VERSION ""

NS_ :

BS_:

BU_: HCM IPMA_ADAS PSCM ABS_ESC PCM ECM_HEV VDM CMR_DSMC SOBDMC_HPCM GWM _delete AWD_DLCM GENERIC TSTR
VAL_TABLE_ Dimming_Lvl_RqMnu 31 "NotUsed_11" 30 "NotUsed_10" 29 "NotUsed_9" 28 "NotUsed_8" 27 "NotUsed_7" 26 "NotUsed_6" 25 "NotUsed_5" 24 "NotUsed_4" 23 "NotUsed_3" 22 "NotUsed_2" 21 "NotUsed_1" 20 "Up" 19 "Down" 18 "Day_6" 17 "Day_5" 16 "Day_4" 15 "Day_3" 14 "Day_2" 13 "Day_1" 12 "Night_12" 11 "Night_11" 10 "Night_10" 9 "Night_9" 8 "Night_8" 7 "Night_7" 6 "Night_6" 5 "Night_5" 4 "Night_4" 3 "Night_3" 2 "Night_2" 1 "Night_1" 0 "NotPressed" ;
VAL_TABLE_ Null_Reset 1 "Reset" 0 "Null" ;
VAL_TABLE_ Null_Off_LowHigh 3 "High" 2 "Low" 1 "Off" 0 "Null" ;
VAL_TABLE_ Null_Off_On 3 "NotUsed" 2 "On" 1 "Off" 0 "Null" ;
VAL_TABLE_ NoData_Faulty_1FF_1FE 511 "Faulty" 510 "NoDataExists" ;
VAL_TABLE_ KeylessIdl_D_Rq 3 "Cancel" 2 "IgnitionOff" 1 "Active" 0 "Inactive" ;
VAL_TABLE_ KeyPadCodeDgt1_D_Stat 15 "NotUsed_4" 14 "NotUsed_3" 13 "NotUsed_2" 12 "NotUsed_1" 11 "Button7_8and9_0" 10 "Button0" 9 "Button9_0or9" 8 "Button8" 7 "Button7_8or7" 6 "Button6" 5 "Button5_6or5" 4 "Button4" 3 "Button3_4or3" 2 "Button2" 1 "Button1_2or1" 0 "EndofString" ;
VAL_TABLE_ Check_KeyCode 7 "Unused_2" 6 "Cancel" 5 "Set_Keycode" 4 "RKE" 3 "Null" 2 "Key" 1 "Erase_KeyCode" 0 "Check_KeyCode" ;
VAL_TABLE_ HybMdeGzg_D_Rq 7 "NotUsed_2" 6 "NotUsed_1" 5 "EV_Override_Mode" 4 "EV_Charge_Mode" 3 "EV_Later_Mode" 2 "EV_Now_Mode" 1 "EV_Auto_Mode" 0 "Null" ;
VAL_TABLE_ Null_NotAvail_Avail 3 "NotUsed" 2 "Available" 1 "NotAvailable" 0 "Null" ;

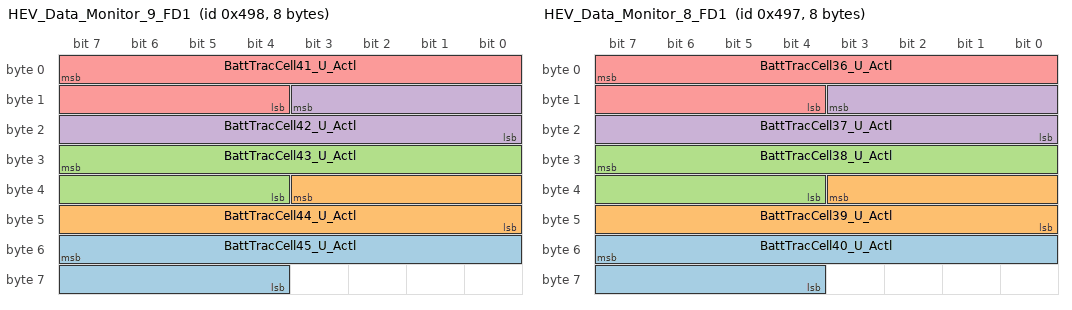
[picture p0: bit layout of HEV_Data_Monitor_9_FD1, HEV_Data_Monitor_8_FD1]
BO_ 1176 HEV_Data_Monitor_9_FD1: 8 GWM
 SG_ BattTracCell45_U_Actl : 55|12@0+ (0.001,1) [1|5.093] "volt"  SOBDMC_HPCM
 SG_ BattTracCell44_U_Actl : 35|12@0+ (0.001,1) [1|5.093] "volt"  SOBDMC_HPCM
 SG_ BattTracCell43_U_Actl : 31|12@0+ (0.001,1) [1|5.093] "volt"  SOBDMC_HPCM
 SG_ BattTracCell42_U_Actl : 11|12@0+ (0.001,1) [1|5.093] "volt"  SOBDMC_HPCM
 SG_ BattTracCell41_U_Actl : 7|12@0+ (0.001,1) [1|5.093] "volt"  SOBDMC_HPCM

BO_ 1175 HEV_Data_Monitor_8_FD1: 8 GWM
 SG_ BattTracCell40_U_Actl : 55|12@0+ (0.001,1) [1|5.093] "volt"  SOBDMC_HPCM
 SG_ BattTracCell39_U_Actl : 35|12@0+ (0.001,1) [1|5.093] "volt"  SOBDMC_HPCM
 SG_ BattTracCell38_U_Actl : 31|12@0+ (0.001,1) [1|5.093] "volt"  SOBDMC_HPCM
 SG_ BattTracCell37_U_Actl : 11|12@0+ (0.001,1) [1|5.093] "volt"  SOBDMC_HPCM
 SG_ BattTracCell36_U_Actl : 7|12@0+ (0.001,1) [1|5.093] "volt"  SOBDMC_HPCM

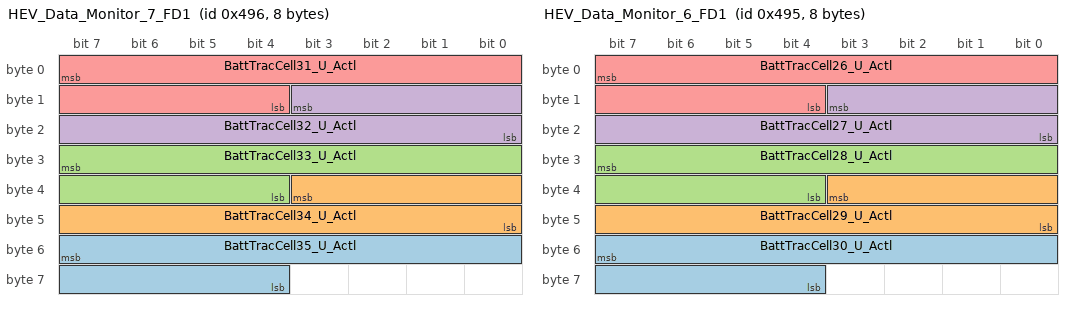
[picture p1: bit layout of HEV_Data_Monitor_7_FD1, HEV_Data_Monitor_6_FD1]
BO_ 1174 HEV_Data_Monitor_7_FD1: 8 GWM
 SG_ BattTracCell35_U_Actl : 55|12@0+ (0.001,1) [1|5.093] "volt"  SOBDMC_HPCM
 SG_ BattTracCell34_U_Actl : 35|12@0+ (0.001,1) [1|5.093] "volt"  SOBDMC_HPCM
 SG_ BattTracCell33_U_Actl : 31|12@0+ (0.001,1) [1|5.093] "volt"  SOBDMC_HPCM
 SG_ BattTracCell32_U_Actl : 11|12@0+ (0.001,1) [1|5.093] "volt"  SOBDMC_HPCM
 SG_ BattTracCell31_U_Actl : 7|12@0+ (0.001,1) [1|5.093] "volt"  SOBDMC_HPCM

BO_ 1173 HEV_Data_Monitor_6_FD1: 8 GWM
 SG_ BattTracCell30_U_Actl : 55|12@0+ (0.001,1) [1|5.093] "volt"  SOBDMC_HPCM
 SG_ BattTracCell29_U_Actl : 35|12@0+ (0.001,1) [1|5.093] "volt"  SOBDMC_HPCM
 SG_ BattTracCell28_U_Actl : 31|12@0+ (0.001,1) [1|5.093] "volt"  SOBDMC_HPCM
 SG_ BattTracCell27_U_Actl : 11|12@0+ (0.001,1) [1|5.093] "volt"  SOBDMC_HPCM
 SG_ BattTracCell26_U_Actl : 7|12@0+ (0.001,1) [1|5.093] "volt"  SOBDMC_HPCM

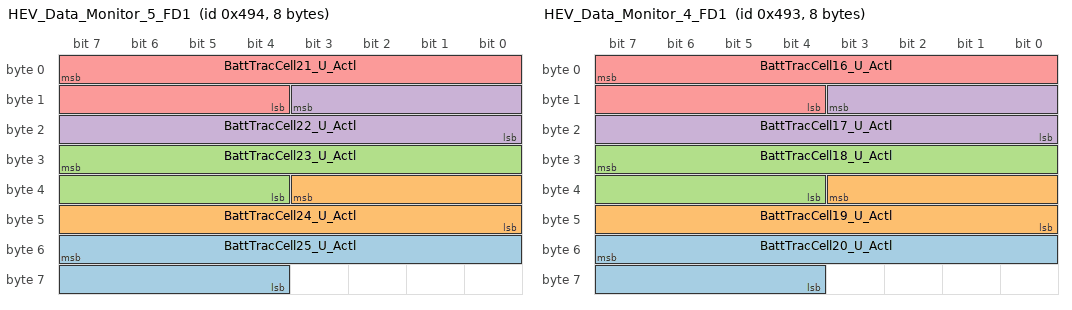
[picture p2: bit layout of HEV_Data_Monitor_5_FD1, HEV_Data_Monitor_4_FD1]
BO_ 1172 HEV_Data_Monitor_5_FD1: 8 GWM
 SG_ BattTracCell25_U_Actl : 55|12@0+ (0.001,1) [1|5.093] "volt"  SOBDMC_HPCM
 SG_ BattTracCell24_U_Actl : 35|12@0+ (0.001,1) [1|5.093] "volt"  SOBDMC_HPCM
 SG_ BattTracCell23_U_Actl : 31|12@0+ (0.001,1) [1|5.093] "volt"  SOBDMC_HPCM
 SG_ BattTracCell22_U_Actl : 11|12@0+ (0.001,1) [1|5.093] "volt"  SOBDMC_HPCM
 SG_ BattTracCell21_U_Actl : 7|12@0+ (0.001,1) [1|5.093] "volt"  SOBDMC_HPCM

BO_ 1171 HEV_Data_Monitor_4_FD1: 8 GWM
 SG_ BattTracCell20_U_Actl : 55|12@0+ (0.001,1) [1|5.093] "volt"  SOBDMC_HPCM
 SG_ BattTracCell19_U_Actl : 35|12@0+ (0.001,1) [1|5.093] "volt"  SOBDMC_HPCM
 SG_ BattTracCell18_U_Actl : 31|12@0+ (0.001,1) [1|5.093] "volt"  SOBDMC_HPCM
 SG_ BattTracCell17_U_Actl : 11|12@0+ (0.001,1) [1|5.093] "volt"  SOBDMC_HPCM
 SG_ BattTracCell16_U_Actl : 7|12@0+ (0.001,1) [1|5.093] "volt"  SOBDMC_HPCM

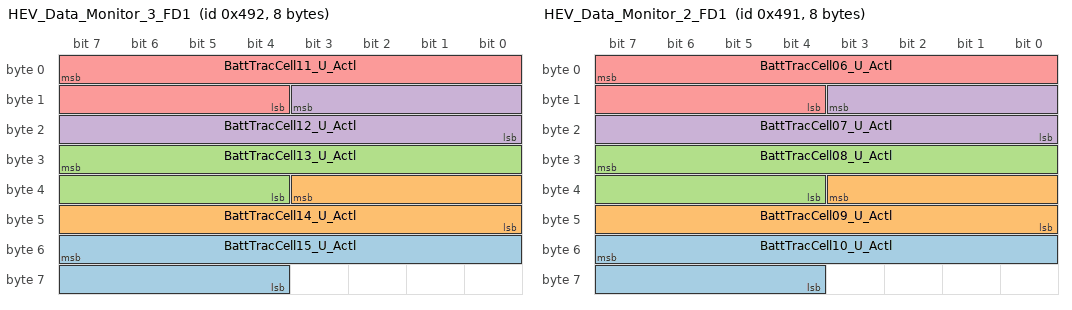
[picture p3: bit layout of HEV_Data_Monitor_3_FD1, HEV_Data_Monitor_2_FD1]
BO_ 1170 HEV_Data_Monitor_3_FD1: 8 GWM
 SG_ BattTracCell15_U_Actl : 55|12@0+ (0.001,1) [1|5.093] "volt"  SOBDMC_HPCM
 SG_ BattTracCell14_U_Actl : 35|12@0+ (0.001,1) [1|5.093] "volt"  SOBDMC_HPCM
 SG_ BattTracCell13_U_Actl : 31|12@0+ (0.001,1) [1|5.093] "volt"  SOBDMC_HPCM
 SG_ BattTracCell12_U_Actl : 11|12@0+ (0.001,1) [1|5.093] "volt"  SOBDMC_HPCM
 SG_ BattTracCell11_U_Actl : 7|12@0+ (0.001,1) [1|5.093] "volt"  SOBDMC_HPCM

BO_ 1169 HEV_Data_Monitor_2_FD1: 8 GWM
 SG_ BattTracCell10_U_Actl : 55|12@0+ (0.001,1) [1|5.093] "volt"  SOBDMC_HPCM
 SG_ BattTracCell09_U_Actl : 35|12@0+ (0.001,1) [1|5.093] "volt"  SOBDMC_HPCM
 SG_ BattTracCell08_U_Actl : 31|12@0+ (0.001,1) [1|5.093] "volt"  SOBDMC_HPCM
 SG_ BattTracCell07_U_Actl : 11|12@0+ (0.001,1) [1|5.093] "volt"  SOBDMC_HPCM
 SG_ BattTracCell06_U_Actl : 7|12@0+ (0.001,1) [1|5.093] "volt"  SOBDMC_HPCM

BO_ 1188 HEV_Data_Monitor_21_FD1: 8 GWM
 SG_ BattTracTe13_Te_Actl : 55|8@0+ (1,-50) [-50|203] "degC"  SOBDMC_HPCM
 SG_ BattTracTe12_Te_Actl : 47|8@0+ (1,-50) [-50|203] "degC"  SOBDMC_HPCM
 SG_ BattTracTe11_Te_Actl : 39|8@0+ (1,-50) [-50|203] "degC"  SOBDMC_HPCM
 SG_ BattTracTe10_Te_Actl : 31|8@0+ (1,-50) [-50|203] "degC"  SOBDMC_HPCM
 SG_ BattTracTe09_Te_Actl : 23|8@0+ (1,-50) [-50|203] "degC"  SOBDMC_HPCM
 SG_ BattTracTe08_Te_Actl : 15|8@0+ (1,-50) [-50|203] "degC"  SOBDMC_HPCM
 SG_ BattTracTe07_Te_Actl : 7|8@0+ (1,-50) [-50|203] "degC"  SOBDMC_HPCM

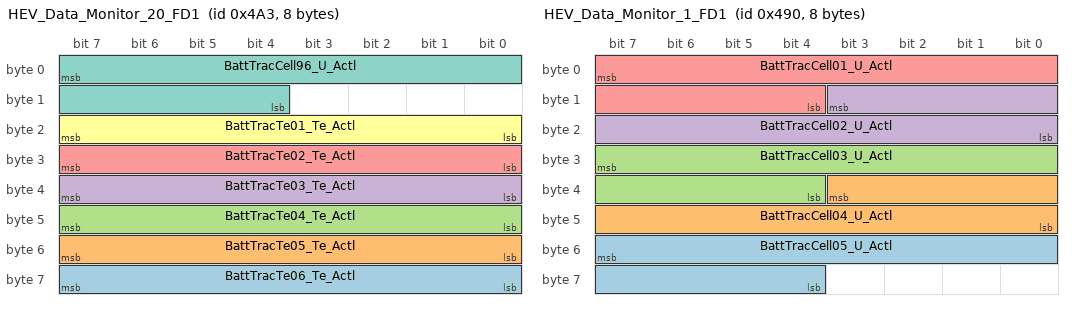
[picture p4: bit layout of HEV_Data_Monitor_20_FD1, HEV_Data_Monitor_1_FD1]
BO_ 1187 HEV_Data_Monitor_20_FD1: 8 GWM
 SG_ BattTracTe06_Te_Actl : 63|8@0+ (1,-50) [-50|203] "degC"  SOBDMC_HPCM
 SG_ BattTracTe05_Te_Actl : 55|8@0+ (1,-50) [-50|203] "degC"  SOBDMC_HPCM
 SG_ BattTracTe04_Te_Actl : 47|8@0+ (1,-50) [-50|203] "degC"  SOBDMC_HPCM
 SG_ BattTracTe03_Te_Actl : 39|8@0+ (1,-50) [-50|203] "degC"  SOBDMC_HPCM
 SG_ BattTracTe02_Te_Actl : 31|8@0+ (1,-50) [-50|203] "degC"  SOBDMC_HPCM
 SG_ BattTracTe01_Te_Actl : 23|8@0+ (1,-50) [-50|203] "degC"  SOBDMC_HPCM
 SG_ BattTracCell96_U_Actl : 7|12@0+ (0.001,1) [1|5.093] "volt"  SOBDMC_HPCM

BO_ 1168 HEV_Data_Monitor_1_FD1: 8 GWM
 SG_ BattTracCell05_U_Actl : 55|12@0+ (0.001,1) [1|5.093] "volt"  SOBDMC_HPCM
 SG_ BattTracCell04_U_Actl : 35|12@0+ (0.001,1) [1|5.093] "volt"  SOBDMC_HPCM
 SG_ BattTracCell03_U_Actl : 31|12@0+ (0.001,1) [1|5.093] "volt"  SOBDMC_HPCM
 SG_ BattTracCell02_U_Actl : 11|12@0+ (0.001,1) [1|5.093] "volt"  SOBDMC_HPCM
 SG_ BattTracCell01_U_Actl : 7|12@0+ (0.001,1) [1|5.093] "volt"  SOBDMC_HPCM

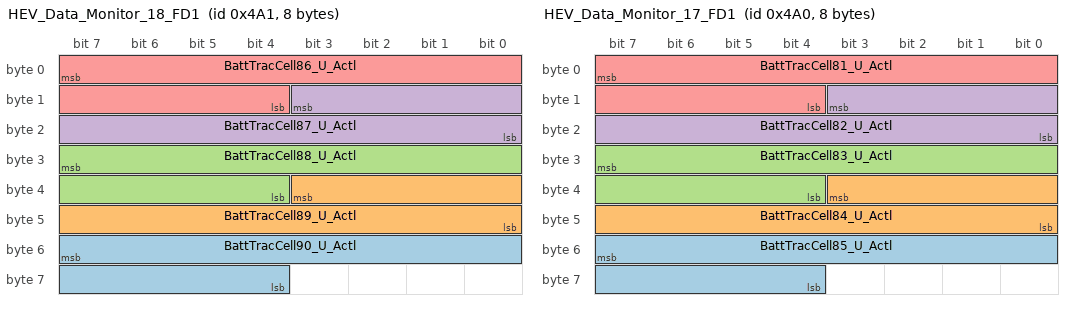
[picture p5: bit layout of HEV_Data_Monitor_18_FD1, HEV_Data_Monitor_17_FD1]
BO_ 1185 HEV_Data_Monitor_18_FD1: 8 GWM
 SG_ BattTracCell90_U_Actl : 55|12@0+ (0.001,1) [1|5.093] "volt"  SOBDMC_HPCM
 SG_ BattTracCell89_U_Actl : 35|12@0+ (0.001,1) [1|5.093] "volt"  SOBDMC_HPCM
 SG_ BattTracCell88_U_Actl : 31|12@0+ (0.001,1) [1|5.093] "volt"  SOBDMC_HPCM
 SG_ BattTracCell87_U_Actl : 11|12@0+ (0.001,1) [1|5.093] "volt"  SOBDMC_HPCM
 SG_ BattTracCell86_U_Actl : 7|12@0+ (0.001,1) [1|5.093] "volt"  SOBDMC_HPCM

BO_ 1184 HEV_Data_Monitor_17_FD1: 8 GWM
 SG_ BattTracCell85_U_Actl : 55|12@0+ (0.001,1) [1|5.093] "volt"  SOBDMC_HPCM
 SG_ BattTracCell84_U_Actl : 35|12@0+ (0.001,1) [1|5.093] "volt"  SOBDMC_HPCM
 SG_ BattTracCell83_U_Actl : 31|12@0+ (0.001,1) [1|5.093] "volt"  SOBDMC_HPCM
 SG_ BattTracCell82_U_Actl : 11|12@0+ (0.001,1) [1|5.093] "volt"  SOBDMC_HPCM
 SG_ BattTracCell81_U_Actl : 7|12@0+ (0.001,1) [1|5.093] "volt"  SOBDMC_HPCM

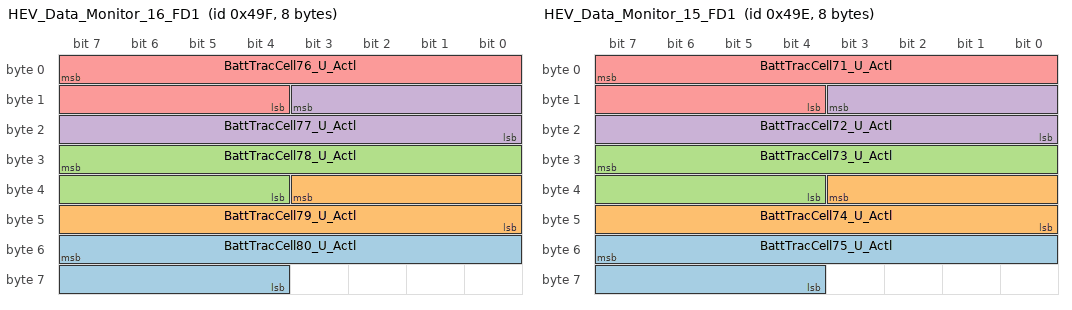
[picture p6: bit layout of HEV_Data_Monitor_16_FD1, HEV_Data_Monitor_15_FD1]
BO_ 1183 HEV_Data_Monitor_16_FD1: 8 GWM
 SG_ BattTracCell80_U_Actl : 55|12@0+ (0.001,1) [1|5.093] "volt"  SOBDMC_HPCM
 SG_ BattTracCell79_U_Actl : 35|12@0+ (0.001,1) [1|5.093] "volt"  SOBDMC_HPCM
 SG_ BattTracCell78_U_Actl : 31|12@0+ (0.001,1) [1|5.093] "volt"  SOBDMC_HPCM
 SG_ BattTracCell77_U_Actl : 11|12@0+ (0.001,1) [1|5.093] "volt"  SOBDMC_HPCM
 SG_ BattTracCell76_U_Actl : 7|12@0+ (0.001,1) [1|5.093] "volt"  SOBDMC_HPCM

BO_ 1182 HEV_Data_Monitor_15_FD1: 8 GWM
 SG_ BattTracCell75_U_Actl : 55|12@0+ (0.001,1) [1|5.093] "volt"  SOBDMC_HPCM
 SG_ BattTracCell74_U_Actl : 35|12@0+ (0.001,1) [1|5.093] "volt"  SOBDMC_HPCM
 SG_ BattTracCell73_U_Actl : 31|12@0+ (0.001,1) [1|5.093] "volt"  SOBDMC_HPCM
 SG_ BattTracCell72_U_Actl : 11|12@0+ (0.001,1) [1|5.093] "volt"  SOBDMC_HPCM
 SG_ BattTracCell71_U_Actl : 7|12@0+ (0.001,1) [1|5.093] "volt"  SOBDMC_HPCM

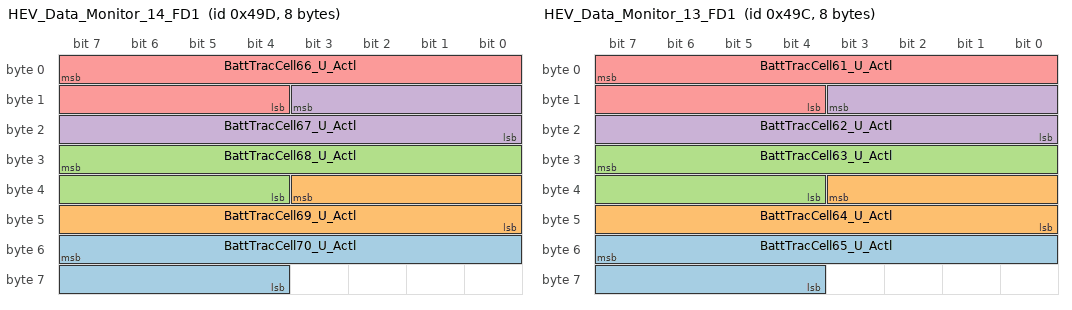
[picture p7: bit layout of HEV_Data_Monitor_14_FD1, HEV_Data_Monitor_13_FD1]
BO_ 1181 HEV_Data_Monitor_14_FD1: 8 GWM
 SG_ BattTracCell70_U_Actl : 55|12@0+ (0.001,1) [1|5.093] "volt"  SOBDMC_HPCM
 SG_ BattTracCell69_U_Actl : 35|12@0+ (0.001,1) [1|5.093] "volt"  SOBDMC_HPCM
 SG_ BattTracCell68_U_Actl : 31|12@0+ (0.001,1) [1|5.093] "volt"  SOBDMC_HPCM
 SG_ BattTracCell67_U_Actl : 11|12@0+ (0.001,1) [1|5.093] "volt"  SOBDMC_HPCM
 SG_ BattTracCell66_U_Actl : 7|12@0+ (0.001,1) [1|5.093] "volt"  SOBDMC_HPCM

BO_ 1180 HEV_Data_Monitor_13_FD1: 8 GWM
 SG_ BattTracCell65_U_Actl : 55|12@0+ (0.001,1) [1|5.093] "volt"  SOBDMC_HPCM
 SG_ BattTracCell64_U_Actl : 35|12@0+ (0.001,1) [1|5.093] "volt"  SOBDMC_HPCM
 SG_ BattTracCell63_U_Actl : 31|12@0+ (0.001,1) [1|5.093] "volt"  SOBDMC_HPCM
 SG_ BattTracCell62_U_Actl : 11|12@0+ (0.001,1) [1|5.093] "volt"  SOBDMC_HPCM
 SG_ BattTracCell61_U_Actl : 7|12@0+ (0.001,1) [1|5.093] "volt"  SOBDMC_HPCM

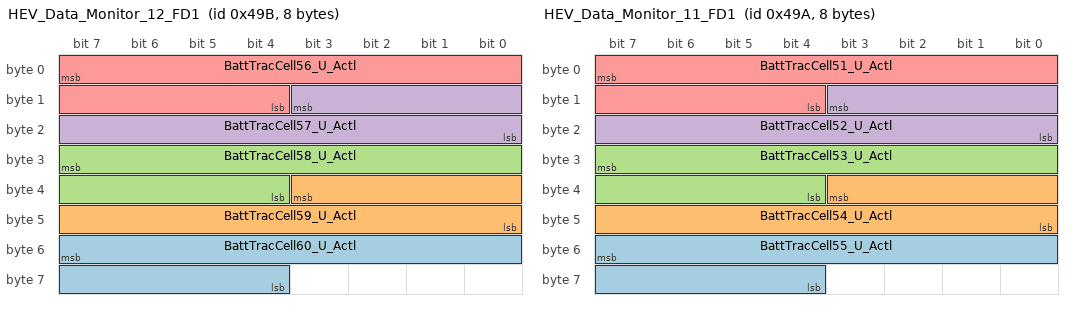
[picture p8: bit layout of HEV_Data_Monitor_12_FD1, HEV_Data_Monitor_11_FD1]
BO_ 1179 HEV_Data_Monitor_12_FD1: 8 GWM
 SG_ BattTracCell60_U_Actl : 55|12@0+ (0.001,1) [1|5.093] "volt"  SOBDMC_HPCM
 SG_ BattTracCell59_U_Actl : 35|12@0+ (0.001,1) [1|5.093] "volt"  SOBDMC_HPCM
 SG_ BattTracCell58_U_Actl : 31|12@0+ (0.001,1) [1|5.093] "volt"  SOBDMC_HPCM
 SG_ BattTracCell57_U_Actl : 11|12@0+ (0.001,1) [1|5.093] "volt"  SOBDMC_HPCM
 SG_ BattTracCell56_U_Actl : 7|12@0+ (0.001,1) [1|5.093] "volt"  SOBDMC_HPCM

BO_ 1178 HEV_Data_Monitor_11_FD1: 8 GWM
 SG_ BattTracCell55_U_Actl : 55|12@0+ (0.001,1) [1|5.093] "volt"  SOBDMC_HPCM
 SG_ BattTracCell54_U_Actl : 35|12@0+ (0.001,1) [1|5.093] "volt"  SOBDMC_HPCM
 SG_ BattTracCell53_U_Actl : 31|12@0+ (0.001,1) [1|5.093] "volt"  SOBDMC_HPCM
 SG_ BattTracCell52_U_Actl : 11|12@0+ (0.001,1) [1|5.093] "volt"  SOBDMC_HPCM
 SG_ BattTracCell51_U_Actl : 7|12@0+ (0.001,1) [1|5.093] "volt"  SOBDMC_HPCM

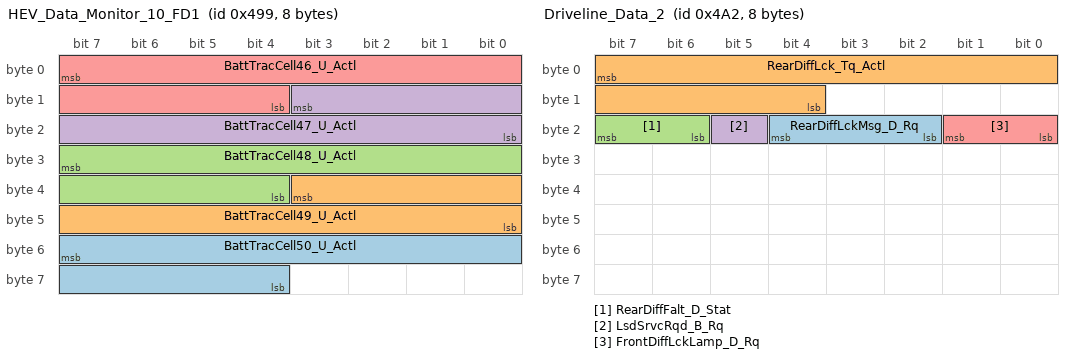
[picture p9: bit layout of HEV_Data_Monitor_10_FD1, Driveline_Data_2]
BO_ 1177 HEV_Data_Monitor_10_FD1: 8 GWM
 SG_ BattTracCell50_U_Actl : 55|12@0+ (0.001,1) [1|5.093] "volt"  SOBDMC_HPCM
 SG_ BattTracCell49_U_Actl : 35|12@0+ (0.001,1) [1|5.093] "volt"  SOBDMC_HPCM
 SG_ BattTracCell48_U_Actl : 31|12@0+ (0.001,1) [1|5.093] "volt"  SOBDMC_HPCM
 SG_ BattTracCell47_U_Actl : 11|12@0+ (0.001,1) [1|5.093] "volt"  SOBDMC_HPCM
 SG_ BattTracCell46_U_Actl : 7|12@0+ (0.001,1) [1|5.093] "volt"  SOBDMC_HPCM

BO_ 1186 Driveline_Data_2: 8 SOBDMC_HPCM
 SG_ RearDiffLckMsg_D_Rq : 20|3@0+ (1,0) [0|7] "SED"  GWM
 SG_ RearDiffLck_Tq_Actl : 7|12@0+ (1,0) [0|4093] "Nm"  GWM
 SG_ RearDiffFalt_D_Stat : 23|2@0+ (1,0) [0|3] "SED"  GWM
 SG_ LsdSrvcRqd_B_Rq : 21|1@0+ (1,0) [0|1] "SED"  GWM
 SG_ FrontDiffLckLamp_D_Rq : 17|2@0+ (1,0) [0|3] "SED"  GWM

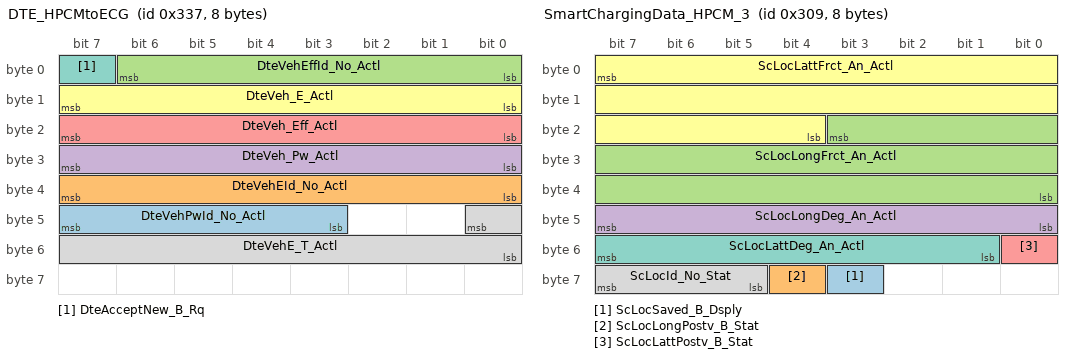
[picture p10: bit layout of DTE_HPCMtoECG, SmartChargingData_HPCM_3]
BO_ 823 DTE_HPCMtoECG: 8 SOBDMC_HPCM
 SG_ DteVehPwId_No_Actl : 47|5@0+ (1,0) [0|31] "unitless"  GWM
 SG_ DteVehEId_No_Actl : 39|8@0+ (1,0) [0|255] "unitless"  GWM
 SG_ DteVehEffId_No_Actl : 6|7@0+ (1,0) [0|127] "unitless"  GWM
 SG_ DteVeh_Pw_Actl : 31|8@0+ (50,0) [0|12750] "watts"  GWM
 SG_ DteVeh_Eff_Actl : 23|8@0+ (10,-1000) [-1000|1550] "watt*hour/km"  GWM
 SG_ DteVeh_E_Actl : 15|8@0+ (100,0) [0|25500] "watt*hour"  GWM
 SG_ DteAcceptNew_B_Rq : 7|1@0+ (1,0) [0|1] "SED"  GWM
 SG_ DteVehE_T_Actl : 40|9@0+ (10,0) [0|5110] "second"  GWM

BO_ 777 SmartChargingData_HPCM_3: 8 SOBDMC_HPCM
 SG_ ScLocSaved_B_Dsply : 59|1@0+ (1,0) [0|1] "SED"  GWM
 SG_ ScLocLongPostv_B_Stat : 60|1@0+ (1,0) [0|1] "SED"  GWM
 SG_ ScLocLongFrct_An_Actl : 19|20@0+ (1E-006,0) [0|1.048575] "degrees"  GWM
 SG_ ScLocLongDeg_An_Actl : 47|8@0+ (1,0) [0|255] "degrees"  GWM
 SG_ ScLocLattPostv_B_Stat : 48|1@0+ (1,0) [0|1] "SED"  GWM
 SG_ ScLocLattFrct_An_Actl : 7|20@0+ (1E-006,0) [0|1.048575] "degrees"  GWM
 SG_ ScLocLattDeg_An_Actl : 55|7@0+ (1,0) [0|127] "degrees"  GWM
 SG_ ScLocId_No_Stat : 63|3@0+ (1,0) [0|7] "unitless"  GWM

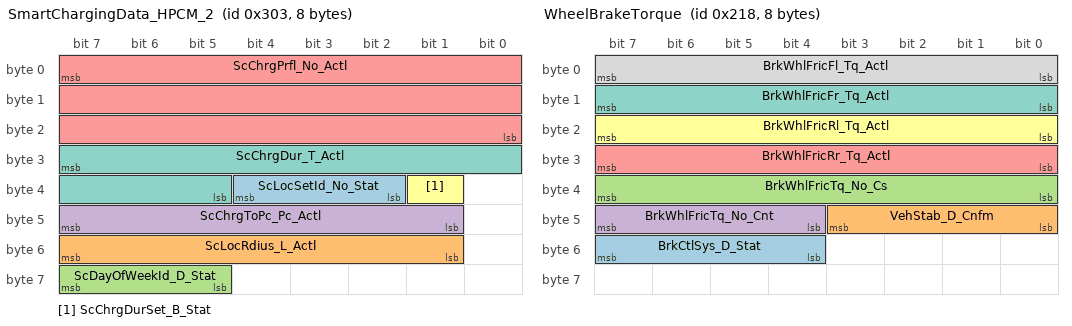
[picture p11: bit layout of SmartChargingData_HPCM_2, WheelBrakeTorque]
BO_ 771 SmartChargingData_HPCM_2: 8 SOBDMC_HPCM
 SG_ ScLocSetId_No_Stat : 36|3@0+ (1,0) [0|7] "unitless"  GWM
 SG_ ScLocRdius_L_Actl : 55|7@0+ (100,0) [0|12700] "meter"  GWM
 SG_ ScDayOfWeekId_D_Stat : 63|3@0+ (1,0) [0|7] "SED"  GWM
 SG_ ScChrgToPc_Pc_Actl : 47|7@0+ (1,0) [0|127] "percent"  GWM
 SG_ ScChrgPrfl_No_Actl : 7|24@0+ (1,0) [0|16777215] "unitless"  GWM
 SG_ ScChrgDurSet_B_Stat : 33|1@0+ (1,0) [0|1] "SED"  GWM
 SG_ ScChrgDur_T_Actl : 31|11@0+ (1,0) [0|2047] "minute"  GWM

BO_ 513 Cluster_HEV_Data11_FD1: 8 SOBDMC_HPCM
 SG_ ChrgStat_D3_Dsply : 31|5@0+ (1,0) [0|31] "SED"  GWM

BO_ 368 PowertrainData_4: 8 SOBDMC_HPCM
 SG_ PrplBrkTqCtl_No_Cs : 7|8@0+ (1,0) [0|255] "Unitless"  GWM
 SG_ PrplBrkTqCtl_No_Cnt : 15|4@0+ (1,0) [0|15] "Unitless"  GWM
 SG_ PrplWhlTot_Tq_RqFilt : 23|16@0+ (4,-131072) [-131072|131060] "Nm"  GWM

BO_ 536 WheelBrakeTorque: 8 ABS_ESC
 SG_ BrkCtlSys_D_Stat : 55|4@0+ (1,0) [0|15] "SED"  SOBDMC_HPCM
 SG_ VehStab_D_Cnfm : 43|4@0+ (1,0) [0|15] "SED"  SOBDMC_HPCM
 SG_ BrkWhlFricTq_No_Cs : 39|8@0+ (1,0) [0|255] "Unitless"  SOBDMC_HPCM
 SG_ BrkWhlFricTq_No_Cnt : 47|4@0+ (1,0) [0|15] "Unitless"  SOBDMC_HPCM
 SG_ BrkWhlFricRr_Tq_Actl : 31|8@0+ (20,0) [0|5060] "Nm"  SOBDMC_HPCM
 SG_ BrkWhlFricRl_Tq_Actl : 23|8@0+ (20,0) [0|5060] "Nm"  SOBDMC_HPCM
 SG_ BrkWhlFricFr_Tq_Actl : 15|8@0+ (20,0) [0|5060] "Nm"  SOBDMC_HPCM
 SG_ BrkWhlFricFl_Tq_Actl : 7|8@0+ (20,0) [0|5060] "Nm"  SOBDMC_HPCM

BO_ 66 Global_PATS_Ctrl_Info2_FD1: 8 GWM
 SG_ immoControlData_T2 : 15|40@0+ (1,0) [0|1099511627775] "Encrypted" Vector__XXX
 SG_ immoControlCmd_T2 : 7|3@0+ (1,0) [0|7] "SED" Vector__XXX

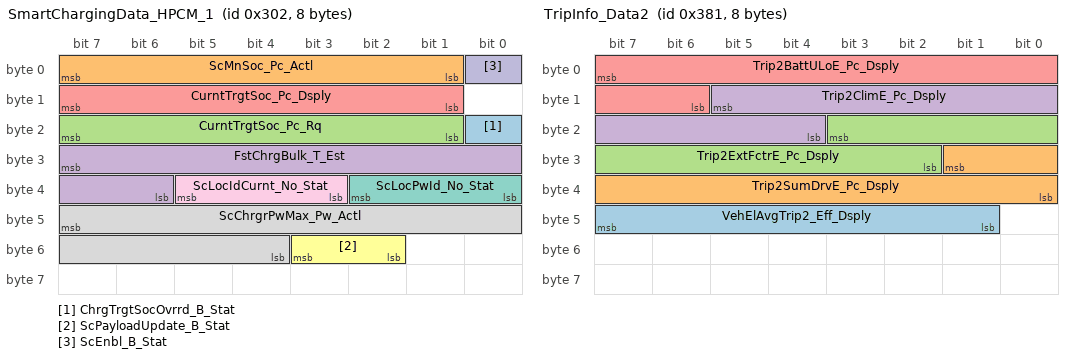
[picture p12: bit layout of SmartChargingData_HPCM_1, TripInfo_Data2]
BO_ 770 SmartChargingData_HPCM_1: 8 SOBDMC_HPCM
 SG_ ChrgTrgtSocOvrrd_B_Stat : 16|1@0+ (1,0) [0|1] "SED"  GWM
 SG_ ScMnSoc_Pc_Actl : 7|7@0+ (1,0) [0|127] "percent"  GWM
 SG_ CurntTrgtSoc_Pc_Rq : 23|7@0+ (1,0) [0|127] "percent"  GWM
 SG_ FstChrgBulk_T_Est : 31|10@0+ (1,0) [0|1023] "minute"  GWM
 SG_ CurntTrgtSoc_Pc_Dsply : 15|7@0+ (1,0) [0|127] "percent"  GWM
 SG_ ScPayloadUpdate_B_Stat : 51|2@0+ (1,0) [0|3] "SED"  GWM
 SG_ ScLocPwId_No_Stat : 34|3@0+ (1,0) [0|7] "unitless"  GWM
 SG_ ScChrgrPwMax_Pw_Actl : 47|12@0+ (50,0) [0|204700] "watts"  GWM
 SG_ ScLocIdCurnt_No_Stat : 37|3@0+ (1,0) [0|7] "unitless"  GWM
 SG_ ScEnbl_B_Stat : 0|1@0+ (1,0) [0|1] "SED"  GWM

BO_ 897 TripInfo_Data2: 8 SOBDMC_HPCM
 SG_ VehElAvgTrip2_Eff_Dsply : 47|7@0+ (10,-100) [-100|1150] "wattHr/km"  GWM
 SG_ Trip2SumDrvE_Pc_Dsply : 25|10@0+ (0.1,0) [0|102.1] "percent"  GWM
 SG_ Trip2ExtFctrE_Pc_Dsply : 19|10@0+ (0.1,0) [0|102.1] "percent"  GWM
 SG_ Trip2ClimE_Pc_Dsply : 13|10@0+ (0.1,0) [0|102.1] "percent"  GWM
 SG_ Trip2BattULoE_Pc_Dsply : 7|10@0+ (0.1,0) [0|102.1] "percent"  GWM

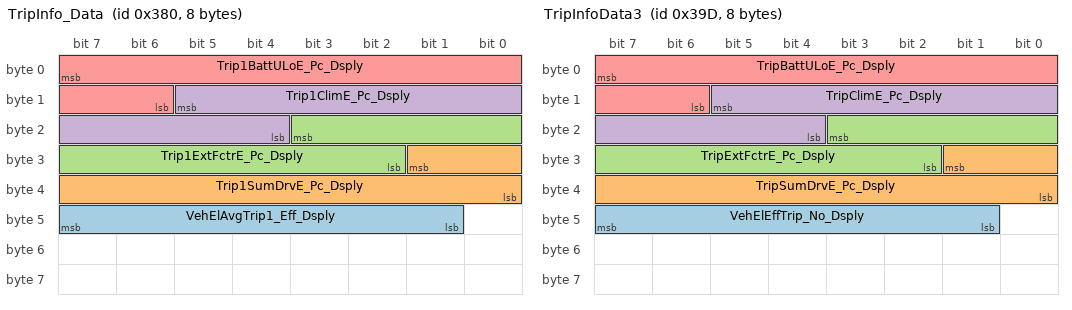
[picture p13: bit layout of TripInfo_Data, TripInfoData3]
BO_ 896 TripInfo_Data: 8 SOBDMC_HPCM
 SG_ VehElAvgTrip1_Eff_Dsply : 47|7@0+ (10,-100) [-100|1150] "wattHr/km"  GWM
 SG_ Trip1SumDrvE_Pc_Dsply : 25|10@0+ (0.1,0) [0|102.1] "percent"  GWM
 SG_ Trip1ExtFctrE_Pc_Dsply : 19|10@0+ (0.1,0) [0|102.1] "percent"  GWM
 SG_ Trip1ClimE_Pc_Dsply : 13|10@0+ (0.1,0) [0|102.1] "percent"  GWM
 SG_ Trip1BattULoE_Pc_Dsply : 7|10@0+ (0.1,0) [0|102.1] "percent"  GWM

BO_ 925 TripInfoData3: 8 SOBDMC_HPCM
 SG_ VehElEffTrip_No_Dsply : 47|7@0+ (10,-100) [-100|1150] "wattHr/km"  GWM
 SG_ TripSumDrvE_Pc_Dsply : 25|10@0+ (0.1,0) [0|102.1] "percent"  GWM
 SG_ TripExtFctrE_Pc_Dsply : 19|10@0+ (0.1,0) [0|102.1] "percent"  GWM
 SG_ TripClimE_Pc_Dsply : 13|10@0+ (0.1,0) [0|102.1] "percent"  GWM
 SG_ TripBattULoE_Pc_Dsply : 7|10@0+ (0.1,0) [0|102.1] "percent"  GWM

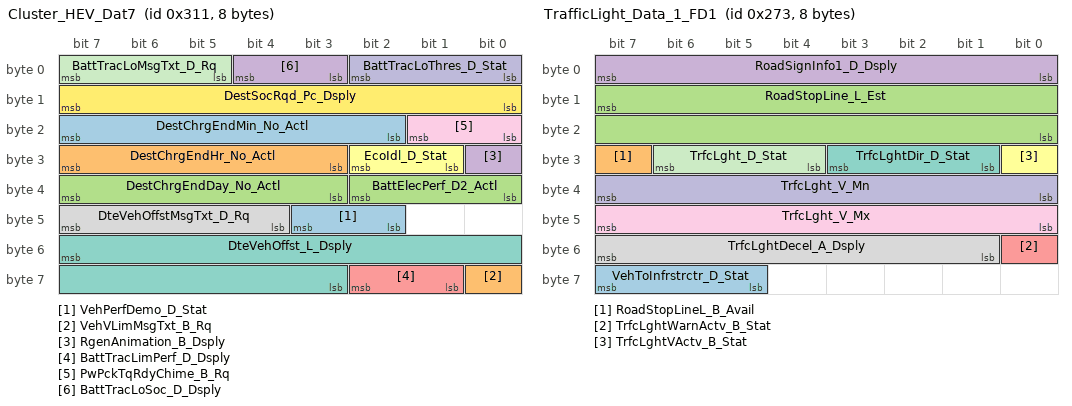
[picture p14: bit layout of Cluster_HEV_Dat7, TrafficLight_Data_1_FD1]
BO_ 785 Cluster_HEV_Dat7: 8 SOBDMC_HPCM
 SG_ VehPerfDemo_D_Stat : 43|2@0+ (1,0) [0|3] "SED"  GWM
 SG_ VehVLimMsgTxt_B_Rq : 56|1@0+ (1,0) [0|1] "SED"  GWM
 SG_ BattElecPerf_D2_Actl : 34|3@0+ (1,0) [0|7] "SED"  GWM
 SG_ RgenAnimation_B_Dsply : 24|1@0+ (1,0) [0|1] "SED"  GWM
 SG_ BattTracLimPerf_D_Dsply : 58|2@0+ (1,0) [0|3] "SED"  GWM
 SG_ EcoIdl_D_Stat : 26|2@0+ (1,0) [0|3] "SED"  GWM
 SG_ DteVehOffst_L_Dsply : 55|13@0+ (0.1,-400) [-400|418.9] "kilometer"  GWM
 SG_ DteVehOffstMsgTxt_D_Rq : 47|4@0+ (1,0) [0|15] "SED"  GWM
 SG_ PwPckTqRdyChime_B_Rq : 17|2@0+ (1,0) [0|3] "SED"  GWM
 SG_ BattTracLoThres_D_Stat : 2|3@0+ (1,0) [0|7] "SED"  GWM
 SG_ BattTracLoMsgTxt_D_Rq : 7|3@0+ (1,0) [0|7] "SED"  GWM
 SG_ DestSocRqd_Pc_Dsply : 15|8@0+ (0.5,0) [0|127.5] "percent"  GWM
 SG_ DestChrgEndMin_No_Actl : 23|6@0+ (1,0) [0|63] "Minutes"  GWM
 SG_ DestChrgEndHr_No_Actl : 31|5@0+ (1,0) [0|31] "Hours"  GWM
 SG_ DestChrgEndDay_No_Actl : 39|5@0+ (1,0) [1|31] "days"  GWM
 SG_ BattTracLoSoc_D_Dsply : 4|2@0+ (1,0) [0|3] "SED"  GWM

BO_ 932 Body_Info_13: 8 GWM
 SG_ VehOnSrc2_D_Stat : 20|4@0+ (1,0) [0|15] "SED"  IPMA_ADAS

BO_ 816 APIM_Send_Signals_3_FD1: 8 GWM
 SG_ HybMdeSel_D_Rq : 58|3@0+ (1,0) [0|7] "SED"  PCM,SOBDMC_HPCM

BO_ 646 Battery_Traction_13_FD1: 8 GWM
 SG_ BattTrac3_Pw_LimDchrg : 55|16@0+ (50,0) [0|3276750] "watts" Vector__XXX
 SG_ BattTrac3_Pw_LimChrg : 39|16@0+ (50,0) [0|3276750] "watts" Vector__XXX
 SG_ BattTrac3_Pw_DchrgInst : 23|16@0+ (50,0) [0|3276750] "watts" Vector__XXX
 SG_ BattTrac3_Pw_ChrgInst : 7|16@0+ (50,0) [0|3276750] "watts" Vector__XXX

BO_ 627 TrafficLight_Data_1_FD1: 8 GWM
 SG_ VehToInfrstrctr_D_Stat : 63|3@0+ (1,0) [0|7] "SED"  PCM
 SG_ RoadStopLineL_B_Avail : 31|1@0+ (1,0) [0|1] "SED"  PCM
 SG_ RoadStopLine_L_Est : 15|16@0+ (1,0) [0|65533] "cm"  PCM
 SG_ RoadSignInfo1_D_Dsply : 7|8@0+ (1,0) [0|255] "SED"  PCM
 SG_ TrfcLghtWarnActv_B_Stat : 48|1@0+ (1,0) [0|1] "SED"  PCM
 SG_ TrfcLghtVActv_B_Stat : 24|1@0+ (1,0) [0|1] "SED"  PCM
 SG_ TrfcLghtDir_D_Stat : 27|3@0+ (1,0) [0|7] "SED"  PCM
 SG_ TrfcLghtDecel_A_Dsply : 55|7@0+ (1,0) [0|125] "km/hour"  PCM
 SG_ TrfcLght_V_Mx : 47|8@0+ (1,0) [0|253] "km/hour"  PCM
 SG_ TrfcLght_V_Mn : 39|8@0+ (1,0) [0|253] "km/hour"  PCM
 SG_ TrfcLght_D_Stat : 30|3@0+ (1,0) [0|7] "SED"  PCM

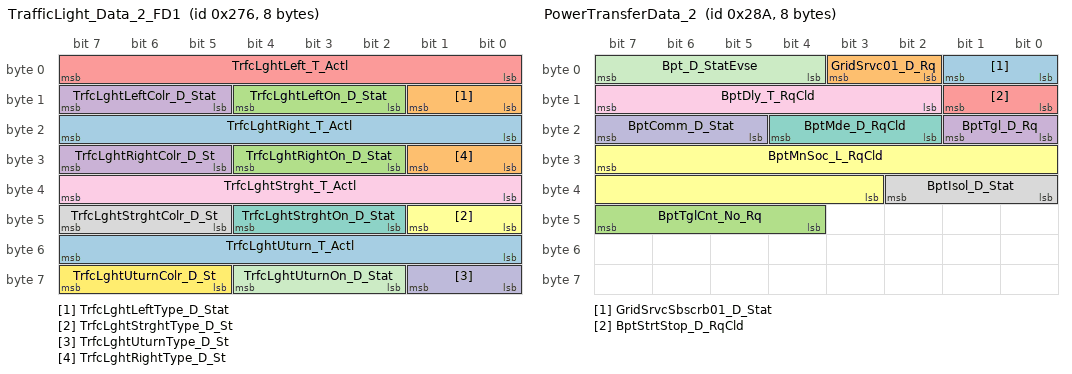
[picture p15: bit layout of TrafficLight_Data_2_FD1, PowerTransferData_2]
BO_ 630 TrafficLight_Data_2_FD1: 8 GWM
 SG_ TrfcLghtRight_T_Actl : 23|8@0+ (1,0) [0|253] "second"  PCM
 SG_ TrfcLghtLeftType_D_Stat : 9|2@0+ (1,0) [0|3] "SED"  PCM
 SG_ TrfcLghtLeftOn_D_Stat : 12|3@0+ (1,0) [0|7] "SED"  PCM
 SG_ TrfcLghtLeftColr_D_Stat : 15|3@0+ (1,0) [0|7] "SED"  PCM
 SG_ TrfcLghtLeft_T_Actl : 7|8@0+ (1,0) [0|253] "second"  PCM
 SG_ TrfcLghtStrghtType_D_St : 41|2@0+ (1,0) [0|3] "SED"  PCM
 SG_ TrfcLghtStrghtOn_D_Stat : 44|3@0+ (1,0) [0|7] "SED"  PCM
 SG_ TrfcLghtStrghtColr_D_St : 47|3@0+ (1,0) [0|7] "SED"  PCM
 SG_ TrfcLghtStrght_T_Actl : 39|8@0+ (1,0) [0|253] "second"  PCM
 SG_ TrfcLghtUturnType_D_St : 57|2@0+ (1,0) [0|3] "SED"  PCM
 SG_ TrfcLghtUturnOn_D_Stat : 60|3@0+ (1,0) [0|7] "SED"  PCM
 SG_ TrfcLghtUturnColr_D_St : 63|3@0+ (1,0) [0|7] "SED"  PCM
 SG_ TrfcLghtUturn_T_Actl : 55|8@0+ (1,0) [0|253] "second"  PCM
 SG_ TrfcLghtRightType_D_St : 25|2@0+ (1,0) [0|3] "SED"  PCM
 SG_ TrfcLghtRightOn_D_Stat : 28|3@0+ (1,0) [0|7] "SED"  PCM
 SG_ TrfcLghtRightColr_D_St : 31|3@0+ (1,0) [0|7] "SED"  PCM

BO_ 650 PowerTransferData_2: 8 GWM
 SG_ GridSrvcSbscrb01_D_Stat : 1|2@0+ (1,0) [0|3] "SED" Vector__XXX
 SG_ GridSrvc01_D_Rq : 3|2@0+ (1,0) [0|3] "SED" Vector__XXX
 SG_ BptTglCnt_No_Rq : 47|4@0+ (1,0) [0|13] "unitless" Vector__XXX
 SG_ BptTgl_D_Rq : 17|2@0+ (1,0) [0|3] "SED" Vector__XXX
 SG_ BptStrtStop_D_RqCld : 9|2@0+ (1,0) [0|3] "SED" Vector__XXX
 SG_ BptMnSoc_L_RqCld : 31|13@0+ (0.1,0) [0|818.9] "kilometer" Vector__XXX
 SG_ BptMde_D_RqCld : 20|3@0+ (1,0) [0|7] "SED" Vector__XXX
 SG_ BptIsol_D_Stat : 34|3@0+ (1,0) [0|7] "SED" Vector__XXX
 SG_ BptDly_T_RqCld : 15|6@0+ (0.5,0) [0|30.5] "minute" Vector__XXX
 SG_ BptComm_D_Stat : 23|3@0+ (1,0) [0|7] "SED" Vector__XXX
 SG_ Bpt_D_StatEvse : 7|4@0+ (1,0) [0|15] "SED" Vector__XXX

BO_ 655 ECG_Data5_FD1: 8 GWM
 SG_ EvseChrgOutHi_U_ActlBpt : 42|10@0+ (0.5,0) [0|510.5] "volt" Vector__XXX
 SG_ EvseChrgOutHi_I_ActlBpt : 25|15@0+ (0.05,-750) [-750|888.25] "ampere" Vector__XXX
 SG_ EvseDchrg_Pw_Mx : 8|15@0+ (50,0) [0|1638250] "wattS" Vector__XXX
 SG_ EvseDchrg_I_Mx : 7|15@0+ (0.05,0) [0|1638.25] "ampere" Vector__XXX

BO_ 599 Battery_Traction_12_FD1: 8 GWM
 SG_ Bpt_D_StatBattTrac : 7|3@0+ (1,0) [0|7] "SED" Vector__XXX

BO_ 595 APIM_Send_Signals_7_FD1: 8 GWM
 SG_ DrvIdMde_D_Rq : 7|3@0+ (1,0) [0|7] "SED"  GENERIC
 SG_ DrvIdDelete_No_Rq : 15|32@0+ (1,0) [0|4294967295] "Unitless"  GENERIC

BO_ 2611034328 PARSEDPhysGWM_ECGtoLDCMB: 64 GWM
 SG_ PARSEDPhysGWM_ECGtoLDCMB : 7|29@0+ (1,0) [0|536870911] "unitless"  HCM

BO_ 2611035352 PARSEDPhysGWM_ECGtoLDCMA: 64 GWM
 SG_ PARSEDPhysGWM_ECGtoLDCMA : 7|29@0+ (1,0) [0|536870911] "unitless"  HCM

BO_ 2611175502 PARSEDPhysLDCMBtoGWM_ECG: 64 HCM
 SG_ PARSEDPhysLDCMBtoGWM_ECG : 7|29@0+ (1,0) [0|536870911] "Unitless"  GWM

BO_ 2611175503 PARSEDPhysLDCMAtoGWM_ECG: 64 HCM
 SG_ PARSEDPhysLDCMAtoGWM_ECG : 7|29@0+ (1,0) [0|536870911] "unitless"  GWM

BO_ 2612224078 PARSEDPushLDCMBtoGWM_ECG: 8 HCM
 SG_ PARSEDPushLDCMBtoGWM_ECG : 7|29@0+ (1,0) [0|536870911] "unitless"  GWM

BO_ 2612224079 PARSEDPushLDCMAtoGWM_ECG: 8 HCM
 SG_ PARSEDPushLDCMAtoGWM_ECG : 7|29@0+ (1,0) [0|536870911] "unitless"  GWM

BO_ 2612082904 PARSEDPushFcGWM_ECGtoLDCMB: 8 GWM
 SG_ PARSEDPushFcGWM_ECGtoLDCMB : 7|29@0+ (1,0) [0|536870911] "unitless"  HCM

BO_ 2612083928 PARSEDPushFcGWM_ECGtoLDCMA: 8 GWM
 SG_ PARSEDPushFcGWM_ECGtoLDCMA : 7|29@0+ (1,0) [0|536870911] "unitless"  HCM

BO_ 2610126926 OTAPhysLDCMBtoGWM_ECG: 64 HCM
 SG_ OTAPhysLDCMBtoGWM_ECG : 7|29@0+ (1,0) [0|536870911] "unitless"  GWM

BO_ 2610126927 OTAPhysLDCMAtoGWM_ECG: 64 HCM
 SG_ OTAPhysLDCMAtoGWM_ECG : 7|29@0+ (1,0) [0|536870911] "unitless"  GWM

BO_ 2609985752 OTAPhysGWM_ECGtoLDCMB: 64 GWM
 SG_ OTAPhysGWM_ECGtoLDCMB : 7|29@0+ (1,0) [0|536870911] "unitless"  HCM

BO_ 2609986776 OTAPhysGWM_ECGtoLDCMA: 64 GWM
 SG_ OTAPhysGWM_ECGtoLDCMA : 7|29@0+ (1,0) [0|536870911] "unitless"  HCM

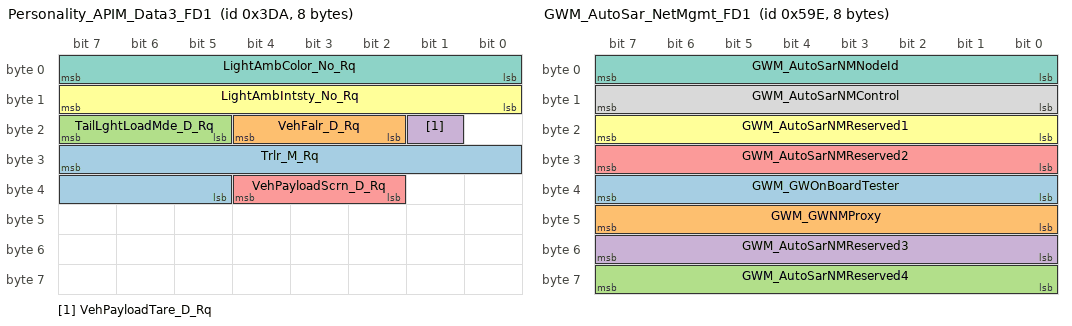
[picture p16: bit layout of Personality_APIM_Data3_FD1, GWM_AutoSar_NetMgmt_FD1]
BO_ 986 Personality_APIM_Data3_FD1: 8 GWM
 SG_ Trlr_M_Rq : 31|11@0+ (10,0) [0|20450] "kilogram" Vector__XXX
 SG_ VehFalr_D_Rq : 20|3@0+ (1,0) [0|7] "SED" Vector__XXX
 SG_ TailLghtLoadMde_D_Rq : 23|3@0+ (1,0) [0|7] "SED"  GENERIC
 SG_ VehPayloadTare_D_Rq : 17|1@0+ (1,0) [0|1] "SED" Vector__XXX
 SG_ VehPayloadScrn_D_Rq : 36|3@0+ (1,0) [0|7] "SED" Vector__XXX
 SG_ LightAmbIntsty_No_Rq : 15|8@0+ (1,0) [0|255] "unitless"  GENERIC
 SG_ LightAmbColor_No_Rq : 7|8@0+ (1,0) [0|255] "Discrete"  GENERIC

BO_ 1822 TesterPhysicalResGWM_FD1: 64 GWM
 SG_ TesterPhysicalResGWM_F1 : 7|64@0+ (1,0) [0|1.84467E+019] "unitless"  TSTR

BO_ 1438 GWM_AutoSar_NetMgmt_FD1: 8 GWM
 SG_ GWM_GWOnBoardTester : 39|8@0+ (1,0) [0|255] "unitless"  SOBDMC_HPCM,CMR_DSMC,ABS_ESC,ECM_HEV,PCM
 SG_ GWM_GWNMProxy : 47|8@0+ (1,0) [0|255] "unitless"  SOBDMC_HPCM,CMR_DSMC,ABS_ESC,ECM_HEV,PCM
 SG_ GWM_AutoSarNMReserved4 : 63|8@0+ (1,0) [0|255] "unitless"  SOBDMC_HPCM,CMR_DSMC,ABS_ESC,ECM_HEV,PCM
 SG_ GWM_AutoSarNMReserved3 : 55|8@0+ (1,0) [0|255] "unitless"  SOBDMC_HPCM,CMR_DSMC,ABS_ESC,ECM_HEV,PCM
 SG_ GWM_AutoSarNMReserved2 : 31|8@0+ (1,0) [0|255] "unitless"  SOBDMC_HPCM,CMR_DSMC,ABS_ESC,ECM_HEV,PCM
 SG_ GWM_AutoSarNMReserved1 : 23|8@0+ (1,0) [0|255] "unitless"  SOBDMC_HPCM,CMR_DSMC,ABS_ESC,ECM_HEV,PCM
 SG_ GWM_AutoSarNMNodeId : 7|8@0+ (1,0) [0|255] "unitless"  SOBDMC_HPCM,CMR_DSMC,ABS_ESC,ECM_HEV,PCM
 SG_ GWM_AutoSarNMControl : 15|8@0+ (1,0) [0|255] "unitless"  SOBDMC_HPCM,CMR_DSMC,ABS_ESC,ECM_HEV,PCM

BO_ 1191 HEV_Data_Monitor_23_FD1: 8 GWM
 SG_ BattTracTe14_Te_Actl : 7|8@0+ (1,-50) [-50|203] "degC"  SOBDMC_HPCM
 SG_ BattTracTe19_Te_Actl : 47|8@0+ (1,-50) [-50|203] "degC"  SOBDMC_HPCM
 SG_ BattTracTe18_Te_Actl : 39|8@0+ (1,-50) [-50|203] "degC"  SOBDMC_HPCM
 SG_ BattTracTe17_Te_Actl : 31|8@0+ (1,-50) [-50|203] "degC"  SOBDMC_HPCM
 SG_ BattTracTe16_Te_Actl : 23|8@0+ (1,-50) [-50|203] "degC"  SOBDMC_HPCM
 SG_ BattTracTe15_Te_Actl : 15|8@0+ (1,-50) [-50|203] "degC"  SOBDMC_HPCM

BO_ 1190 HEV_Data_Monitor_22_FD1: 8 GWM
 SG_ BattTracUMxArry_No_Actl : 52|5@0+ (1,0) [0|30] "unitless"  SOBDMC_HPCM
 SG_ BattTracCellUMx_No_Actl : 63|8@0+ (1,0) [0|253] "Unitless"  SOBDMC_HPCM
 SG_ BattChrgUMx_B_Falt : 53|1@0+ (1,0) [0|1] "SED"  SOBDMC_HPCM
 SG_ BattTracCellUMn_No_Actl : 15|8@0+ (1,0) [0|253] "Unitless"  SOBDMC_HPCM
 SG_ BattTracCellCnt_No_Actl : 7|8@0+ (1,0) [0|253] "Unitless"  SOBDMC_HPCM
 SG_ BattChrgIsltn_B_Falt : 47|1@0+ (1,0) [0|1] "SED"  SOBDMC_HPCM
 SG_ BattTracCellDiff_B_Falt : 43|1@0+ (1,0) [0|1] "SED"  SOBDMC_HPCM
 SG_ BattChrgSocMx_B_Falt : 44|1@0+ (1,0) [0|1] "SED"  SOBDMC_HPCM
 SG_ BattChrgSocMn_B_Falt : 45|1@0+ (1,0) [0|1] "SED"  SOBDMC_HPCM
 SG_ BattChrgSocErrtc_B_Falt : 46|1@0+ (1,0) [0|1] "SED"  SOBDMC_HPCM
 SG_ BattTracUMx_B_Falt : 54|1@0+ (1,0) [0|1] "SED"  SOBDMC_HPCM
 SG_ BattTracUMn_B_Falt : 55|1@0+ (1,0) [0|1] "SED"  SOBDMC_HPCM
 SG_ BattTracTeMx_No_Actl : 39|8@0+ (1,0) [0|253] "Unitless"  SOBDMC_HPCM
 SG_ BattTracTeMx_B_Falt : 40|1@0+ (1,0) [0|1] "SED"  SOBDMC_HPCM
 SG_ BattTracTeMn_No_Actl : 31|8@0+ (1,0) [0|253] "Unitless"  SOBDMC_HPCM
 SG_ BattTracTeDelta_B_Falt : 41|1@0+ (1,0) [0|1] "SED"  SOBDMC_HPCM
 SG_ BattTracTeCnt_No_Actl : 23|8@0+ (1,0) [0|253] "Unitless"  SOBDMC_HPCM
 SG_ BattTracSoftware_B_Falt : 42|1@0+ (1,0) [0|1] "SED"  SOBDMC_HPCM

BO_ 1192 HEV_Data_Monitor_19_FD1: 8 GWM
 SG_ BattTracCell95_U_Actl : 55|12@0+ (0.001,1) [1|5.093] "volt"  SOBDMC_HPCM
 SG_ BattTracCell94_U_Actl : 35|12@0+ (0.001,1) [1|5.093] "volt"  SOBDMC_HPCM
 SG_ BattTracCell93_U_Actl : 31|12@0+ (0.001,1) [1|5.093] "volt"  SOBDMC_HPCM
 SG_ BattTracCell92_U_Actl : 11|12@0+ (0.001,1) [1|5.093] "volt"  SOBDMC_HPCM
 SG_ BattTracCell91_U_Actl : 7|12@0+ (0.001,1) [1|5.093] "volt"  SOBDMC_HPCM

BO_ 1245 DrivelineCstmFeatures: 8 GWM
 SG_ RearDiffLckLamp_D_Cstm : 13|2@0+ (1,0) [0|3] "SED" Vector__XXX
 SG_ FrontDiffLckLamp_D_Cstm : 15|2@0+ (1,0) [0|3] "SED" Vector__XXX
 SG_ AwdMdeCstm_D_RqDrv : 7|3@0+ (1,0) [0|7] "SED" Vector__XXX
 SG_ SelDrvMdeAwd2_D_Cstm : 4|5@0+ (1,0) [0|31] "SED" Vector__XXX

BO_ 1242 PowertrainCstmData: 8 GWM
 SG_ SelDrvMdeCstmPt_D_Rq : 4|5@0+ (1,0) [0|31] "SED" Vector__XXX
 SG_ EngExhMdeQuietCstm_D_Rq : 7|3@0+ (1,0) [0|7] "SED" Vector__XXX
 SG_ StopStrtCstm_D_Rq : 15|2@0+ (1,0) [0|3] "SED" Vector__XXX

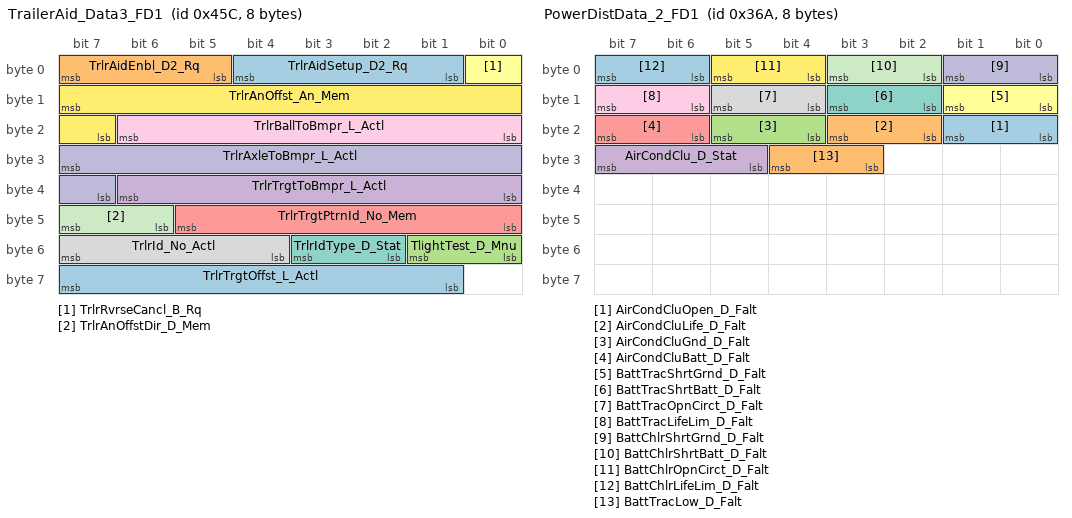
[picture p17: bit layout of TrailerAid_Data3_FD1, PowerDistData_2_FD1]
BO_ 1116 TrailerAid_Data3_FD1: 8 GWM
 SG_ TrlrAidSetup_D2_Rq : 4|4@0+ (1,0) [0|15] "SED"  IPMA_ADAS
 SG_ TrlrAidEnbl_D2_Rq : 7|3@0+ (1,0) [0|7] "SED"  IPMA_ADAS
 SG_ TlightTest_D_Mnu : 49|2@0+ (1,0) [0|3] "SED"  GENERIC
 SG_ TrlrTrgtToBmpr_L_Actl : 38|7@0+ (0.0127,0) [0|1.6129] "meter"  IPMA_ADAS
 SG_ TrlrTrgtPtrnId_No_Mem : 45|6@0+ (1,0) [0|63] "unitless"  IPMA_ADAS
 SG_ TrlrRvrseCancl_B_Rq : 0|1@0+ (1,0) [0|1] "SED"  IPMA_ADAS
 SG_ TrlrIdType_D_Stat : 51|2@0+ (1,0) [0|3] "SED"  IPMA_ADAS
 SG_ TrlrId_No_Actl : 55|4@0+ (1,0) [0|15] "unitless"  IPMA_ADAS
 SG_ TrlrBallToBmpr_L_Actl : 22|7@0+ (0.0127,0) [0|1.6129] "meter"  IPMA_ADAS
 SG_ TrlrAxleToBmpr_L_Actl : 31|9@0+ (0.0254,0) [0|12.9794] "meter"  IPMA_ADAS
 SG_ TrlrAnOffstDir_D_Mem : 47|2@0+ (1,0) [0|3] "SED"  IPMA_ADAS
 SG_ TrlrAnOffst_An_Mem : 15|9@0+ (0.1,0) [0|51.1] "degrees"  IPMA_ADAS
 SG_ TrlrTrgtOffst_L_Actl : 63|7@0+ (0.0127,0) [0|1.6129] "meter"  IPMA_ADAS

BO_ 1844 TesterPhysicalReqHCM: 64 TSTR
 SG_ TesterPhysicalReqHCM : 7|64@0+ (1,0) [0|1.84467E+019] "unitless"  HCM

BO_ 954 Body_Info_10_FD1: 8 GWM
 SG_ ExtLghtFront_D_RqBody : 61|2@0+ (1,0) [0|3] "SED" Vector__XXX
 SG_ VehWlcmFrwlMde_D_Stat : 29|3@0+ (1,0) [0|7] "SED"  HCM
 SG_ CrtsyLghtRear_D_Stat : 63|2@0+ (1,0) [0|3] "SED"  GENERIC
 SG_ ChildLckMaint_D_Stat : 59|2@0+ (1,0) [0|3] "SED"  IPMA_ADAS
 SG_ GenericSwtch3_No_Actl : 15|3@0+ (1,0) [0|7] "unitless"  GENERIC
 SG_ GenericSwtch2_No_Actl : 4|3@0+ (1,0) [0|7] "unitless" Vector__XXX
 SG_ GenericSwtch1_No_Actl : 7|3@0+ (1,0) [0|7] "unitless"  GENERIC
 SG_ PosLghtFl_D_Stat : 51|2@0+ (1,0) [0|3] "SED"  HCM
 SG_ PosLghtFr_D_Stat : 49|2@0+ (1,0) [0|3] "SED"  HCM
 SG_ PudSptLghtRight_D_Rq : 17|2@0+ (1,0) [0|3] "SED"  GENERIC
 SG_ PudSptLghtLeft_D_Rq : 19|2@0+ (1,0) [0|3] "SED"  GENERIC
 SG_ ExtLghtRight_D_Stat : 21|2@0+ (1,0) [0|3] "SED"  GENERIC
 SG_ ExtLghtRear_D_Stat : 23|2@0+ (1,0) [0|3] "SED"  GENERIC
 SG_ ExtLghtLeft_D_Stat : 9|2@0+ (1,0) [0|3] "SED"  GENERIC
 SG_ ExtLghtFront_D_Stat : 11|2@0+ (1,0) [0|3] "SED"  GENERIC
 SG_ CargoLght_D_Stat : 55|2@0+ (1,0) [0|3] "SED" Vector__XXX
 SG_ TlghtTestLght_D_Stat : 44|3@0+ (1,0) [0|7] "SED"  GENERIC
 SG_ LghtAmbDrvMde_B_Stat : 34|1@0+ (1,0) [0|1] "SED"  GENERIC
 SG_ KeylessIdl_B_Stat : 41|1@0+ (1,0) [0|1] "SED"  GENERIC
 SG_ PwRnngBoardPoll_D_Stat : 36|2@0+ (1,0) [0|3] "SED"  GENERIC
 SG_ PoliceDmngLvl_D_Stat : 39|3@0+ (1,0) [0|7] "SED"  GENERIC
 SG_ TrlrHitchLamp_D_Stat : 25|1@0+ (1,0) [0|1] "SED"  GENERIC
 SG_ LicPlateLght_B_Stat : 26|1@0+ (1,0) [0|1] "SED"  GENERIC
 SG_ TrukBedLght_B_Stat : 24|1@0+ (1,0) [0|1] "SED"  GENERIC
 SG_ VehWlcmFrwl_D_Stat : 31|2@0+ (1,0) [0|3] "SED"  HCM
 SG_ TlghtTestPrecnd_D_Stat : 47|3@0+ (1,0) [0|7] "SED"  GENERIC
 SG_ TlghtTest_D_Stat : 33|2@0+ (1,0) [0|3] "SED"  GENERIC
 SG_ ExtLghtAlrt_B_Rq : 12|1@0+ (1,0) [0|1] "SED"  GENERIC
 SG_ ExtLght_D_Falt : 1|2@0+ (1,0) [0|3] "SED"  GENERIC

BO_ 1852 TesterPhysicalResHCM: 64 HCM
 SG_ TesterPhysicalResHCM : 7|64@0+ (1,0) [0|1.84467E+019] "unitless"  TSTR

BO_ 989 Personality_HCM_Data: 8 HCM
 SG_ FeatNoHcm_No_Actl : 23|16@0+ (1,0) [0|65535] "Number"  GWM
 SG_ FeatConfigHcmActl : 7|16@0+ (1,0) [0|65535] "Undefined"  GWM

BO_ 874 PowerDistData_2_FD1: 8 GWM
 SG_ AirCondCluOpen_D_Falt : 17|2@0+ (1,0) [0|3] "SED"  PCM
 SG_ AirCondCluLife_D_Falt : 19|2@0+ (1,0) [0|3] "SED"  PCM
 SG_ AirCondCluGnd_D_Falt : 21|2@0+ (1,0) [0|3] "SED"  PCM
 SG_ AirCondClu_D_Stat : 31|3@0+ (1,0) [0|7] "SED"  PCM
 SG_ AirCondCluBatt_D_Falt : 23|2@0+ (1,0) [0|3] "SED"  PCM
 SG_ BattTracShrtGrnd_D_Falt : 9|2@0+ (1,0) [0|3] "SED"  SOBDMC_HPCM,GENERIC
 SG_ BattTracShrtBatt_D_Falt : 11|2@0+ (1,0) [0|3] "SED"  SOBDMC_HPCM,GENERIC
 SG_ BattTracOpnCirct_D_Falt : 13|2@0+ (1,0) [0|3] "SED"  SOBDMC_HPCM,GENERIC
 SG_ BattTracLifeLim_D_Falt : 15|2@0+ (1,0) [0|3] "SED"  SOBDMC_HPCM,GENERIC
 SG_ BattChlrShrtGrnd_D_Falt : 1|2@0+ (1,0) [0|3] "SED"  SOBDMC_HPCM,GENERIC
 SG_ BattChlrShrtBatt_D_Falt : 3|2@0+ (1,0) [0|3] "SED"  SOBDMC_HPCM,GENERIC
 SG_ BattChlrOpnCirct_D_Falt : 5|2@0+ (1,0) [0|3] "SED"  SOBDMC_HPCM,GENERIC
 SG_ BattChlrLifeLim_D_Falt : 7|2@0+ (1,0) [0|3] "SED"  SOBDMC_HPCM,GENERIC
 SG_ BattTracLow_D_Falt : 28|2@0+ (1,0) [0|3] "SED"  SOBDMC_HPCM

BO_ 551 APIM_Request_Signals_1_FD1: 8 GWM
 SG_ VehPerfDemo_B_RqDrv : 8|1@0+ (1,0) [0|1] "SED"  SOBDMC_HPCM
 SG_ PrkBrkPerfMnuOn_D_Stat : 1|2@0+ (1,0) [0|3] "SED" Vector__XXX
 SG_ PrkBrkPerfButtn_D_Stat : 3|2@0+ (1,0) [0|3] "SED" Vector__XXX
 SG_ TjaLaneBiasEnbl_D_RqMnu : 5|2@0+ (1,0) [0|3] "SED"  IPMA_ADAS
 SG_ Rba_D_Rq : 31|2@0+ (1,0) [0|3] "SED"  IPMA_ADAS
 SG_ EmPrflNo_D_Rq : 61|3@0+ (1,0) [0|7] "SED"  GENERIC
 SG_ EmPrflButtnAssoc_D_Rq : 33|2@0+ (1,0) [0|3] "SED"  GENERIC
 SG_ EmPrflKeyAssoc_D_Rq : 46|3@0+ (1,0) [0|7] "SED"  GENERIC
 SG_ Em_D_Stat : 63|2@0+ (1,0) [0|3] "SED"  GENERIC
 SG_ ChrgOvrdExitScrn_D_Rq : 58|2@0+ (1,0) [0|3] "SED"  GENERIC
 SG_ PrcondEdit_D_RqMnu : 15|3@0+ (1,0) [0|7] "SED"  SOBDMC_HPCM
 SG_ ChrgToPcEdit_Pc_RqMnu : 23|7@0+ (1,0) [0|125] "percent"  SOBDMC_HPCM
 SG_ EcoIdl_D_Rq : 7|2@0+ (1,0) [0|3] "SED"  SOBDMC_HPCM
 SG_ PmCabnLvl_D_Stat : 36|3@0+ (1,0) [0|7] "SED"  GENERIC
 SG_ PmCabn_D_Stat : 38|2@0+ (1,0) [0|3] "SED"  GENERIC
 SG_ PwRnngBoardSwtch_D_Rq : 27|2@0+ (1,0) [0|3] "SED"  GENERIC
 SG_ PwRnngBoardMde_D_Rq : 29|2@0+ (1,0) [0|3] "SED"  GENERIC
 SG_ PwRnngBoardT_D_Rq : 25|2@0+ (1,0) [0|3] "SED"  GENERIC
 SG_ OneTEditActv_B_RqMnu : 40|1@0+ (1,0) [0|1] "SED"  SOBDMC_HPCM
 SG_ GoTElementEdit_No_RqMnu : 12|4@0+ (1,0) [0|15] "unitless"  SOBDMC_HPCM
 SG_ Cntr_Plg_Mode_Cmd : 39|1@0+ (1,0) [0|1] "SED"  GENERIC
 SG_ BattTracLoThres_D_Rq : 43|3@0+ (1,0) [0|7] "SED"  SOBDMC_HPCM
 SG_ ChrgCrdLckEnbl_B_Stat : 47|1@0+ (1,0) [0|1] "SED"  GENERIC
 SG_ Btt_L_Actl2 : 55|7@0+ (0.1,0) [0|12.5] "meter"  IPMA_ADAS

BO_ 132 GlobalClock_Data_FD1: 8 GWM
 SG_ GlblClkYr_No_Actl : 7|8@0+ (1,2000) [2000|2255] "year"  SOBDMC_HPCM,IPMA_ADAS,CMR_DSMC
 SG_ GlblClkScnd_No_Actl : 47|8@0+ (1,0) [0|255] "second"  SOBDMC_HPCM,IPMA_ADAS,CMR_DSMC
 SG_ GlblClkMnte_No_Actl : 39|8@0+ (1,0) [0|255] "minute"  SOBDMC_HPCM,IPMA_ADAS,CMR_DSMC
 SG_ GlblClkHr_No_Actl : 55|8@0+ (1,0) [0|255] "hour"  SOBDMC_HPCM,IPMA_ADAS,CMR_DSMC
 SG_ GlblClkDay_No_Actl : 23|16@0+ (1,0) [0|65535] "julian day"  SOBDMC_HPCM,IPMA_ADAS,CMR_DSMC

BO_ 1006 Personality_IPMB_Data: 8 IPMA_ADAS
 SG_ PersIndexIpmb_D_Actl : 39|3@0+ (1,0) [0|7] "SED"  GWM
 SG_ FeatNoIpmbActl : 23|16@0+ (1,0) [0|65535] "Number"  GWM
 SG_ FeatConfigIpmbActl : 7|16@0+ (1,0) [0|65535] "Undefined"  GWM

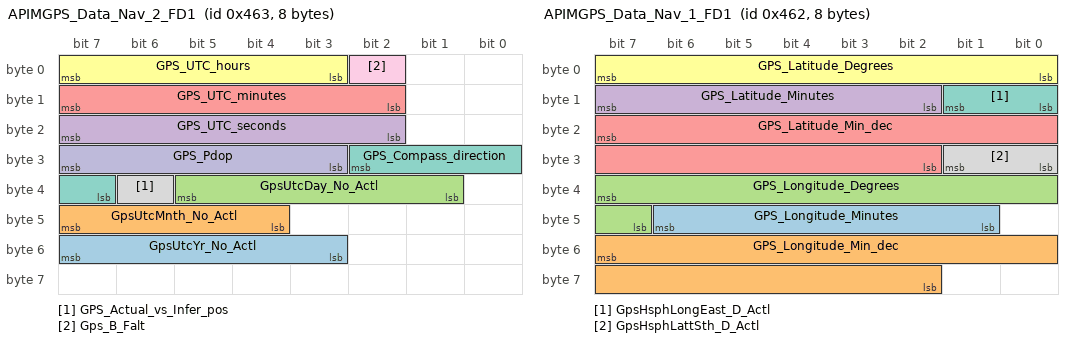
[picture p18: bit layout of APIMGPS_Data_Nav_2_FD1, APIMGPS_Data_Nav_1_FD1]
BO_ 1123 APIMGPS_Data_Nav_2_FD1: 8 GWM
 SG_ GpsUtcYr_No_Actl : 55|5@0+ (1,2010) [2010|2040] "Year"  GENERIC
 SG_ GpsUtcMnth_No_Actl : 47|4@0+ (1,1) [1|15] "Month"  GENERIC
 SG_ GpsUtcDay_No_Actl : 37|5@0+ (1,1) [1|32] "Day"  GENERIC
 SG_ GPS_UTC_seconds : 23|6@0+ (1,0) [0|59] "seconds"  GENERIC
 SG_ GPS_UTC_minutes : 15|6@0+ (1,0) [0|59] "Minutes"  GENERIC
 SG_ GPS_UTC_hours : 7|5@0+ (1,0) [0|23] "Hours"  GENERIC
 SG_ GPS_Compass_direction : 26|4@0+ (1,0) [0|15] "SED"  GENERIC
 SG_ GPS_Actual_vs_Infer_pos : 38|1@0+ (1,0) [0|1] "SED"  GENERIC
 SG_ Gps_B_Falt : 2|1@0+ (1,0) [0|1] "SED"  GENERIC
 SG_ GPS_Pdop : 31|5@0+ (0.2,0) [0|5.8] "unitless"  GENERIC

BO_ 1122 APIMGPS_Data_Nav_1_FD1: 8 GWM
 SG_ GPS_Longitude_Minutes : 46|6@0+ (1,0) [0|61] "Minutes"  GENERIC
 SG_ GPS_Longitude_Min_dec : 55|14@0+ (0.0001,0) [0|1.6381] "Minutes"  GENERIC
 SG_ GPS_Longitude_Degrees : 39|9@0+ (1,-179) [-179|330] "Degrees"  GENERIC
 SG_ GPS_Latitude_Minutes : 15|6@0+ (1,0) [0|61] "Minutes"  GENERIC
 SG_ GPS_Latitude_Min_dec : 23|14@0+ (0.0001,0) [0|1.6381] "Minutes"  GENERIC
 SG_ GPS_Latitude_Degrees : 7|8@0+ (1,-89) [-89|164] "Degrees"  GENERIC
 SG_ GpsHsphLongEast_D_Actl : 9|2@0+ (1,0) [0|3] "SED"  GENERIC
 SG_ GpsHsphLattSth_D_Actl : 25|2@0+ (1,0) [0|3] "SED"  GENERIC

BO_ 1003 Personality_BCM2_Data_FD1: 8 GWM
 SG_ TailLghtLoadMde_D_Stat : 60|3@0+ (1,0) [0|7] "SED"  GENERIC
 SG_ PersRecallSrc_D_Actl : 63|3@0+ (1,0) [0|7] "SED"  GENERIC
 SG_ Pers4Key_D_Stat : 49|2@0+ (1,0) [0|3] "SED"  GENERIC
 SG_ Pers3Key_D_Stat : 41|2@0+ (1,0) [0|3] "SED"  GENERIC
 SG_ Pers2Key_D_Stat : 43|2@0+ (1,0) [0|3] "SED"  GENERIC
 SG_ Pers1Key_D_Stat : 12|2@0+ (1,0) [0|3] "SED"  GENERIC
 SG_ EmPrflNo_D_Stat : 52|3@0+ (1,0) [0|7] "SED"  GENERIC
 SG_ EmPrflKeyAssoc_D_Stat : 55|3@0+ (1,0) [0|7] "SED"  GENERIC
 SG_ VehKeyActv_D_Stat : 47|4@0+ (1,0) [0|15] "SED"  SOBDMC_HPCM,GENERIC
 SG_ PersNoPos_D_Actl : 18|3@0+ (1,0) [0|7] "SED"  GENERIC
 SG_ PersSetupRestr_D_Actl : 21|2@0+ (1,0) [0|3] "SED"  SOBDMC_HPCM,GENERIC
 SG_ PersSetupAccessCtrl : 19|1@0+ (1,0) [0|1] "SED"  SOBDMC_HPCM,GENERIC
 SG_ PersSetup_No_Actl : 31|16@0+ (1,0) [0|65535] "Number"  SOBDMC_HPCM,GENERIC
 SG_ PersConflict_D_Actl : 22|1@0+ (1,0) [0|1] "SED"  GENERIC
 SG_ AssocConfirm_D_Actl : 15|3@0+ (1,0) [0|7] "SED"  GENERIC
 SG_ RecallEvent_No_Cnt : 7|8@0+ (1,0) [0|255] "Counts"  IPMA_ADAS
 SG_ PersNo_D_Actl : 10|3@0+ (1,0) [0|7] "SED"  SOBDMC_HPCM,IPMA_ADAS,ABS_ESC

BO_ 580 Battery_Traction_11_FD1: 8 GWM
 SG_ BattTracVrtOck_B_Rq : 7|1@0+ (1,0) [0|1] "SED" Vector__XXX

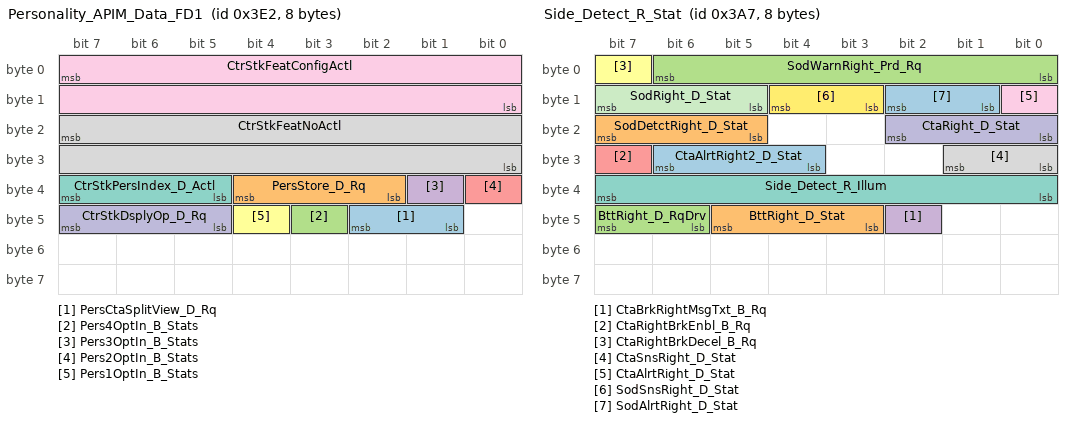
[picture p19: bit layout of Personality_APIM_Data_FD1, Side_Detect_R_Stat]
BO_ 994 Personality_APIM_Data_FD1: 8 GWM
 SG_ PersCtaSplitView_D_Rq : 42|2@0+ (1,0) [0|3] "SED"  IPMA_ADAS
 SG_ PersStore_D_Rq : 36|3@0+ (1,0) [0|7] "SED"  GENERIC
 SG_ Pers4OptIn_B_Stats : 43|1@0+ (1,0) [0|1] "SED"  GENERIC
 SG_ Pers3OptIn_B_Stats : 33|1@0+ (1,0) [0|1] "SED"  GENERIC
 SG_ Pers2OptIn_B_Stats : 32|1@0+ (1,0) [0|1] "SED"  GENERIC
 SG_ Pers1OptIn_B_Stats : 44|1@0+ (1,0) [0|1] "SED"  GENERIC
 SG_ CtrStkPersIndex_D_Actl : 39|3@0+ (1,0) [0|7] "SED"  ABS_ESC,SOBDMC_HPCM,HCM,IPMA_ADAS
 SG_ CtrStkFeatNoActl : 23|16@0+ (1,0) [0|65535] "Undefined"  ECM_HEV,PCM,ABS_ESC,SOBDMC_HPCM,HCM,IPMA_ADAS
 SG_ CtrStkFeatConfigActl : 7|16@0+ (1,0) [0|65535] "Undefined"  ECM_HEV,PCM,ABS_ESC,SOBDMC_HPCM,HCM,IPMA_ADAS
 SG_ CtrStkDsplyOp_D_Rq : 47|3@0+ (1,0) [0|7] "SED"  ECM_HEV,PCM,ABS_ESC,SOBDMC_HPCM,HCM,IPMA_ADAS

BO_ 992 Personality_Data_FD1: 8 GWM
 SG_ MsgCntrPersIndex_D_Rq : 39|3@0+ (1,0) [0|7] "SED"  SOBDMC_HPCM,IPMA_ADAS,HCM
 SG_ MsgCntrFeatConfigRq : 23|16@0+ (1,0) [0|65535] "unitless"  SOBDMC_HPCM,HCM,IPMA_ADAS
 SG_ MsgCntrFeatNoRq : 7|16@0+ (1,0) [0|65535] "Number"  SOBDMC_HPCM,IPMA_ADAS,HCM
 SG_ MsgCntrDsplyOp_D_Rq : 36|3@0+ (1,0) [0|7] "SED"  SOBDMC_HPCM,HCM,IPMA_ADAS

BO_ 820 Adaptive_Headlamp_Stat: 8 HCM
 SG_ AhbStatGfhbFdbk_D_Actl : 53|2@0+ (1,0) [0|3] "SED"  IPMA_ADAS
 SG_ HeadLghtDrvSide_B_Stat : 33|1@0+ (1,0) [0|1] "SED"  IPMA_ADAS
 SG_ Adaptive_Hdlmp_Fault : 7|1@0+ (1,0) [0|1] "SED"  GWM
 SG_ TurnLampFrOut_B_Stat : 5|1@0+ (1,0) [0|1] "SED"  GWM
 SG_ TurnLampFlOut_B_Stat : 6|1@0+ (1,0) [0|1] "SED"  GWM

BO_ 817 Locking_Systems_2_FD1: 8 GWM
 SG_ ChildLckMde_B_Stat : 56|1@0+ (1,0) [0|1] "SED"  GENERIC
 SG_ VehLckInd_D_Rq : 58|2@0+ (1,0) [0|3] "SED"  GENERIC
 SG_ DrTgateOpen_B_Rq : 59|1@0+ (1,0) [0|1] "SED"  GENERIC
 SG_ DrTgateExtSwMde_B_Stat : 32|1@0+ (1,0) [0|1] "SED"  GENERIC
 SG_ Remote_Device_Feedback : 50|3@0+ (1,0) [0|7] "SED"  GENERIC
 SG_ Veh_Lock_Requestor : 55|5@0+ (1,0) [0|31] "SED"  GENERIC
 SG_ R_Pwr_Sliding_Dr_Rqst : 36|1@0+ (1,0) [0|1] "SED"  GENERIC
 SG_ Power_Liftgate_Rqst : 0|1@0+ (1,0) [0|1] "SED"  GENERIC
 SG_ Veh_Lock_EvNum : 47|8@0+ (1,0) [0|255] "unitless"  GENERIC
 SG_ Power_Decklid_Rqst : 1|1@0+ (1,0) [0|1] "SED"  GENERIC
 SG_ L_Pwr_Sliding_Dr_Rqst : 3|1@0+ (1,0) [0|1] "SED"  GENERIC
 SG_ Keyfob_Pad_Msg_Count : 15|8@0+ (1,0) [0|255] "Counts"  GENERIC
 SG_ Veh_Lock_Sub_Id : 63|4@0+ (1,0) [0|15] "SED"  GENERIC
 SG_ Veh_Lock_Status : 34|2@0+ (1,0) [0|3] "SED"  GENERIC,IPMA_ADAS,CMR_DSMC
 SG_ ChildLck_D_Dsply : 7|2@0+ (1,0) [0|3] "SED"  GENERIC
 SG_ WindowLockout_B_Stat : 35|1@0+ (1,0) [0|1] "SED"  GENERIC
 SG_ RollCodeUnlock : 23|16@0+ (1,0) [0|65535] "Unitless"  GENERIC
 SG_ Lockmsgtxt_D_Rq : 39|3@0+ (1,0) [0|7] "SED"  GENERIC
 SG_ FobComm_D_Stat : 5|2@0+ (1,0) [0|3] "SED"  GENERIC
 SG_ LockInhibit : 2|1@0+ (1,0) [0|1] "SED"  GENERIC

BO_ 129 Steering_Wheel_Data2_FD1: 8 GWM
 SG_ SelDrvMdeSwtch4_D_Stat4 : 38|2@0+ (1,0) [0|3] "SED" Vector__XXX
 SG_ EngExhMdeQuiet_B_RqDrv2 : 39|1@0+ (1,0) [0|1] "SED"  GENERIC
 SG_ SelDrvMdeSwtch_D_Stat4 : 21|2@0+ (1,0) [0|3] "SED" Vector__XXX
 SG_ SteWhlSwtchView_B_Stat : 23|1@0+ (1,0) [0|1] "SED"  GENERIC
 SG_ SteWhlSwtchSet_B_Stat : 8|1@0+ (1,0) [0|1] "SED"  GENERIC
 SG_ SteWhlSwtchPhon_B_Stat : 9|1@0+ (1,0) [0|1] "SED"  GENERIC
 SG_ SteWhlSwtchNav_B_Stat : 10|1@0+ (1,0) [0|1] "SED"  GENERIC
 SG_ SteWhlSwtchMed_B_Stat : 11|1@0+ (1,0) [0|1] "SED"  GENERIC
 SG_ SteWhlSwtchIod_B_Stat : 12|1@0+ (1,0) [0|1] "SED"  GENERIC
 SG_ SteWhlSwtchHud_B_Stat : 13|1@0+ (1,0) [0|1] "SED"  GENERIC
 SG_ SteWhlSwtchBack_B_Stat : 14|1@0+ (1,0) [0|1] "SED"  GENERIC
 SG_ SteWhlSwtchMenu_B_Stat : 22|1@0+ (1,0) [0|1] "SED"  GENERIC
 SG_ SteEffortInc_B_RqDrv : 5|1@0+ (1,0) [0|1] "SED"  GENERIC
 SG_ SelDrvMdeInc_B_RqDrv : 6|1@0+ (1,0) [0|1] "SED"  GENERIC
 SG_ SelDrvMdeDec_B_RqDrv : 7|1@0+ (1,0) [0|1] "SED"  GENERIC
 SG_ SuspDampInc_B_RqDrv : 15|1@0+ (1,0) [0|1] "SED"  GENERIC
 SG_ SteWhlSwtchUp_B_Stat : 3|1@0+ (1,0) [0|1] "SED"  GENERIC
 SG_ SteWhlSwtchRght_B_Stat : 2|1@0+ (1,0) [0|1] "SED"  GENERIC
 SG_ SteWhlSwtchOk_B_Stat : 4|1@0+ (1,0) [0|1] "SED"  GENERIC
 SG_ SteWhlSwtchLeft_B_Stat : 1|1@0+ (1,0) [0|1] "SED"  GENERIC
 SG_ SteWhlSwtchDown_B_Stat : 0|1@0+ (1,0) [0|1] "SED"  GENERIC
 SG_ SteWhlSwtchHome_B_Stat : 19|1@0+ (1,0) [0|1] "SED"  GENERIC
 SG_ SteWhlSwtchInfo_B_Stat : 18|1@0+ (1,0) [0|1] "SED"  GENERIC
 SG_ PoliceAux4Swtch_B_Stat : 30|1@0+ (1,0) [0|1] "SED"  GENERIC
 SG_ PoliceAux3Swtch_B_Stat : 31|1@0+ (1,0) [0|1] "SED"  GENERIC
 SG_ PoliceAux2Swtch_B_Stat : 16|1@0+ (1,0) [0|1] "SED"  GENERIC
 SG_ PoliceAux1Swtch_B_Stat : 17|1@0+ (1,0) [0|1] "SED"  GENERIC
 SG_ SelDrvMdeSwtch3_D_Stat4 : 25|2@0+ (1,0) [0|3] "SED" Vector__XXX
 SG_ SelDrvMdeSwtch2_D_Stat4 : 27|2@0+ (1,0) [0|3] "SED" Vector__XXX
 SG_ SelDrvMdeSwtch1_D_Stat4 : 29|2@0+ (1,0) [0|3] "SED" Vector__XXX

BO_ 854 Clmt_Button_Stat2_FD1: 8 GWM
 SG_ Dsp_RotAddrBtnEv_St : 63|4@0+ (1,0) [0|15] "SED"  GENERIC
 SG_ SelDrvMdeButtn_B_Stat : 55|1@0+ (1,0) [0|1] "SED"  GENERIC
 SG_ SteEffortButtn_B_Stat : 54|1@0+ (1,0) [0|1] "SED"  GENERIC
 SG_ SelDrvMdeSwtch_D_Stat2 : 51|2@0+ (1,0) [0|3] "SED"  GENERIC,ABS_ESC
 SG_ CC_Fr_Stat_User_Adj : 6|3@0+ (1,0) [0|7] "SED"  GENERIC
 SG_ EngExhMdeQuiet_B_RqDrv : 52|1@0+ (1,0) [0|1] "SED"  GENERIC
 SG_ LnchCtlSys_B_RqDrv : 53|1@0+ (1,0) [0|1] "SED"  GENERIC
 SG_ Front_Blower_Indicate : 13|4@0+ (1,0) [0|15] "SED"  GENERIC
 SG_ CC_Diagnostics_Active : 7|1@0+ (1,0) [0|1] "SED"  GENERIC
 SG_ RHS_Temp_Display_Digit3 : 3|2@0+ (1,0) [0|3] "SED"  GENERIC
 SG_ RHS_Temp_Display_Digit2 : 47|8@0+ (1,0) [0|255] "ASCII"  GENERIC
 SG_ RHS_Temp_Display_Digit1 : 39|8@0+ (1,0) [0|255] "ASCII"  GENERIC
 SG_ LHS_Temp_Display_Digit3 : 9|2@0+ (1,0) [0|3] "SED"  GENERIC
 SG_ LHS_Temp_Display_Digit2 : 31|8@0+ (1,0) [0|255] "ASCII"  GENERIC
 SG_ LHS_Temp_Display_Digit1 : 23|8@0+ (1,0) [0|255] "ASCII"  GENERIC
 SG_ EATC_RHS_Units : 15|2@0+ (1,0) [0|3] "SED"  GENERIC
 SG_ EATC_LHS_Units : 1|2@0+ (1,0) [0|3] "SED"  GENERIC
 SG_ LHS_Auto_Seat_Btn_Stt : 59|2@0+ (1,0) [0|3] "SED"  GENERIC
 SG_ RHS_Auto_Seat_Btn_Stt : 57|2@0+ (1,0) [0|3] "SED"  GENERIC

BO_ 549 IPC_Infotainment_FD1: 8 GWM
 SG_ TjaLcEnbl_D_DrvRq : 41|2@0+ (1,0) [0|3] "SED"  IPMA_ADAS
 SG_ CCOI_PolicyClient_St2 : 45|4@0+ (1,0) [0|15] "SED"  GENERIC
 SG_ FactoryReset_Rq2 : 18|1@0+ (1,0) [0|1] "SED"  GENERIC
 SG_ BattTracLoThres_D_Rq2 : 52|3@0+ (1,0) [0|7] "SED"  SOBDMC_HPCM
 SG_ NavIod_D_Rq : 55|3@0+ (1,0) [0|7] "SED"  GENERIC
 SG_ Veh_V2_Dsply : 39|9@0+ (1,0) [0|511] "unitless"  GENERIC,IPMA_ADAS
 SG_ IPC_MyKeyVolLimit_St : 9|2@0+ (1,0) [0|3] "SED"  GENERIC
 SG_ HdcOn_B_Rq : 19|1@0+ (1,0) [0|1] "SED"  GENERIC
 SG_ IPC_Attn_Info_Audio : 4|3@0+ (1,0) [0|7] "SED"  GENERIC
 SG_ BeltminderAudioMute : 6|2@0+ (1,0) [0|3] "SED"  GENERIC
 SG_ Power_Up_Chime_Modules : 23|1@0+ (1,0) [0|1] "SED"  GENERIC
 SG_ Chime_Source : 15|2@0+ (1,0) [0|3] "SED"  GENERIC
 SG_ IPC_New_Attn_Event : 0|1@0+ (1,0) [0|1] "SED"  GENERIC
 SG_ WwaActv_B_Stat : 46|1@0+ (1,0) [0|1] "SED"  IPMA_ADAS
 SG_ MetricActv_B_Dsply : 7|1@0+ (1,0) [0|1] "SED"  GENERIC
 SG_ HudVertSzMnuOn_B_Rq : 21|1@0+ (1,0) [0|1] "SED"  GENERIC
 SG_ HudVertMnuOn_B_Rq : 11|1@0+ (1,0) [0|1] "SED"  GENERIC
 SG_ HudRotatMnuOn_B_Rq : 22|1@0+ (1,0) [0|1] "SED" Vector__XXX
 SG_ HudCntntMnuOn_B_Rq : 20|1@0+ (1,0) [0|1] "SED"  GENERIC
 SG_ HudBrightMnuOn_B_Rq : 1|1@0+ (1,0) [0|1] "SED"  GENERIC
 SG_ StrtInGearOk_D_Stat : 17|2@0+ (1,0) [0|3] "SED" Vector__XXX

BO_ 935 Side_Detect_R_Stat: 8 IPMA_ADAS
 SG_ CtaAlrtRight2_D_Stat : 30|3@0+ (1,0) [0|7] "SED"  GWM,GENERIC
 SG_ BttRight_D_Stat : 45|3@0+ (1,0) [0|7] "SED"  GWM,GENERIC
 SG_ BttRight_D_RqDrv : 47|2@0+ (1,0) [0|3] "SED"  GWM,GENERIC
 SG_ CtaBrkRightMsgTxt_B_Rq : 42|1@0+ (1,0) [0|1] "SED"  GWM,GENERIC
 SG_ CtaRightBrkEnbl_B_Rq : 31|1@0+ (1,0) [0|1] "SED"  GWM,GENERIC,ABS_ESC
 SG_ CtaRightBrkDecel_B_Rq : 7|1@0+ (1,0) [0|1] "SED"  GWM,GENERIC,ABS_ESC
 SG_ Side_Detect_R_Illum : 39|8@0+ (1,0) [0|255] "Percent"  GWM,GENERIC
 SG_ CtaSnsRight_D_Stat : 25|2@0+ (1,0) [0|3] "SED"  GWM,GENERIC
 SG_ CtaAlrtRight_D_Stat : 8|1@0+ (1,0) [0|1] "SED"  GWM,GENERIC
 SG_ CtaRight_D_Stat : 18|3@0+ (1,0) [0|7] "SED"  GWM,GENERIC
 SG_ SodRight_D_Stat : 15|3@0+ (1,0) [0|7] "SED"  GENERIC,GWM
 SG_ SodSnsRight_D_Stat : 12|2@0+ (1,0) [0|3] "SED"  GENERIC,GWM
 SG_ SodAlrtRight_D_Stat : 10|2@0+ (1,0) [0|3] "SED"  GENERIC,GWM
 SG_ SodDetctRight_D_Stat : 23|3@0+ (1,0) [0|7] "SED"  GENERIC,GWM
 SG_ SodWarnRight_Prd_Rq : 6|7@0+ (1,0) [0|127] "millisecond"  GENERIC,GWM

CM_ "FNV2 FD1 CAN";
CM_ BU_ HCM "Headlamp Ctrl. Mod.A (HS_CAN), Adaptive Headlamps";
CM_ BU_ IPMA_ADAS "Assist Driving Alert System";
CM_ BU_ PSCM "Power Steering Control Module";
CM_ BU_ ABS_ESC "Anti-lock Brake / Traction Control Module";
CM_ BU_ PCM "Powertrain Control Module";
CM_ BU_ ECM_HEV "HEV ECM";
CM_ BU_ VDM "Vehicle Dynamics Control Module";
CM_ BU_ CMR_DSMC "Driver Status Monitor Camera";
CM_ BU_ GWM "Gateway Module CGEA1.3(Star Architecture)";
CM_ BU_ AWD_DLCM "Differential Lock Control module";
CM_ BU_ GENERIC "holding pattern ECU for developmental messages";
CM_ BU_ TSTR "Diagnostic Tester";
CM_ SG_ 368 PrplBrkTqCtl_No_Cs "Signal not transmitted on gas variants.";
CM_ BO_ 66 "Provide control function information to the target function of the Passive Anti-Theft Subsystem";
CM_ SG_ 66 immoControlData_T2 "Not transmitted on all vehicle variants";
CM_ SG_ 66 immoControlCmd_T2 "Not transmitted on all vehicle variants";
CM_ BO_ 932 "NOTE: START BITS 8-11 MUST BE OPEN SPEC REQUIREMENT";
CM_ BO_ 986 "APIM Tx";
CM_ SG_ 954 GenericSwtch2_No_Actl "U625 Police Wig Wag feature";
CM_ BO_ 1123 "HS3 APIM Sync Gen3 Tx 0x463.  FrameGateway to 0x466 on HS1, HS2, HS3 and MS1.";
CM_ BO_ 1122 "HS3 APIM Sync Gen3 Tx 0x462.  FrameGateway to 0x465 on HS1, HS2, HS3 and MS1.";
CM_ SG_ 129 SelDrvMdeSwtch3_D_Stat4 "ECM_HEV does not support or Transmit signal.";
CM_ SG_ 854 RHS_Temp_Display_Digit3 "Added for MY 08";
CM_ SG_ 854 RHS_Temp_Display_Digit2 "Added for MY 08";
CM_ SG_ 854 RHS_Temp_Display_Digit1 "Added for MY 08";
CM_ SG_ 854 LHS_Temp_Display_Digit3 "Added for MY 08";
CM_ SG_ 854 LHS_Temp_Display_Digit2 "Added for MY 08";
CM_ SG_ 854 LHS_Temp_Display_Digit1 "Added for MY 08";
CM_ SG_ 854 EATC_RHS_Units "Added for MY 08";
CM_ SG_ 854 EATC_LHS_Units "Added for MY 08";
CM_ BO_ 549 "Method IPC _Infotainment";
CM_ SG_ 549 BeltminderAudioMute "Object.MyKey.BeltMinderAudioMute.St";
CM_ SG_ 549 Power_Up_Chime_Modules "Object.AlertMethod.IPC _Infotainment";
CM_ SG_ 549 Chime_Source "Object.AlertMethod.IPC_infotainment";
BA_DEF_ SG_  "U_CDX706_MY2023_Tx" ENUM  "No","Yes";
BA_DEF_ SG_  "U_CDX706_MY2023_Rx" ENUM  "No","Yes";
BA_DEF_ BO_  "AuthFreshnessCounterSyncAttempt" INT 0 2;
BA_DEF_ BO_  "VFrameFormat" ENUM  "StandardCAN","ExtendedCAN","reserved","reserved","reserved","reserved","reserved","reserved","reserved","reserved","reserved","reserved","reserved","reserved","StandardCAN_FD","ExtendedCAN_FD";
BA_DEF_ SG_  "GenSigSendType" ENUM  "Cyclic","OnWrite","vector_leerstring","OnChange","vector_leerstring","IfActive","vector_leerstring","NoSigSendType";
BA_DEF_ SG_  "GenSigInactiveValue" INT 0 100000;
BA_DEF_ SG_  "WakeupSignal" ENUM  "No","Yes";
BA_DEF_ SG_  "UsedOnPgmDBC" ENUM  "No","Yes";
BA_DEF_ SG_  "GenSigStartValueInteger" INT 0 1000000000;
BA_DEF_ SG_  "ContentDependant" ENUM  "No","Yes";
BA_DEF_ SG_  "MetaData" ENUM  "No","Yes";
BA_DEF_ SG_  "GenSigStartValue" HEX 0 268435455;
BA_DEF_ SG_  "U_CX727_MY2021_Rx" ENUM  "No","Yes";
BA_DEF_ SG_  "U_P702_MY2021_Rx" ENUM  "No","Yes";
BA_DEF_ SG_  "U_T6_MCA_MY2020_Rx" ENUM  "No","Yes";
BA_DEF_ SG_  "ECGUsedRxSignal" ENUM  "No","Yes";
BA_DEF_ SG_  "U_CD542_MY2021_Rx" ENUM  "No","Yes";
BA_DEF_ SG_  "U_U55X_MY2022_Rx" ENUM  "No","Yes";
BA_DEF_ SG_  "U_CD764_MY2022_Rx" ENUM  "No","Yes";
BA_DEF_ SG_  "U_CX727_MY2021_Tx" ENUM  "No","Yes";
BA_DEF_ SG_  "U_P702_MY2021_Tx" ENUM  "No","Yes";
BA_DEF_ SG_  "U_T6_MCA_MY2020_Tx" ENUM  "No","Yes";
BA_DEF_ SG_  "ECGUsedTxSignal" ENUM  "No","Yes";
BA_DEF_ SG_  "U_CD542_MY2021_Tx" ENUM  "No","Yes";
BA_DEF_ SG_  "U_U55X_MY2022_Tx" ENUM  "No","Yes";
BA_DEF_ SG_  "U_CD764_MY2022_Tx" ENUM  "No","Yes";
BA_DEF_ BO_  "GenMsgILSupport" ENUM  "No","Yes";
BA_DEF_ BO_  "DiagResponse" ENUM  "No","Yes";
BA_DEF_ BO_  "DiagRequest" ENUM  "No","Yes";
BA_DEF_ BO_  "TpTxIndex" INT 0 536870911;
BA_DEF_ BO_  "DiagState" ENUM  "No","Yes";
BA_DEF_ BO_  "TpApplType" STRING ;
BA_DEF_ BO_  "NmAsrMessage" ENUM  "No","Yes";
BA_DEF_ BO_  "SCP_AuthInfoTxLength" INT 0 512;
BA_DEF_ BO_  "SCP_FreshnessValueTxLength" INT 0 512;
BA_DEF_ BO_  "SCP_FreshnessValueLength" INT 0 512;
BA_DEF_ BO_  "OvtpPushApplication" ENUM  "FALSE","TRUE";
BA_DEF_ BO_  "GenMsgSendType" ENUM  "FixedPeriodic","Event","EnabledPeriodic","NotUsed","NotUsed","EventPeriodic","NotUsed","NotUsed","NoMsgSendType";
BA_DEF_ BO_  "GenMsgCycleTime" INT 0 100000;
BA_DEF_ BO_  "GenMsgDelayTime" INT 0 1000;
BA_DEF_ BO_  "GenMsgNrOfRepetition" INT 0 100;
BA_DEF_ BO_  "GenMsgStartDelayTime" INT 0 10000;
BA_DEF_ BO_  "EventRateOfChange" INT 10 10000;
BA_DEF_ BO_  "FrameGatewayId" HEX 0 1407;
BA_DEF_ BO_  "NetworkInitialization" ENUM  "No","Yes";
BA_DEF_ BO_  "FrameGatewayNetwork" STRING ;
BA_DEF_ BO_  "FrameRouting" STRING ;
BA_DEF_ BU_  "GatewayECU" ENUM  "No","Yes";
BA_DEF_ BU_  "PackageID" STRING ;
BA_DEF_ BU_  "NosPackage" ENUM  "None","I3_1","I3_2","1.0.1","RP","EuCD","Volcano","I3_3","FNOS_Autosar";
BA_DEF_ BU_  "NmStationAddress" INT 0 255;
BA_DEF_ BU_  "EOL_SB_Flash" ENUM  "GGDS","GDS","NONE","vector_leerstring";
BA_DEF_ BU_  "DiagNode" ENUM  "GGDS","GDS","NONE";
BA_DEF_ BU_  "PowerType" ENUM  "Switched","Latched","Sleep","vector_leerstring","vector_leerstring";
BA_DEF_ BU_  "NmAsrNode" ENUM  "No","Yes";
BA_DEF_ BU_  "NmAsrNodeIdentifier" HEX 0 255;
BA_DEF_ BU_  "NodeStartUpTime" INT 0 10000;
BA_DEF_ BU_  "NodeWakeUpTime" INT 0 10000;
BA_DEF_ BU_  "Terminator" ENUM  "No","Yes";
BA_DEF_ BU_  "ILUsed" ENUM  "No","Yes";
BA_DEF_ BU_  "OvtpEcuAddress" INT 0 1022;
BA_DEF_ BU_  "OvtpOperationMode" ENUM  "SERVER","CLIENT";
BA_DEF_  "NmMessageCount" INT 0 128;
BA_DEF_  "NmBaseAddress" HEX 1280 1280;
BA_DEF_  "VersionYear" INT 2000 3000;
BA_DEF_  "VersionMonth" INT 1 12;
BA_DEF_  "Manufacturer" STRING ;
BA_DEF_  "VersionDay" INT 1 31;
BA_DEF_  "DBName" STRING ;
BA_DEF_  "NmAsrBaseAddress" HEX 1280 1408;
BA_DEF_  "NmAsrMessageCount" INT 128 256;
BA_DEF_  "NmType" STRING ;
BA_DEF_  "CMDB_Version" STRING ;
BA_DEF_  "StarNetworkGwType" ENUM  "0=NotDefined","1=HS1","2=HS2","3=HS3","4=HS4","5=HS5","6=MS1","7=HS6","8=HS7","9=MS2","10=FD1","11=FD2","12=FD3","13=FD4","14=FD5","15=FD6","16=FD7","17=FD8";
BA_DEF_  "VersionNumber" INT 0 10000;
BA_DEF_  "NetworkSpeed" ENUM  "500kBits/s","125kBit/s";
BA_DEF_  "BusType" STRING ;
BA_DEF_DEF_  "U_CDX706_MY2023_Tx" "No";
BA_DEF_DEF_  "U_CDX706_MY2023_Rx" "No";
BA_DEF_DEF_  "AuthFreshnessCounterSyncAttempt" 2;
BA_DEF_DEF_  "VFrameFormat" "ExtendedCAN_FD";
BA_DEF_DEF_  "GenSigSendType" "NoSigSendType";
BA_DEF_DEF_  "GenSigInactiveValue" 0;
BA_DEF_DEF_  "WakeupSignal" "No";
BA_DEF_DEF_  "UsedOnPgmDBC" "Yes";
BA_DEF_DEF_  "GenSigStartValueInteger" 0;
BA_DEF_DEF_  "ContentDependant" "No";
BA_DEF_DEF_  "MetaData" "No";
BA_DEF_DEF_  "GenSigStartValue" 0;
BA_DEF_DEF_  "U_CX727_MY2021_Rx" "No";
BA_DEF_DEF_  "U_P702_MY2021_Rx" "No";
BA_DEF_DEF_  "U_T6_MCA_MY2020_Rx" "No";
BA_DEF_DEF_  "ECGUsedRxSignal" "No";
BA_DEF_DEF_  "U_CD542_MY2021_Rx" "No";
BA_DEF_DEF_  "U_U55X_MY2022_Rx" "No";
BA_DEF_DEF_  "U_CD764_MY2022_Rx" "No";
BA_DEF_DEF_  "U_CX727_MY2021_Tx" "No";
BA_DEF_DEF_  "U_P702_MY2021_Tx" "No";
BA_DEF_DEF_  "U_T6_MCA_MY2020_Tx" "No";
BA_DEF_DEF_  "ECGUsedTxSignal" "No";
BA_DEF_DEF_  "U_CD542_MY2021_Tx" "No";
BA_DEF_DEF_  "U_U55X_MY2022_Tx" "No";
BA_DEF_DEF_  "U_CD764_MY2022_Tx" "No";
BA_DEF_DEF_  "GenMsgILSupport" "Yes";
BA_DEF_DEF_  "DiagResponse" "No";
BA_DEF_DEF_  "DiagRequest" "No";
BA_DEF_DEF_  "TpTxIndex" 0;
BA_DEF_DEF_  "DiagState" "No";
BA_DEF_DEF_  "TpApplType" "";
BA_DEF_DEF_  "NmAsrMessage" "No";
BA_DEF_DEF_  "SCP_AuthInfoTxLength" 53;
BA_DEF_DEF_  "SCP_FreshnessValueTxLength" 11;
BA_DEF_DEF_  "SCP_FreshnessValueLength" 64;
BA_DEF_DEF_  "OvtpPushApplication" "FALSE";
BA_DEF_DEF_  "GenMsgSendType" "NoMsgSendType";
BA_DEF_DEF_  "GenMsgCycleTime" 0;
BA_DEF_DEF_  "GenMsgDelayTime" 20;
BA_DEF_DEF_  "GenMsgNrOfRepetition" 1;
BA_DEF_DEF_  "GenMsgStartDelayTime" 0;
BA_DEF_DEF_  "EventRateOfChange" 10000;
BA_DEF_DEF_  "FrameGatewayId" 0;
BA_DEF_DEF_  "NetworkInitialization" "Yes";
BA_DEF_DEF_  "FrameGatewayNetwork" "NONE";
BA_DEF_DEF_  "FrameRouting" "";
BA_DEF_DEF_  "GatewayECU" "No";
BA_DEF_DEF_  "PackageID" "08.05.00.00.71.xx.xx.rr.00.00";
BA_DEF_DEF_  "NosPackage" "I3_3";
BA_DEF_DEF_  "NmStationAddress" 0;
BA_DEF_DEF_  "EOL_SB_Flash" "GGDS";
BA_DEF_DEF_  "DiagNode" "GGDS";
BA_DEF_DEF_  "PowerType" "Switched";
BA_DEF_DEF_  "NmAsrNode" "No";
BA_DEF_DEF_  "NmAsrNodeIdentifier" 128;
BA_DEF_DEF_  "NodeStartUpTime" 250;
BA_DEF_DEF_  "NodeWakeUpTime" 100;
BA_DEF_DEF_  "Terminator" "No";
BA_DEF_DEF_  "ILUsed" "Yes";
BA_DEF_DEF_  "OvtpEcuAddress" 0;
BA_DEF_DEF_  "OvtpOperationMode" "SERVER";
BA_DEF_DEF_  "NmMessageCount" 128;
BA_DEF_DEF_  "NmBaseAddress" 1280;
BA_DEF_DEF_  "VersionYear" 2011;
BA_DEF_DEF_  "VersionMonth" 1;
BA_DEF_DEF_  "Manufacturer" "Ford";
BA_DEF_DEF_  "VersionDay" 1;
BA_DEF_DEF_  "DBName" "";
BA_DEF_DEF_  "NmAsrBaseAddress" 1408;
BA_DEF_DEF_  "NmAsrMessageCount" 128;
BA_DEF_DEF_  "NmType" "Ford-OSEK";
BA_DEF_DEF_  "CMDB_Version" "v11.01";
BA_DEF_DEF_  "StarNetworkGwType" "0=NotDefined";
BA_DEF_DEF_  "VersionNumber" 1;
BA_DEF_DEF_  "NetworkSpeed" "500kBits/s";
BA_DEF_DEF_  "BusType" "";
BA_ "VersionYear" 2020;
BA_ "VersionMonth" 10;
BA_ "VersionDay" 30;
BA_ "CMDB_Version" "FNV2_v20.12";
BA_ "StarNetworkGwType" 10;
BA_ "VersionNumber" 12;
BA_ "BusType" "CAN FD";
BA_ "DBName" "FD1_CAN";
BA_ "NmStationAddress" BU_ HCM 55;
BA_ "OvtpEcuAddress" BU_ HCM 113;
BA_ "NmStationAddress" BU_ IPMA_ADAS 28;
BA_ "NmAsrNode" BU_ IPMA_ADAS 1;
BA_ "NmAsrNodeIdentifier" BU_ IPMA_ADAS 156;
BA_ "NodeStartUpTime" BU_ IPMA_ADAS 300;
BA_ "OvtpEcuAddress" BU_ IPMA_ADAS 33;
BA_ "NmStationAddress" BU_ PSCM 53;
BA_ "PowerType" BU_ PSCM 1;
BA_ "NmAsrNode" BU_ PSCM 1;
BA_ "NmAsrNodeIdentifier" BU_ PSCM 181;
BA_ "Terminator" BU_ PSCM 1;
BA_ "OvtpEcuAddress" BU_ PSCM 48;
BA_ "NmStationAddress" BU_ ABS_ESC 22;
BA_ "PowerType" BU_ ABS_ESC 2;
BA_ "NmAsrNode" BU_ ABS_ESC 1;
BA_ "NmAsrNodeIdentifier" BU_ ABS_ESC 150;
BA_ "NodeStartUpTime" BU_ ABS_ESC 1000;
BA_ "NodeWakeUpTime" BU_ ABS_ESC 300;
BA_ "OvtpEcuAddress" BU_ ABS_ESC 40;
BA_ "NmStationAddress" BU_ PCM 21;
BA_ "PowerType" BU_ PCM 1;
BA_ "NmAsrNode" BU_ PCM 1;
BA_ "NmAsrNodeIdentifier" BU_ PCM 149;
BA_ "NodeStartUpTime" BU_ PCM 350;
BA_ "Terminator" BU_ PCM 1;
BA_ "OvtpEcuAddress" BU_ PCM 16;
BA_ "NmStationAddress" BU_ ECM_HEV 21;
BA_ "PowerType" BU_ ECM_HEV 1;
BA_ "NmAsrNode" BU_ ECM_HEV 1;
BA_ "NmAsrNodeIdentifier" BU_ ECM_HEV 149;
BA_ "NodeStartUpTime" BU_ ECM_HEV 350;
BA_ "Terminator" BU_ ECM_HEV 1;
BA_ "OvtpEcuAddress" BU_ ECM_HEV 16;
BA_ "NmStationAddress" BU_ VDM 48;
BA_ "PowerType" BU_ VDM 1;
BA_ "NmAsrNode" BU_ VDM 1;
BA_ "NmAsrNodeIdentifier" BU_ VDM 176;
BA_ "OvtpEcuAddress" BU_ VDM 32;
BA_ "NmStationAddress" BU_ CMR_DSMC 95;
BA_ "PowerType" BU_ CMR_DSMC 2;
BA_ "NmAsrNode" BU_ CMR_DSMC 1;
BA_ "NmAsrNodeIdentifier" BU_ CMR_DSMC 223;
BA_ "OvtpEcuAddress" BU_ CMR_DSMC 187;
BA_ "NmStationAddress" BU_ SOBDMC_HPCM 37;
BA_ "PowerType" BU_ SOBDMC_HPCM 1;
BA_ "NmAsrNode" BU_ SOBDMC_HPCM 1;
BA_ "NmAsrNodeIdentifier" BU_ SOBDMC_HPCM 165;
BA_ "OvtpEcuAddress" BU_ SOBDMC_HPCM 17;
BA_ "GatewayECU" BU_ GWM 1;
BA_ "NosPackage" BU_ GWM 4;
BA_ "NmStationAddress" BU_ GWM 30;
BA_ "PowerType" BU_ GWM 2;
BA_ "NmAsrNode" BU_ GWM 1;
BA_ "NmAsrNodeIdentifier" BU_ GWM 158;
BA_ "NodeStartUpTime" BU_ GWM 100;
BA_ "Terminator" BU_ GWM 1;
BA_ "OvtpEcuAddress" BU_ GWM 216;
BA_ "OvtpOperationMode" BU_ GWM 1;
BA_ "NmStationAddress" BU_ AWD_DLCM 112;
BA_ "PowerType" BU_ AWD_DLCM 1;
BA_ "NmAsrNode" BU_ AWD_DLCM 1;
BA_ "NmAsrNodeIdentifier" BU_ AWD_DLCM 240;
BA_ "NodeStartUpTime" BU_ AWD_DLCM 350;
BA_ "OvtpEcuAddress" BU_ AWD_DLCM 30;
BA_ "FrameRouting" BO_ 1176 "HS5_CAN,0x498;";
BA_ "FrameGatewayNetwork" BO_ 1176 "HS5_CAN";
BA_ "FrameGatewayId" BO_ 1176 1176;
BA_ "VFrameFormat" BO_ 1176 14;
BA_ "FrameRouting" BO_ 1175 "HS5_CAN,0x497;";
BA_ "FrameGatewayNetwork" BO_ 1175 "HS5_CAN";
BA_ "FrameGatewayId" BO_ 1175 1175;
BA_ "VFrameFormat" BO_ 1175 14;
BA_ "FrameRouting" BO_ 1174 "HS5_CAN,0x496;";
BA_ "FrameGatewayNetwork" BO_ 1174 "HS5_CAN";
BA_ "FrameGatewayId" BO_ 1174 1174;
BA_ "VFrameFormat" BO_ 1174 14;
BA_ "FrameRouting" BO_ 1173 "HS5_CAN,0x495;";
BA_ "FrameGatewayNetwork" BO_ 1173 "HS5_CAN";
BA_ "FrameGatewayId" BO_ 1173 1173;
BA_ "VFrameFormat" BO_ 1173 14;
BA_ "FrameRouting" BO_ 1172 "HS5_CAN,0x494;";
BA_ "FrameGatewayNetwork" BO_ 1172 "HS5_CAN";
BA_ "FrameGatewayId" BO_ 1172 1172;
BA_ "VFrameFormat" BO_ 1172 14;
BA_ "FrameRouting" BO_ 1171 "HS5_CAN,0x493;";
BA_ "FrameGatewayNetwork" BO_ 1171 "HS5_CAN";
BA_ "FrameGatewayId" BO_ 1171 1171;
BA_ "VFrameFormat" BO_ 1171 14;
BA_ "FrameRouting" BO_ 1170 "HS5_CAN,0x492;";
BA_ "FrameGatewayNetwork" BO_ 1170 "HS5_CAN";
BA_ "FrameGatewayId" BO_ 1170 1170;
BA_ "VFrameFormat" BO_ 1170 14;
BA_ "FrameRouting" BO_ 1169 "HS5_CAN,0x491;";
BA_ "FrameGatewayNetwork" BO_ 1169 "HS5_CAN";
BA_ "FrameGatewayId" BO_ 1169 1169;
BA_ "VFrameFormat" BO_ 1169 14;
BA_ "FrameRouting" BO_ 1188 "HS5_CAN,0x4A4;";
BA_ "FrameGatewayNetwork" BO_ 1188 "HS5_CAN";
BA_ "FrameGatewayId" BO_ 1188 1188;
BA_ "VFrameFormat" BO_ 1188 14;
BA_ "FrameRouting" BO_ 1187 "HS5_CAN,0x4A3;";
BA_ "FrameGatewayNetwork" BO_ 1187 "HS5_CAN";
BA_ "FrameGatewayId" BO_ 1187 1187;
BA_ "VFrameFormat" BO_ 1187 14;
BA_ "FrameRouting" BO_ 1168 "HS5_CAN,0x490;";
BA_ "FrameGatewayNetwork" BO_ 1168 "HS5_CAN";
BA_ "FrameGatewayId" BO_ 1168 1168;
BA_ "VFrameFormat" BO_ 1168 14;
BA_ "FrameRouting" BO_ 1185 "HS5_CAN,0x4A1;";
BA_ "FrameGatewayNetwork" BO_ 1185 "HS5_CAN";
BA_ "FrameGatewayId" BO_ 1185 1185;
BA_ "VFrameFormat" BO_ 1185 14;
BA_ "FrameRouting" BO_ 1184 "HS5_CAN,0x4A0;";
BA_ "FrameGatewayNetwork" BO_ 1184 "HS5_CAN";
BA_ "FrameGatewayId" BO_ 1184 1184;
BA_ "VFrameFormat" BO_ 1184 14;
BA_ "FrameRouting" BO_ 1183 "HS5_CAN,0x49F;";
BA_ "FrameGatewayNetwork" BO_ 1183 "HS5_CAN";
BA_ "FrameGatewayId" BO_ 1183 1183;
BA_ "VFrameFormat" BO_ 1183 14;
BA_ "FrameRouting" BO_ 1182 "HS5_CAN,0x49E;";
BA_ "FrameGatewayNetwork" BO_ 1182 "HS5_CAN";
BA_ "FrameGatewayId" BO_ 1182 1182;
BA_ "VFrameFormat" BO_ 1182 14;
BA_ "FrameRouting" BO_ 1181 "HS5_CAN,0x49D;";
BA_ "FrameGatewayNetwork" BO_ 1181 "HS5_CAN";
BA_ "FrameGatewayId" BO_ 1181 1181;
BA_ "VFrameFormat" BO_ 1181 14;
BA_ "FrameRouting" BO_ 1180 "HS5_CAN,0x49C;";
BA_ "FrameGatewayNetwork" BO_ 1180 "HS5_CAN";
BA_ "FrameGatewayId" BO_ 1180 1180;
BA_ "VFrameFormat" BO_ 1180 14;
BA_ "FrameRouting" BO_ 1179 "HS5_CAN,0x49B;";
BA_ "FrameGatewayNetwork" BO_ 1179 "HS5_CAN";
BA_ "FrameGatewayId" BO_ 1179 1179;
BA_ "VFrameFormat" BO_ 1179 14;
BA_ "FrameRouting" BO_ 1178 "HS5_CAN,0x49A;";
BA_ "FrameGatewayNetwork" BO_ 1178 "HS5_CAN";
BA_ "FrameGatewayId" BO_ 1178 1178;
BA_ "VFrameFormat" BO_ 1178 14;
BA_ "FrameRouting" BO_ 1177 "HS5_CAN,0x499;";
BA_ "FrameGatewayNetwork" BO_ 1177 "HS5_CAN";
BA_ "FrameGatewayId" BO_ 1177 1177;
BA_ "VFrameFormat" BO_ 1177 14;
BA_ "GenMsgCycleTime" BO_ 1186 100;
BA_ "GenMsgSendType" BO_ 1186 0;
BA_ "VFrameFormat" BO_ 1186 14;
BA_ "GenMsgCycleTime" BO_ 823 1000;
BA_ "GenMsgSendType" BO_ 823 5;
BA_ "VFrameFormat" BO_ 823 14;
BA_ "GenMsgCycleTime" BO_ 777 1000;
BA_ "GenMsgSendType" BO_ 777 5;
BA_ "VFrameFormat" BO_ 777 14;
BA_ "GenMsgCycleTime" BO_ 771 1000;
BA_ "GenMsgSendType" BO_ 771 5;
BA_ "VFrameFormat" BO_ 771 14;
BA_ "GenMsgCycleTime" BO_ 513 1000;
BA_ "GenMsgSendType" BO_ 513 5;
BA_ "VFrameFormat" BO_ 513 14;
BA_ "GenMsgDelayTime" BO_ 368 10;
BA_ "GenMsgCycleTime" BO_ 368 20;
BA_ "GenMsgSendType" BO_ 368 0;
BA_ "VFrameFormat" BO_ 368 14;
BA_ "GenMsgCycleTime" BO_ 536 50;
BA_ "GenMsgSendType" BO_ 536 0;
BA_ "VFrameFormat" BO_ 536 14;
BA_ "FrameGatewayId" BO_ 66 66;
BA_ "FrameGatewayNetwork" BO_ 66 "HS1_CAN";
BA_ "FrameRouting" BO_ 66 "HS1_CAN,0x42;";
BA_ "VFrameFormat" BO_ 66 14;
BA_ "GenMsgCycleTime" BO_ 770 1000;
BA_ "GenMsgSendType" BO_ 770 5;
BA_ "VFrameFormat" BO_ 770 14;
BA_ "GenMsgSendType" BO_ 897 0;
BA_ "GenMsgCycleTime" BO_ 897 1000;
BA_ "VFrameFormat" BO_ 897 14;
BA_ "GenMsgSendType" BO_ 896 0;
BA_ "GenMsgCycleTime" BO_ 896 1000;
BA_ "VFrameFormat" BO_ 896 14;
BA_ "GenMsgSendType" BO_ 925 0;
BA_ "GenMsgCycleTime" BO_ 925 1000;
BA_ "VFrameFormat" BO_ 925 14;
BA_ "GenMsgSendType" BO_ 785 5;
BA_ "GenMsgCycleTime" BO_ 785 1000;
BA_ "VFrameFormat" BO_ 785 14;
BA_ "FrameRouting" BO_ 932 "HS1_CAN,0x3A4";
BA_ "VFrameFormat" BO_ 932 14;
BA_ "FrameRouting" BO_ 816 "HS3_CAN,0x330";
BA_ "FrameGatewayNetwork" BO_ 816 "HS3_CAN";
BA_ "FrameGatewayId" BO_ 816 816;
BA_ "VFrameFormat" BO_ 816 14;
BA_ "FrameGatewayId" BO_ 646 646;
BA_ "FrameGatewayNetwork" BO_ 646 "HS5_CAN";
BA_ "FrameRouting" BO_ 646 "HS5_CAN,0x286;";
BA_ "VFrameFormat" BO_ 646 14;
BA_ "FrameGatewayId" BO_ 627 627;
BA_ "FrameGatewayNetwork" BO_ 627 "HS3_CAN";
BA_ "FrameRouting" BO_ 627 "HS3_CAN,0x273;";
BA_ "VFrameFormat" BO_ 627 14;
BA_ "FrameGatewayId" BO_ 630 630;
BA_ "FrameGatewayNetwork" BO_ 630 "HS3_CAN";
BA_ "FrameRouting" BO_ 630 "HS3_CAN,0x276;";
BA_ "VFrameFormat" BO_ 630 14;
BA_ "GenMsgSendType" BO_ 650 5;
BA_ "GenMsgCycleTime" BO_ 650 500;
BA_ "VFrameFormat" BO_ 650 14;
BA_ "GenMsgSendType" BO_ 655 0;
BA_ "GenMsgCycleTime" BO_ 655 500;
BA_ "VFrameFormat" BO_ 655 14;
BA_ "FrameGatewayId" BO_ 599 599;
BA_ "FrameGatewayNetwork" BO_ 599 "HS5_CAN";
BA_ "FrameRouting" BO_ 599 "HS5_CAN,0x257;";
BA_ "VFrameFormat" BO_ 599 14;
BA_ "FrameGatewayId" BO_ 595 595;
BA_ "FrameGatewayNetwork" BO_ 595 "HS3_CAN";
BA_ "FrameRouting" BO_ 595 "HS3_CAN,0x253;";
BA_ "VFrameFormat" BO_ 595 14;
BA_ "TpTxIndex" BO_ 2611034328 463550680;
BA_ "GenMsgSendType" BO_ 2611034328 1;
BA_ "GenMsgDelayTime" BO_ 2611034328 0;
BA_ "TpTxIndex" BO_ 2611035352 463551704;
BA_ "GenMsgSendType" BO_ 2611035352 1;
BA_ "GenMsgDelayTime" BO_ 2611035352 0;
BA_ "TpTxIndex" BO_ 2611175502 463550680;
BA_ "GenMsgSendType" BO_ 2611175502 1;
BA_ "GenMsgDelayTime" BO_ 2611175502 0;
BA_ "TpTxIndex" BO_ 2611175503 463551704;
BA_ "GenMsgSendType" BO_ 2611175503 1;
BA_ "GenMsgDelayTime" BO_ 2611175503 0;
BA_ "TpTxIndex" BO_ 2612224078 464599256;
BA_ "OvtpPushApplication" BO_ 2612224078 1;
BA_ "GenMsgSendType" BO_ 2612224078 1;
BA_ "GenMsgDelayTime" BO_ 2612224078 0;
BA_ "TpTxIndex" BO_ 2612224079 464600280;
BA_ "OvtpPushApplication" BO_ 2612224079 1;
BA_ "GenMsgSendType" BO_ 2612224079 1;
BA_ "GenMsgDelayTime" BO_ 2612224079 0;
BA_ "TpTxIndex" BO_ 2612082904 464599256;
BA_ "OvtpPushApplication" BO_ 2612082904 1;
BA_ "GenMsgSendType" BO_ 2612082904 1;
BA_ "GenMsgDelayTime" BO_ 2612082904 0;
BA_ "TpTxIndex" BO_ 2612083928 464600280;
BA_ "OvtpPushApplication" BO_ 2612083928 1;
BA_ "GenMsgSendType" BO_ 2612083928 1;
BA_ "GenMsgDelayTime" BO_ 2612083928 0;
BA_ "TpTxIndex" BO_ 2610126926 462502104;
BA_ "GenMsgSendType" BO_ 2610126926 1;
BA_ "GenMsgDelayTime" BO_ 2610126926 0;
BA_ "TpTxIndex" BO_ 2610126927 462503128;
BA_ "GenMsgSendType" BO_ 2610126927 1;
BA_ "GenMsgDelayTime" BO_ 2610126927 0;
BA_ "TpTxIndex" BO_ 2609985752 462502104;
BA_ "GenMsgSendType" BO_ 2609985752 1;
BA_ "GenMsgDelayTime" BO_ 2609985752 0;
BA_ "TpTxIndex" BO_ 2609986776 462503128;
BA_ "GenMsgSendType" BO_ 2609986776 1;
BA_ "GenMsgDelayTime" BO_ 2609986776 0;
BA_ "FrameGatewayId" BO_ 986 986;
BA_ "FrameGatewayNetwork" BO_ 986 "HS3_CAN";
BA_ "FrameRouting" BO_ 986 "HS3_CAN,0x3DA;";
BA_ "VFrameFormat" BO_ 986 14;
BA_ "GenMsgILSupport" BO_ 1822 0;
BA_ "DiagResponse" BO_ 1822 1;
BA_ "GenMsgSendType" BO_ 1822 1;
BA_ "GenMsgDelayTime" BO_ 1822 0;
BA_ "NetworkInitialization" BO_ 1822 0;
BA_ "VFrameFormat" BO_ 1822 14;
BA_ "GenMsgILSupport" BO_ 1438 0;
BA_ "NmAsrMessage" BO_ 1438 1;
BA_ "GenMsgSendType" BO_ 1438 0;
BA_ "GenMsgCycleTime" BO_ 1438 1000;
BA_ "NetworkInitialization" BO_ 1438 0;
BA_ "VFrameFormat" BO_ 1438 14;
BA_ "FrameGatewayId" BO_ 1191 1191;
BA_ "FrameGatewayNetwork" BO_ 1191 "HS5_CAN";
BA_ "FrameRouting" BO_ 1191 "HS5_CAN,0x4A7;";
BA_ "VFrameFormat" BO_ 1191 14;
BA_ "FrameGatewayId" BO_ 1190 1189;
BA_ "FrameGatewayNetwork" BO_ 1190 "HS5_CAN";
BA_ "FrameRouting" BO_ 1190 "HS5_CAN,0x4A5;";
BA_ "VFrameFormat" BO_ 1190 14;
BA_ "FrameGatewayId" BO_ 1192 1186;
BA_ "FrameGatewayNetwork" BO_ 1192 "HS5_CAN";
BA_ "FrameRouting" BO_ 1192 "HS5_CAN,0x4A2;";
BA_ "VFrameFormat" BO_ 1192 14;
BA_ "GenMsgSendType" BO_ 1245 5;
BA_ "GenMsgCycleTime" BO_ 1245 1000;
BA_ "VFrameFormat" BO_ 1245 14;
BA_ "GenMsgSendType" BO_ 1242 5;
BA_ "GenMsgCycleTime" BO_ 1242 1000;
BA_ "VFrameFormat" BO_ 1242 14;
BA_ "FrameGatewayId" BO_ 1116 1116;
BA_ "FrameGatewayNetwork" BO_ 1116 "HS3_CAN";
BA_ "FrameRouting" BO_ 1116 "HS3_CAN,0x45C;";
BA_ "VFrameFormat" BO_ 1116 14;
BA_ "GenMsgILSupport" BO_ 1844 0;
BA_ "DiagRequest" BO_ 1844 1;
BA_ "GenMsgSendType" BO_ 1844 1;
BA_ "GenMsgDelayTime" BO_ 1844 0;
BA_ "NetworkInitialization" BO_ 1844 0;
BA_ "VFrameFormat" BO_ 1844 14;
BA_ "FrameGatewayId" BO_ 954 954;
BA_ "FrameGatewayNetwork" BO_ 954 "HS1_CAN";
BA_ "FrameRouting" BO_ 954 "HS1_CAN,0x3BA;";
BA_ "VFrameFormat" BO_ 954 14;
BA_ "GenMsgILSupport" BO_ 1852 0;
BA_ "DiagResponse" BO_ 1852 1;
BA_ "GenMsgSendType" BO_ 1852 1;
BA_ "GenMsgDelayTime" BO_ 1852 0;
BA_ "NetworkInitialization" BO_ 1852 0;
BA_ "VFrameFormat" BO_ 1852 14;
BA_ "GenMsgSendType" BO_ 989 5;
BA_ "GenMsgCycleTime" BO_ 989 1000;
BA_ "VFrameFormat" BO_ 989 14;
BA_ "FrameGatewayId" BO_ 874 874;
BA_ "FrameGatewayNetwork" BO_ 874 "HS1_CAN";
BA_ "FrameRouting" BO_ 874 "HS1_CAN,0x36A;";
BA_ "VFrameFormat" BO_ 874 14;
BA_ "FrameGatewayId" BO_ 551 551;
BA_ "FrameGatewayNetwork" BO_ 551 "HS3_CAN";
BA_ "FrameRouting" BO_ 551 "HS3_CAN,0x227;";
BA_ "VFrameFormat" BO_ 551 14;
BA_ "FrameGatewayId" BO_ 132 132;
BA_ "FrameGatewayNetwork" BO_ 132 "HS1_CAN";
BA_ "FrameRouting" BO_ 132 "HS1_CAN,0x84;";
BA_ "VFrameFormat" BO_ 132 14;
BA_ "GenMsgSendType" BO_ 1006 5;
BA_ "GenMsgCycleTime" BO_ 1006 1000;
BA_ "VFrameFormat" BO_ 1006 14;
BA_ "FrameGatewayId" BO_ 1123 1123;
BA_ "FrameGatewayNetwork" BO_ 1123 "HS3_CAN";
BA_ "FrameRouting" BO_ 1123 "HS3_CAN,0x463;";
BA_ "VFrameFormat" BO_ 1123 14;
BA_ "FrameGatewayId" BO_ 1122 1122;
BA_ "FrameGatewayNetwork" BO_ 1122 "HS3_CAN";
BA_ "FrameRouting" BO_ 1122 "HS3_CAN,0x462;";
BA_ "VFrameFormat" BO_ 1122 14;
BA_ "FrameGatewayId" BO_ 1003 1003;
BA_ "FrameGatewayNetwork" BO_ 1003 "HS1_CAN";
BA_ "FrameRouting" BO_ 1003 "HS1_CAN,0x3EB;";
BA_ "VFrameFormat" BO_ 1003 14;
BA_ "FrameGatewayId" BO_ 580 580;
BA_ "FrameGatewayNetwork" BO_ 580 "HS5_CAN";
BA_ "FrameRouting" BO_ 580 "HS5_CAN,0x244;";
BA_ "VFrameFormat" BO_ 580 14;
BA_ "FrameGatewayId" BO_ 994 994;
BA_ "FrameGatewayNetwork" BO_ 994 "HS3_CAN";
BA_ "FrameRouting" BO_ 994 "HS3_CAN,0x3E2;";
BA_ "VFrameFormat" BO_ 994 14;
BA_ "FrameGatewayId" BO_ 992 992;
BA_ "FrameGatewayNetwork" BO_ 992 "HS3_CAN";
BA_ "FrameRouting" BO_ 992 "HS3_CAN,0x3E0;";
BA_ "VFrameFormat" BO_ 992 14;
BA_ "GenMsgCycleTime" BO_ 820 1000;
BA_ "GenMsgSendType" BO_ 820 5;
BA_ "VFrameFormat" BO_ 820 14;
BA_ "FrameGatewayId" BO_ 817 817;
BA_ "FrameGatewayNetwork" BO_ 817 "HS1_CAN";
BA_ "FrameRouting" BO_ 817 "HS1_CAN,0x331;";
BA_ "VFrameFormat" BO_ 817 14;
BA_ "FrameGatewayId" BO_ 129 129;
BA_ "FrameGatewayNetwork" BO_ 129 "HS2_CAN";
BA_ "FrameRouting" BO_ 129 "HS2_CAN,0x81;";
BA_ "VFrameFormat" BO_ 129 14;
BA_ "FrameGatewayId" BO_ 854 854;
BA_ "FrameGatewayNetwork" BO_ 854 "MS1_CAN";
BA_ "FrameRouting" BO_ 854 "MS1_CAN,0x356;";
BA_ "VFrameFormat" BO_ 854 14;
BA_ "FrameGatewayId" BO_ 549 549;
BA_ "FrameGatewayNetwork" BO_ 549 "HS3_CAN";
BA_ "FrameRouting" BO_ 549 "HS3_CAN,0x225;";
BA_ "VFrameFormat" BO_ 549 14;
BA_ "GenMsgSendType" BO_ 935 5;
BA_ "GenMsgCycleTime" BO_ 935 200;
BA_ "VFrameFormat" BO_ 935 14;
BA_ "U_CDX706_MY2023_Rx" SG_ 1176 BattTracCell45_U_Actl 1;
BA_ "GenSigStartValue" SG_ 1176 BattTracCell45_U_Actl 4094;
BA_ "GenSigStartValueInteger" SG_ 1176 BattTracCell45_U_Actl 4094;
BA_ "U_CDX706_MY2023_Rx" SG_ 1176 BattTracCell44_U_Actl 1;
BA_ "GenSigStartValue" SG_ 1176 BattTracCell44_U_Actl 4094;
BA_ "GenSigStartValueInteger" SG_ 1176 BattTracCell44_U_Actl 4094;
BA_ "U_CDX706_MY2023_Rx" SG_ 1176 BattTracCell43_U_Actl 1;
BA_ "GenSigStartValue" SG_ 1176 BattTracCell43_U_Actl 4094;
BA_ "GenSigStartValueInteger" SG_ 1176 BattTracCell43_U_Actl 4094;
BA_ "U_CDX706_MY2023_Rx" SG_ 1176 BattTracCell42_U_Actl 1;
BA_ "GenSigStartValue" SG_ 1176 BattTracCell42_U_Actl 4094;
BA_ "GenSigStartValueInteger" SG_ 1176 BattTracCell42_U_Actl 4094;
BA_ "U_CDX706_MY2023_Rx" SG_ 1176 BattTracCell41_U_Actl 1;
BA_ "GenSigStartValue" SG_ 1176 BattTracCell41_U_Actl 4094;
BA_ "GenSigStartValueInteger" SG_ 1176 BattTracCell41_U_Actl 4094;
BA_ "U_CDX706_MY2023_Rx" SG_ 1175 BattTracCell40_U_Actl 1;
BA_ "GenSigStartValue" SG_ 1175 BattTracCell40_U_Actl 4094;
BA_ "GenSigStartValueInteger" SG_ 1175 BattTracCell40_U_Actl 4094;
BA_ "U_CDX706_MY2023_Rx" SG_ 1175 BattTracCell39_U_Actl 1;
BA_ "GenSigStartValue" SG_ 1175 BattTracCell39_U_Actl 4094;
BA_ "GenSigStartValueInteger" SG_ 1175 BattTracCell39_U_Actl 4094;
BA_ "U_CDX706_MY2023_Rx" SG_ 1175 BattTracCell38_U_Actl 1;
BA_ "GenSigStartValue" SG_ 1175 BattTracCell38_U_Actl 4094;
BA_ "GenSigStartValueInteger" SG_ 1175 BattTracCell38_U_Actl 4094;
BA_ "U_CDX706_MY2023_Rx" SG_ 1175 BattTracCell37_U_Actl 1;
BA_ "GenSigStartValue" SG_ 1175 BattTracCell37_U_Actl 4094;
BA_ "GenSigStartValueInteger" SG_ 1175 BattTracCell37_U_Actl 4094;
BA_ "U_CDX706_MY2023_Rx" SG_ 1175 BattTracCell36_U_Actl 1;
BA_ "GenSigStartValue" SG_ 1175 BattTracCell36_U_Actl 4094;
BA_ "GenSigStartValueInteger" SG_ 1175 BattTracCell36_U_Actl 4094;
BA_ "U_CDX706_MY2023_Rx" SG_ 1174 BattTracCell35_U_Actl 1;
BA_ "GenSigStartValue" SG_ 1174 BattTracCell35_U_Actl 4094;
BA_ "GenSigStartValueInteger" SG_ 1174 BattTracCell35_U_Actl 4094;
BA_ "U_CDX706_MY2023_Rx" SG_ 1174 BattTracCell34_U_Actl 1;
BA_ "GenSigStartValue" SG_ 1174 BattTracCell34_U_Actl 4094;
BA_ "GenSigStartValueInteger" SG_ 1174 BattTracCell34_U_Actl 4094;
BA_ "U_CDX706_MY2023_Rx" SG_ 1174 BattTracCell33_U_Actl 1;
BA_ "GenSigStartValue" SG_ 1174 BattTracCell33_U_Actl 4094;
BA_ "GenSigStartValueInteger" SG_ 1174 BattTracCell33_U_Actl 4094;
BA_ "U_CDX706_MY2023_Rx" SG_ 1174 BattTracCell32_U_Actl 1;
BA_ "GenSigStartValue" SG_ 1174 BattTracCell32_U_Actl 4094;
BA_ "GenSigStartValueInteger" SG_ 1174 BattTracCell32_U_Actl 4094;
BA_ "U_CDX706_MY2023_Rx" SG_ 1174 BattTracCell31_U_Actl 1;
BA_ "GenSigStartValue" SG_ 1174 BattTracCell31_U_Actl 4094;
BA_ "GenSigStartValueInteger" SG_ 1174 BattTracCell31_U_Actl 4094;
BA_ "U_CDX706_MY2023_Rx" SG_ 1173 BattTracCell30_U_Actl 1;
BA_ "GenSigStartValue" SG_ 1173 BattTracCell30_U_Actl 4094;
BA_ "GenSigStartValueInteger" SG_ 1173 BattTracCell30_U_Actl 4094;
BA_ "U_CDX706_MY2023_Rx" SG_ 1173 BattTracCell29_U_Actl 1;
BA_ "GenSigStartValue" SG_ 1173 BattTracCell29_U_Actl 4094;
BA_ "GenSigStartValueInteger" SG_ 1173 BattTracCell29_U_Actl 4094;
BA_ "U_CDX706_MY2023_Rx" SG_ 1173 BattTracCell28_U_Actl 1;
BA_ "GenSigStartValue" SG_ 1173 BattTracCell28_U_Actl 4094;
BA_ "GenSigStartValueInteger" SG_ 1173 BattTracCell28_U_Actl 4094;
BA_ "U_CDX706_MY2023_Rx" SG_ 1173 BattTracCell27_U_Actl 1;
BA_ "GenSigStartValue" SG_ 1173 BattTracCell27_U_Actl 4094;
BA_ "GenSigStartValueInteger" SG_ 1173 BattTracCell27_U_Actl 4094;
BA_ "U_CDX706_MY2023_Rx" SG_ 1173 BattTracCell26_U_Actl 1;
BA_ "GenSigStartValue" SG_ 1173 BattTracCell26_U_Actl 4094;
BA_ "GenSigStartValueInteger" SG_ 1173 BattTracCell26_U_Actl 4094;
BA_ "U_CDX706_MY2023_Rx" SG_ 1172 BattTracCell25_U_Actl 1;
BA_ "GenSigStartValue" SG_ 1172 BattTracCell25_U_Actl 4094;
BA_ "GenSigStartValueInteger" SG_ 1172 BattTracCell25_U_Actl 4094;
BA_ "U_CDX706_MY2023_Rx" SG_ 1172 BattTracCell24_U_Actl 1;
BA_ "GenSigStartValue" SG_ 1172 BattTracCell24_U_Actl 4094;
BA_ "GenSigStartValueInteger" SG_ 1172 BattTracCell24_U_Actl 4094;
BA_ "U_CDX706_MY2023_Rx" SG_ 1172 BattTracCell23_U_Actl 1;
BA_ "GenSigStartValue" SG_ 1172 BattTracCell23_U_Actl 4094;
BA_ "GenSigStartValueInteger" SG_ 1172 BattTracCell23_U_Actl 4094;
BA_ "U_CDX706_MY2023_Rx" SG_ 1172 BattTracCell22_U_Actl 1;
BA_ "GenSigStartValue" SG_ 1172 BattTracCell22_U_Actl 4094;
BA_ "GenSigStartValueInteger" SG_ 1172 BattTracCell22_U_Actl 4094;
BA_ "U_CDX706_MY2023_Rx" SG_ 1172 BattTracCell21_U_Actl 1;
BA_ "GenSigStartValue" SG_ 1172 BattTracCell21_U_Actl 4094;
BA_ "GenSigStartValueInteger" SG_ 1172 BattTracCell21_U_Actl 4094;
BA_ "U_CDX706_MY2023_Rx" SG_ 1171 BattTracCell20_U_Actl 1;
BA_ "GenSigStartValue" SG_ 1171 BattTracCell20_U_Actl 4094;
BA_ "GenSigStartValueInteger" SG_ 1171 BattTracCell20_U_Actl 4094;
BA_ "U_CDX706_MY2023_Rx" SG_ 1171 BattTracCell19_U_Actl 1;
BA_ "GenSigStartValue" SG_ 1171 BattTracCell19_U_Actl 4094;
BA_ "GenSigStartValueInteger" SG_ 1171 BattTracCell19_U_Actl 4094;
BA_ "U_CDX706_MY2023_Rx" SG_ 1171 BattTracCell18_U_Actl 1;
BA_ "GenSigStartValue" SG_ 1171 BattTracCell18_U_Actl 4094;
BA_ "GenSigStartValueInteger" SG_ 1171 BattTracCell18_U_Actl 4094;
BA_ "U_CDX706_MY2023_Rx" SG_ 1171 BattTracCell17_U_Actl 1;
BA_ "GenSigStartValue" SG_ 1171 BattTracCell17_U_Actl 4094;
BA_ "GenSigStartValueInteger" SG_ 1171 BattTracCell17_U_Actl 4094;
BA_ "U_CDX706_MY2023_Rx" SG_ 1171 BattTracCell16_U_Actl 1;
BA_ "GenSigStartValue" SG_ 1171 BattTracCell16_U_Actl 4094;
BA_ "GenSigStartValueInteger" SG_ 1171 BattTracCell16_U_Actl 4094;
BA_ "U_CDX706_MY2023_Rx" SG_ 1170 BattTracCell15_U_Actl 1;
BA_ "GenSigStartValue" SG_ 1170 BattTracCell15_U_Actl 4094;
BA_ "GenSigStartValueInteger" SG_ 1170 BattTracCell15_U_Actl 4094;
BA_ "U_CDX706_MY2023_Rx" SG_ 1170 BattTracCell14_U_Actl 1;
BA_ "GenSigStartValue" SG_ 1170 BattTracCell14_U_Actl 4094;
BA_ "GenSigStartValueInteger" SG_ 1170 BattTracCell14_U_Actl 4094;
BA_ "U_CDX706_MY2023_Rx" SG_ 1170 BattTracCell13_U_Actl 1;
BA_ "GenSigStartValue" SG_ 1170 BattTracCell13_U_Actl 4094;
BA_ "GenSigStartValueInteger" SG_ 1170 BattTracCell13_U_Actl 4094;
BA_ "U_CDX706_MY2023_Rx" SG_ 1170 BattTracCell12_U_Actl 1;
BA_ "GenSigStartValue" SG_ 1170 BattTracCell12_U_Actl 4094;
BA_ "GenSigStartValueInteger" SG_ 1170 BattTracCell12_U_Actl 4094;
BA_ "U_CDX706_MY2023_Rx" SG_ 1170 BattTracCell11_U_Actl 1;
BA_ "GenSigStartValue" SG_ 1170 BattTracCell11_U_Actl 4094;
BA_ "GenSigStartValueInteger" SG_ 1170 BattTracCell11_U_Actl 4094;
BA_ "U_CDX706_MY2023_Rx" SG_ 1169 BattTracCell10_U_Actl 1;
BA_ "GenSigStartValue" SG_ 1169 BattTracCell10_U_Actl 4094;
BA_ "GenSigStartValueInteger" SG_ 1169 BattTracCell10_U_Actl 4094;
BA_ "U_CDX706_MY2023_Rx" SG_ 1169 BattTracCell09_U_Actl 1;
BA_ "GenSigStartValue" SG_ 1169 BattTracCell09_U_Actl 4094;
BA_ "GenSigStartValueInteger" SG_ 1169 BattTracCell09_U_Actl 4094;
BA_ "U_CDX706_MY2023_Rx" SG_ 1169 BattTracCell08_U_Actl 1;
BA_ "GenSigStartValue" SG_ 1169 BattTracCell08_U_Actl 4094;
BA_ "GenSigStartValueInteger" SG_ 1169 BattTracCell08_U_Actl 4094;
BA_ "U_CDX706_MY2023_Rx" SG_ 1169 BattTracCell07_U_Actl 1;
BA_ "GenSigStartValue" SG_ 1169 BattTracCell07_U_Actl 4094;
BA_ "GenSigStartValueInteger" SG_ 1169 BattTracCell07_U_Actl 4094;
BA_ "U_CDX706_MY2023_Rx" SG_ 1169 BattTracCell06_U_Actl 1;
BA_ "GenSigStartValue" SG_ 1169 BattTracCell06_U_Actl 4094;
BA_ "GenSigStartValueInteger" SG_ 1169 BattTracCell06_U_Actl 4094;
BA_ "U_CDX706_MY2023_Rx" SG_ 1188 BattTracTe13_Te_Actl 1;
BA_ "GenSigStartValue" SG_ 1188 BattTracTe13_Te_Actl 254;
BA_ "GenSigStartValueInteger" SG_ 1188 BattTracTe13_Te_Actl 254;
BA_ "U_CDX706_MY2023_Rx" SG_ 1188 BattTracTe12_Te_Actl 1;
BA_ "GenSigStartValue" SG_ 1188 BattTracTe12_Te_Actl 254;
BA_ "GenSigStartValueInteger" SG_ 1188 BattTracTe12_Te_Actl 254;
BA_ "U_CDX706_MY2023_Rx" SG_ 1188 BattTracTe11_Te_Actl 1;
BA_ "GenSigStartValue" SG_ 1188 BattTracTe11_Te_Actl 254;
BA_ "GenSigStartValueInteger" SG_ 1188 BattTracTe11_Te_Actl 254;
BA_ "U_CDX706_MY2023_Rx" SG_ 1188 BattTracTe10_Te_Actl 1;
BA_ "GenSigStartValue" SG_ 1188 BattTracTe10_Te_Actl 254;
BA_ "GenSigStartValueInteger" SG_ 1188 BattTracTe10_Te_Actl 254;
BA_ "U_CDX706_MY2023_Rx" SG_ 1188 BattTracTe09_Te_Actl 1;
BA_ "GenSigStartValue" SG_ 1188 BattTracTe09_Te_Actl 254;
BA_ "GenSigStartValueInteger" SG_ 1188 BattTracTe09_Te_Actl 254;
BA_ "U_CDX706_MY2023_Rx" SG_ 1188 BattTracTe08_Te_Actl 1;
BA_ "GenSigStartValue" SG_ 1188 BattTracTe08_Te_Actl 254;
BA_ "GenSigStartValueInteger" SG_ 1188 BattTracTe08_Te_Actl 254;
BA_ "U_CDX706_MY2023_Rx" SG_ 1188 BattTracTe07_Te_Actl 1;
BA_ "GenSigStartValue" SG_ 1188 BattTracTe07_Te_Actl 254;
BA_ "GenSigStartValueInteger" SG_ 1188 BattTracTe07_Te_Actl 254;
BA_ "U_CDX706_MY2023_Rx" SG_ 1187 BattTracTe06_Te_Actl 1;
BA_ "GenSigStartValue" SG_ 1187 BattTracTe06_Te_Actl 254;
BA_ "GenSigStartValueInteger" SG_ 1187 BattTracTe06_Te_Actl 254;
BA_ "U_CDX706_MY2023_Rx" SG_ 1187 BattTracTe05_Te_Actl 1;
BA_ "GenSigStartValue" SG_ 1187 BattTracTe05_Te_Actl 254;
BA_ "GenSigStartValueInteger" SG_ 1187 BattTracTe05_Te_Actl 254;
BA_ "U_CDX706_MY2023_Rx" SG_ 1187 BattTracTe04_Te_Actl 1;
BA_ "GenSigStartValue" SG_ 1187 BattTracTe04_Te_Actl 254;
BA_ "GenSigStartValueInteger" SG_ 1187 BattTracTe04_Te_Actl 254;
BA_ "U_CDX706_MY2023_Rx" SG_ 1187 BattTracTe03_Te_Actl 1;
BA_ "GenSigStartValue" SG_ 1187 BattTracTe03_Te_Actl 254;
BA_ "GenSigStartValueInteger" SG_ 1187 BattTracTe03_Te_Actl 254;
BA_ "U_CDX706_MY2023_Rx" SG_ 1187 BattTracTe02_Te_Actl 1;
BA_ "GenSigStartValue" SG_ 1187 BattTracTe02_Te_Actl 254;
BA_ "GenSigStartValueInteger" SG_ 1187 BattTracTe02_Te_Actl 254;
BA_ "U_CDX706_MY2023_Rx" SG_ 1187 BattTracTe01_Te_Actl 1;
BA_ "GenSigStartValue" SG_ 1187 BattTracTe01_Te_Actl 254;
BA_ "GenSigStartValueInteger" SG_ 1187 BattTracTe01_Te_Actl 254;
BA_ "U_CDX706_MY2023_Rx" SG_ 1187 BattTracCell96_U_Actl 1;
BA_ "GenSigStartValue" SG_ 1187 BattTracCell96_U_Actl 4094;
BA_ "GenSigStartValueInteger" SG_ 1187 BattTracCell96_U_Actl 4094;
BA_ "U_CDX706_MY2023_Rx" SG_ 1168 BattTracCell05_U_Actl 1;
BA_ "GenSigStartValue" SG_ 1168 BattTracCell05_U_Actl 4094;
BA_ "GenSigStartValueInteger" SG_ 1168 BattTracCell05_U_Actl 4094;
BA_ "U_CDX706_MY2023_Rx" SG_ 1168 BattTracCell04_U_Actl 1;
BA_ "GenSigStartValue" SG_ 1168 BattTracCell04_U_Actl 4094;
BA_ "GenSigStartValueInteger" SG_ 1168 BattTracCell04_U_Actl 4094;
BA_ "U_CDX706_MY2023_Rx" SG_ 1168 BattTracCell03_U_Actl 1;
BA_ "GenSigStartValue" SG_ 1168 BattTracCell03_U_Actl 4094;
BA_ "GenSigStartValueInteger" SG_ 1168 BattTracCell03_U_Actl 4094;
BA_ "U_CDX706_MY2023_Rx" SG_ 1168 BattTracCell02_U_Actl 1;
BA_ "GenSigStartValue" SG_ 1168 BattTracCell02_U_Actl 4094;
BA_ "GenSigStartValueInteger" SG_ 1168 BattTracCell02_U_Actl 4094;
BA_ "U_CDX706_MY2023_Rx" SG_ 1168 BattTracCell01_U_Actl 1;
BA_ "GenSigStartValue" SG_ 1168 BattTracCell01_U_Actl 4094;
BA_ "GenSigStartValueInteger" SG_ 1168 BattTracCell01_U_Actl 4094;
BA_ "U_CDX706_MY2023_Rx" SG_ 1185 BattTracCell90_U_Actl 1;
BA_ "GenSigStartValue" SG_ 1185 BattTracCell90_U_Actl 4094;
BA_ "GenSigStartValueInteger" SG_ 1185 BattTracCell90_U_Actl 4094;
BA_ "U_CDX706_MY2023_Rx" SG_ 1185 BattTracCell89_U_Actl 1;
BA_ "GenSigStartValue" SG_ 1185 BattTracCell89_U_Actl 4094;
BA_ "GenSigStartValueInteger" SG_ 1185 BattTracCell89_U_Actl 4094;
BA_ "U_CDX706_MY2023_Rx" SG_ 1185 BattTracCell88_U_Actl 1;
BA_ "GenSigStartValue" SG_ 1185 BattTracCell88_U_Actl 4094;
BA_ "GenSigStartValueInteger" SG_ 1185 BattTracCell88_U_Actl 4094;
BA_ "U_CDX706_MY2023_Rx" SG_ 1185 BattTracCell87_U_Actl 1;
BA_ "GenSigStartValue" SG_ 1185 BattTracCell87_U_Actl 4094;
BA_ "GenSigStartValueInteger" SG_ 1185 BattTracCell87_U_Actl 4094;
BA_ "U_CDX706_MY2023_Rx" SG_ 1185 BattTracCell86_U_Actl 1;
BA_ "GenSigStartValue" SG_ 1185 BattTracCell86_U_Actl 4094;
BA_ "GenSigStartValueInteger" SG_ 1185 BattTracCell86_U_Actl 4094;
BA_ "U_CDX706_MY2023_Rx" SG_ 1184 BattTracCell85_U_Actl 1;
BA_ "GenSigStartValue" SG_ 1184 BattTracCell85_U_Actl 4094;
BA_ "GenSigStartValueInteger" SG_ 1184 BattTracCell85_U_Actl 4094;
BA_ "U_CDX706_MY2023_Rx" SG_ 1184 BattTracCell84_U_Actl 1;
BA_ "GenSigStartValue" SG_ 1184 BattTracCell84_U_Actl 4094;
BA_ "GenSigStartValueInteger" SG_ 1184 BattTracCell84_U_Actl 4094;
BA_ "U_CDX706_MY2023_Rx" SG_ 1184 BattTracCell83_U_Actl 1;
BA_ "GenSigStartValue" SG_ 1184 BattTracCell83_U_Actl 4094;
BA_ "GenSigStartValueInteger" SG_ 1184 BattTracCell83_U_Actl 4094;
BA_ "U_CDX706_MY2023_Rx" SG_ 1184 BattTracCell82_U_Actl 1;
BA_ "GenSigStartValue" SG_ 1184 BattTracCell82_U_Actl 4094;
BA_ "GenSigStartValueInteger" SG_ 1184 BattTracCell82_U_Actl 4094;
BA_ "U_CDX706_MY2023_Rx" SG_ 1184 BattTracCell81_U_Actl 1;
BA_ "GenSigStartValue" SG_ 1184 BattTracCell81_U_Actl 4094;
BA_ "GenSigStartValueInteger" SG_ 1184 BattTracCell81_U_Actl 4094;
BA_ "U_CDX706_MY2023_Rx" SG_ 1183 BattTracCell80_U_Actl 1;
BA_ "GenSigStartValue" SG_ 1183 BattTracCell80_U_Actl 4094;
BA_ "GenSigStartValueInteger" SG_ 1183 BattTracCell80_U_Actl 4094;
BA_ "U_CDX706_MY2023_Rx" SG_ 1183 BattTracCell79_U_Actl 1;
BA_ "GenSigStartValue" SG_ 1183 BattTracCell79_U_Actl 4094;
BA_ "GenSigStartValueInteger" SG_ 1183 BattTracCell79_U_Actl 4094;
BA_ "U_CDX706_MY2023_Rx" SG_ 1183 BattTracCell78_U_Actl 1;
BA_ "GenSigStartValue" SG_ 1183 BattTracCell78_U_Actl 4094;
BA_ "GenSigStartValueInteger" SG_ 1183 BattTracCell78_U_Actl 4094;
BA_ "U_CDX706_MY2023_Rx" SG_ 1183 BattTracCell77_U_Actl 1;
BA_ "GenSigStartValue" SG_ 1183 BattTracCell77_U_Actl 4094;
BA_ "GenSigStartValueInteger" SG_ 1183 BattTracCell77_U_Actl 4094;
BA_ "U_CDX706_MY2023_Rx" SG_ 1183 BattTracCell76_U_Actl 1;
BA_ "GenSigStartValue" SG_ 1183 BattTracCell76_U_Actl 4094;
BA_ "GenSigStartValueInteger" SG_ 1183 BattTracCell76_U_Actl 4094;
BA_ "U_CDX706_MY2023_Rx" SG_ 1182 BattTracCell75_U_Actl 1;
BA_ "GenSigStartValue" SG_ 1182 BattTracCell75_U_Actl 4094;
BA_ "GenSigStartValueInteger" SG_ 1182 BattTracCell75_U_Actl 4094;
BA_ "U_CDX706_MY2023_Rx" SG_ 1182 BattTracCell74_U_Actl 1;
BA_ "GenSigStartValue" SG_ 1182 BattTracCell74_U_Actl 4094;
BA_ "GenSigStartValueInteger" SG_ 1182 BattTracCell74_U_Actl 4094;
BA_ "U_CDX706_MY2023_Rx" SG_ 1182 BattTracCell73_U_Actl 1;
BA_ "GenSigStartValue" SG_ 1182 BattTracCell73_U_Actl 4094;
BA_ "GenSigStartValueInteger" SG_ 1182 BattTracCell73_U_Actl 4094;
BA_ "U_CDX706_MY2023_Rx" SG_ 1182 BattTracCell72_U_Actl 1;
BA_ "GenSigStartValue" SG_ 1182 BattTracCell72_U_Actl 4094;
BA_ "GenSigStartValueInteger" SG_ 1182 BattTracCell72_U_Actl 4094;
BA_ "U_CDX706_MY2023_Rx" SG_ 1182 BattTracCell71_U_Actl 1;
BA_ "GenSigStartValue" SG_ 1182 BattTracCell71_U_Actl 4094;
BA_ "GenSigStartValueInteger" SG_ 1182 BattTracCell71_U_Actl 4094;
BA_ "U_CDX706_MY2023_Rx" SG_ 1181 BattTracCell70_U_Actl 1;
BA_ "GenSigStartValue" SG_ 1181 BattTracCell70_U_Actl 4094;
BA_ "GenSigStartValueInteger" SG_ 1181 BattTracCell70_U_Actl 4094;
BA_ "U_CDX706_MY2023_Rx" SG_ 1181 BattTracCell69_U_Actl 1;
BA_ "GenSigStartValue" SG_ 1181 BattTracCell69_U_Actl 4094;
BA_ "GenSigStartValueInteger" SG_ 1181 BattTracCell69_U_Actl 4094;
BA_ "U_CDX706_MY2023_Rx" SG_ 1181 BattTracCell68_U_Actl 1;
BA_ "GenSigStartValue" SG_ 1181 BattTracCell68_U_Actl 4094;
BA_ "GenSigStartValueInteger" SG_ 1181 BattTracCell68_U_Actl 4094;
BA_ "U_CDX706_MY2023_Rx" SG_ 1181 BattTracCell67_U_Actl 1;
BA_ "GenSigStartValue" SG_ 1181 BattTracCell67_U_Actl 4094;
BA_ "GenSigStartValueInteger" SG_ 1181 BattTracCell67_U_Actl 4094;
BA_ "U_CDX706_MY2023_Rx" SG_ 1181 BattTracCell66_U_Actl 1;
BA_ "GenSigStartValue" SG_ 1181 BattTracCell66_U_Actl 4094;
BA_ "GenSigStartValueInteger" SG_ 1181 BattTracCell66_U_Actl 4094;
BA_ "U_CDX706_MY2023_Rx" SG_ 1180 BattTracCell65_U_Actl 1;
BA_ "GenSigStartValue" SG_ 1180 BattTracCell65_U_Actl 4094;
BA_ "GenSigStartValueInteger" SG_ 1180 BattTracCell65_U_Actl 4094;
BA_ "U_CDX706_MY2023_Rx" SG_ 1180 BattTracCell64_U_Actl 1;
BA_ "GenSigStartValue" SG_ 1180 BattTracCell64_U_Actl 4094;
BA_ "GenSigStartValueInteger" SG_ 1180 BattTracCell64_U_Actl 4094;
BA_ "U_CDX706_MY2023_Rx" SG_ 1180 BattTracCell63_U_Actl 1;
BA_ "GenSigStartValue" SG_ 1180 BattTracCell63_U_Actl 4094;
BA_ "GenSigStartValueInteger" SG_ 1180 BattTracCell63_U_Actl 4094;
BA_ "U_CDX706_MY2023_Rx" SG_ 1180 BattTracCell62_U_Actl 1;
BA_ "GenSigStartValue" SG_ 1180 BattTracCell62_U_Actl 4094;
BA_ "GenSigStartValueInteger" SG_ 1180 BattTracCell62_U_Actl 4094;
BA_ "U_CDX706_MY2023_Rx" SG_ 1180 BattTracCell61_U_Actl 1;
BA_ "GenSigStartValue" SG_ 1180 BattTracCell61_U_Actl 4094;
BA_ "GenSigStartValueInteger" SG_ 1180 BattTracCell61_U_Actl 4094;
BA_ "U_CDX706_MY2023_Rx" SG_ 1179 BattTracCell60_U_Actl 1;
BA_ "GenSigStartValue" SG_ 1179 BattTracCell60_U_Actl 4094;
BA_ "GenSigStartValueInteger" SG_ 1179 BattTracCell60_U_Actl 4094;
BA_ "U_CDX706_MY2023_Rx" SG_ 1179 BattTracCell59_U_Actl 1;
BA_ "GenSigStartValue" SG_ 1179 BattTracCell59_U_Actl 4094;
BA_ "GenSigStartValueInteger" SG_ 1179 BattTracCell59_U_Actl 4094;
BA_ "U_CDX706_MY2023_Rx" SG_ 1179 BattTracCell58_U_Actl 1;
BA_ "GenSigStartValue" SG_ 1179 BattTracCell58_U_Actl 4094;
BA_ "GenSigStartValueInteger" SG_ 1179 BattTracCell58_U_Actl 4094;
BA_ "U_CDX706_MY2023_Rx" SG_ 1179 BattTracCell57_U_Actl 1;
BA_ "GenSigStartValue" SG_ 1179 BattTracCell57_U_Actl 4094;
BA_ "GenSigStartValueInteger" SG_ 1179 BattTracCell57_U_Actl 4094;
BA_ "U_CDX706_MY2023_Rx" SG_ 1179 BattTracCell56_U_Actl 1;
BA_ "GenSigStartValue" SG_ 1179 BattTracCell56_U_Actl 4094;
BA_ "GenSigStartValueInteger" SG_ 1179 BattTracCell56_U_Actl 4094;
BA_ "U_CDX706_MY2023_Rx" SG_ 1178 BattTracCell55_U_Actl 1;
BA_ "GenSigStartValue" SG_ 1178 BattTracCell55_U_Actl 4094;
BA_ "GenSigStartValueInteger" SG_ 1178 BattTracCell55_U_Actl 4094;
BA_ "U_CDX706_MY2023_Rx" SG_ 1178 BattTracCell54_U_Actl 1;
BA_ "GenSigStartValue" SG_ 1178 BattTracCell54_U_Actl 4094;
BA_ "GenSigStartValueInteger" SG_ 1178 BattTracCell54_U_Actl 4094;
BA_ "U_CDX706_MY2023_Rx" SG_ 1178 BattTracCell53_U_Actl 1;
BA_ "GenSigStartValue" SG_ 1178 BattTracCell53_U_Actl 4094;
BA_ "GenSigStartValueInteger" SG_ 1178 BattTracCell53_U_Actl 4094;
BA_ "U_CDX706_MY2023_Rx" SG_ 1178 BattTracCell52_U_Actl 1;
BA_ "GenSigStartValue" SG_ 1178 BattTracCell52_U_Actl 4094;
BA_ "GenSigStartValueInteger" SG_ 1178 BattTracCell52_U_Actl 4094;
BA_ "U_CDX706_MY2023_Rx" SG_ 1178 BattTracCell51_U_Actl 1;
BA_ "GenSigStartValue" SG_ 1178 BattTracCell51_U_Actl 4094;
BA_ "GenSigStartValueInteger" SG_ 1178 BattTracCell51_U_Actl 4094;
BA_ "U_CDX706_MY2023_Rx" SG_ 1177 BattTracCell50_U_Actl 1;
BA_ "GenSigStartValue" SG_ 1177 BattTracCell50_U_Actl 4094;
BA_ "GenSigStartValueInteger" SG_ 1177 BattTracCell50_U_Actl 4094;
BA_ "U_CDX706_MY2023_Rx" SG_ 1177 BattTracCell49_U_Actl 1;
BA_ "GenSigStartValue" SG_ 1177 BattTracCell49_U_Actl 4094;
BA_ "GenSigStartValueInteger" SG_ 1177 BattTracCell49_U_Actl 4094;
BA_ "U_CDX706_MY2023_Rx" SG_ 1177 BattTracCell48_U_Actl 1;
BA_ "GenSigStartValue" SG_ 1177 BattTracCell48_U_Actl 4094;
BA_ "GenSigStartValueInteger" SG_ 1177 BattTracCell48_U_Actl 4094;
BA_ "U_CDX706_MY2023_Rx" SG_ 1177 BattTracCell47_U_Actl 1;
BA_ "GenSigStartValue" SG_ 1177 BattTracCell47_U_Actl 4094;
BA_ "GenSigStartValueInteger" SG_ 1177 BattTracCell47_U_Actl 4094;
BA_ "U_CDX706_MY2023_Rx" SG_ 1177 BattTracCell46_U_Actl 1;
BA_ "GenSigStartValue" SG_ 1177 BattTracCell46_U_Actl 4094;
BA_ "GenSigStartValueInteger" SG_ 1177 BattTracCell46_U_Actl 4094;
BA_ "U_T6_MCA_MY2020_Tx" SG_ 1186 RearDiffLckMsg_D_Rq 1;
BA_ "U_P702_MY2021_Tx" SG_ 1186 RearDiffLckMsg_D_Rq 1;
BA_ "U_T6_MCA_MY2020_Tx" SG_ 1186 RearDiffLck_Tq_Actl 1;
BA_ "U_P702_MY2021_Tx" SG_ 1186 RearDiffLck_Tq_Actl 1;
BA_ "U_CDX706_MY2023_Rx" SG_ 1186 RearDiffLck_Tq_Actl 1;
BA_ "U_U55X_MY2022_Rx" SG_ 1186 RearDiffLck_Tq_Actl 1;
BA_ "U_T6_MCA_MY2020_Rx" SG_ 1186 RearDiffLck_Tq_Actl 1;
BA_ "U_P702_MY2021_Rx" SG_ 1186 RearDiffLck_Tq_Actl 1;
BA_ "U_T6_MCA_MY2020_Tx" SG_ 1186 RearDiffFalt_D_Stat 1;
BA_ "U_P702_MY2021_Tx" SG_ 1186 RearDiffFalt_D_Stat 1;
BA_ "U_U55X_MY2022_Rx" SG_ 1186 RearDiffFalt_D_Stat 1;
BA_ "U_T6_MCA_MY2020_Rx" SG_ 1186 RearDiffFalt_D_Stat 1;
BA_ "U_P702_MY2021_Rx" SG_ 1186 RearDiffFalt_D_Stat 1;
BA_ "U_T6_MCA_MY2020_Tx" SG_ 1186 LsdSrvcRqd_B_Rq 1;
BA_ "U_P702_MY2021_Tx" SG_ 1186 LsdSrvcRqd_B_Rq 1;
BA_ "U_T6_MCA_MY2020_Tx" SG_ 1186 FrontDiffLckLamp_D_Rq 1;
BA_ "U_CDX706_MY2023_Rx" SG_ 1186 FrontDiffLckLamp_D_Rq 1;
BA_ "U_CD764_MY2022_Rx" SG_ 1186 FrontDiffLckLamp_D_Rq 1;
BA_ "U_CD542_MY2021_Rx" SG_ 1186 FrontDiffLckLamp_D_Rq 1;
BA_ "ECGUsedRxSignal" SG_ 1186 FrontDiffLckLamp_D_Rq 1;
BA_ "U_T6_MCA_MY2020_Rx" SG_ 1186 FrontDiffLckLamp_D_Rq 1;
BA_ "U_CDX706_MY2023_Rx" SG_ 823 DteVehPwId_No_Actl 1;
BA_ "U_U55X_MY2022_Rx" SG_ 823 DteVehPwId_No_Actl 1;
BA_ "U_CD542_MY2021_Rx" SG_ 823 DteVehPwId_No_Actl 1;
BA_ "ECGUsedRxSignal" SG_ 823 DteVehPwId_No_Actl 1;
BA_ "GenSigSendType" SG_ 823 DteVehPwId_No_Actl 3;
BA_ "U_CDX706_MY2023_Rx" SG_ 823 DteVehEId_No_Actl 1;
BA_ "U_U55X_MY2022_Rx" SG_ 823 DteVehEId_No_Actl 1;
BA_ "U_CD542_MY2021_Rx" SG_ 823 DteVehEId_No_Actl 1;
BA_ "ECGUsedRxSignal" SG_ 823 DteVehEId_No_Actl 1;
BA_ "U_CDX706_MY2023_Rx" SG_ 823 DteVehEffId_No_Actl 1;
BA_ "U_U55X_MY2022_Rx" SG_ 823 DteVehEffId_No_Actl 1;
BA_ "U_CD542_MY2021_Rx" SG_ 823 DteVehEffId_No_Actl 1;
BA_ "ECGUsedRxSignal" SG_ 823 DteVehEffId_No_Actl 1;
BA_ "U_CDX706_MY2023_Rx" SG_ 823 DteVeh_Pw_Actl 1;
BA_ "U_U55X_MY2022_Rx" SG_ 823 DteVeh_Pw_Actl 1;
BA_ "U_CD542_MY2021_Rx" SG_ 823 DteVeh_Pw_Actl 1;
BA_ "ECGUsedRxSignal" SG_ 823 DteVeh_Pw_Actl 1;
BA_ "U_CDX706_MY2023_Rx" SG_ 823 DteVeh_Eff_Actl 1;
BA_ "U_U55X_MY2022_Rx" SG_ 823 DteVeh_Eff_Actl 1;
BA_ "U_CD542_MY2021_Rx" SG_ 823 DteVeh_Eff_Actl 1;
BA_ "ECGUsedRxSignal" SG_ 823 DteVeh_Eff_Actl 1;
BA_ "GenSigStartValue" SG_ 823 DteVeh_Eff_Actl 100;
BA_ "U_CDX706_MY2023_Rx" SG_ 823 DteVeh_E_Actl 1;
BA_ "U_U55X_MY2022_Rx" SG_ 823 DteVeh_E_Actl 1;
BA_ "U_CD542_MY2021_Rx" SG_ 823 DteVeh_E_Actl 1;
BA_ "ECGUsedRxSignal" SG_ 823 DteVeh_E_Actl 1;
BA_ "U_CDX706_MY2023_Rx" SG_ 823 DteAcceptNew_B_Rq 1;
BA_ "U_U55X_MY2022_Rx" SG_ 823 DteAcceptNew_B_Rq 1;
BA_ "U_CD542_MY2021_Rx" SG_ 823 DteAcceptNew_B_Rq 1;
BA_ "ECGUsedRxSignal" SG_ 823 DteAcceptNew_B_Rq 1;
BA_ "GenSigSendType" SG_ 823 DteAcceptNew_B_Rq 3;
BA_ "U_CDX706_MY2023_Rx" SG_ 823 DteVehE_T_Actl 1;
BA_ "U_U55X_MY2022_Rx" SG_ 823 DteVehE_T_Actl 1;
BA_ "U_CD542_MY2021_Rx" SG_ 823 DteVehE_T_Actl 1;
BA_ "ECGUsedRxSignal" SG_ 823 DteVehE_T_Actl 1;
BA_ "U_U55X_MY2022_Rx" SG_ 777 ScLocSaved_B_Dsply 1;
BA_ "U_CD542_MY2021_Rx" SG_ 777 ScLocSaved_B_Dsply 1;
BA_ "ECGUsedRxSignal" SG_ 777 ScLocSaved_B_Dsply 1;
BA_ "GenSigSendType" SG_ 777 ScLocSaved_B_Dsply 3;
BA_ "U_U55X_MY2022_Rx" SG_ 777 ScLocLongPostv_B_Stat 1;
BA_ "U_CD542_MY2021_Rx" SG_ 777 ScLocLongPostv_B_Stat 1;
BA_ "ECGUsedRxSignal" SG_ 777 ScLocLongPostv_B_Stat 1;
BA_ "GenSigSendType" SG_ 777 ScLocLongPostv_B_Stat 3;
BA_ "U_U55X_MY2022_Rx" SG_ 777 ScLocLongFrct_An_Actl 1;
BA_ "U_CD542_MY2021_Rx" SG_ 777 ScLocLongFrct_An_Actl 1;
BA_ "ECGUsedRxSignal" SG_ 777 ScLocLongFrct_An_Actl 1;
BA_ "GenSigStartValue" SG_ 777 ScLocLongFrct_An_Actl 1048575;
BA_ "GenSigSendType" SG_ 777 ScLocLongFrct_An_Actl 3;
BA_ "U_U55X_MY2022_Rx" SG_ 777 ScLocLongDeg_An_Actl 1;
BA_ "U_CD542_MY2021_Rx" SG_ 777 ScLocLongDeg_An_Actl 1;
BA_ "ECGUsedRxSignal" SG_ 777 ScLocLongDeg_An_Actl 1;
BA_ "GenSigSendType" SG_ 777 ScLocLongDeg_An_Actl 3;
BA_ "U_U55X_MY2022_Rx" SG_ 777 ScLocLattPostv_B_Stat 1;
BA_ "U_CD542_MY2021_Rx" SG_ 777 ScLocLattPostv_B_Stat 1;
BA_ "ECGUsedRxSignal" SG_ 777 ScLocLattPostv_B_Stat 1;
BA_ "GenSigSendType" SG_ 777 ScLocLattPostv_B_Stat 3;
BA_ "U_U55X_MY2022_Rx" SG_ 777 ScLocLattFrct_An_Actl 1;
BA_ "U_CD542_MY2021_Rx" SG_ 777 ScLocLattFrct_An_Actl 1;
BA_ "ECGUsedRxSignal" SG_ 777 ScLocLattFrct_An_Actl 1;
BA_ "GenSigStartValue" SG_ 777 ScLocLattFrct_An_Actl 1048575;
BA_ "GenSigSendType" SG_ 777 ScLocLattFrct_An_Actl 3;
BA_ "U_U55X_MY2022_Rx" SG_ 777 ScLocLattDeg_An_Actl 1;
BA_ "U_CD542_MY2021_Rx" SG_ 777 ScLocLattDeg_An_Actl 1;
BA_ "ECGUsedRxSignal" SG_ 777 ScLocLattDeg_An_Actl 1;
BA_ "GenSigSendType" SG_ 777 ScLocLattDeg_An_Actl 3;
BA_ "U_U55X_MY2022_Rx" SG_ 777 ScLocId_No_Stat 1;
BA_ "U_CD542_MY2021_Rx" SG_ 777 ScLocId_No_Stat 1;
BA_ "ECGUsedRxSignal" SG_ 777 ScLocId_No_Stat 1;
BA_ "GenSigSendType" SG_ 777 ScLocId_No_Stat 3;
BA_ "U_U55X_MY2022_Rx" SG_ 771 ScLocSetId_No_Stat 1;
BA_ "U_CD542_MY2021_Rx" SG_ 771 ScLocSetId_No_Stat 1;
BA_ "ECGUsedRxSignal" SG_ 771 ScLocSetId_No_Stat 1;
BA_ "GenSigSendType" SG_ 771 ScLocSetId_No_Stat 3;
BA_ "U_U55X_MY2022_Rx" SG_ 771 ScLocRdius_L_Actl 1;
BA_ "U_CD542_MY2021_Rx" SG_ 771 ScLocRdius_L_Actl 1;
BA_ "ECGUsedRxSignal" SG_ 771 ScLocRdius_L_Actl 1;
BA_ "GenSigSendType" SG_ 771 ScLocRdius_L_Actl 3;
BA_ "U_U55X_MY2022_Rx" SG_ 771 ScDayOfWeekId_D_Stat 1;
BA_ "U_CD542_MY2021_Rx" SG_ 771 ScDayOfWeekId_D_Stat 1;
BA_ "ECGUsedRxSignal" SG_ 771 ScDayOfWeekId_D_Stat 1;
BA_ "GenSigStartValue" SG_ 771 ScDayOfWeekId_D_Stat 1;
BA_ "GenSigSendType" SG_ 771 ScDayOfWeekId_D_Stat 3;
BA_ "U_U55X_MY2022_Rx" SG_ 771 ScChrgToPc_Pc_Actl 1;
BA_ "U_CD542_MY2021_Rx" SG_ 771 ScChrgToPc_Pc_Actl 1;
BA_ "ECGUsedRxSignal" SG_ 771 ScChrgToPc_Pc_Actl 1;
BA_ "GenSigSendType" SG_ 771 ScChrgToPc_Pc_Actl 3;
BA_ "U_U55X_MY2022_Rx" SG_ 771 ScChrgPrfl_No_Actl 1;
BA_ "U_CD542_MY2021_Rx" SG_ 771 ScChrgPrfl_No_Actl 1;
BA_ "ECGUsedRxSignal" SG_ 771 ScChrgPrfl_No_Actl 1;
BA_ "GenSigSendType" SG_ 771 ScChrgPrfl_No_Actl 3;
BA_ "U_U55X_MY2022_Rx" SG_ 771 ScChrgDurSet_B_Stat 1;
BA_ "U_CD542_MY2021_Rx" SG_ 771 ScChrgDurSet_B_Stat 1;
BA_ "ECGUsedRxSignal" SG_ 771 ScChrgDurSet_B_Stat 1;
BA_ "GenSigSendType" SG_ 771 ScChrgDurSet_B_Stat 3;
BA_ "U_U55X_MY2022_Rx" SG_ 771 ScChrgDur_T_Actl 1;
BA_ "U_CD542_MY2021_Rx" SG_ 771 ScChrgDur_T_Actl 1;
BA_ "ECGUsedRxSignal" SG_ 771 ScChrgDur_T_Actl 1;
BA_ "GenSigSendType" SG_ 771 ScChrgDur_T_Actl 3;
BA_ "WakeupSignal" SG_ 513 ChrgStat_D3_Dsply 1;
BA_ "GenSigSendType" SG_ 513 ChrgStat_D3_Dsply 3;
BA_ "MetaData" SG_ 368 PrplBrkTqCtl_No_Cs 1;
BA_ "ContentDependant" SG_ 368 PrplBrkTqCtl_No_Cs 1;
BA_ "MetaData" SG_ 368 PrplBrkTqCtl_No_Cnt 1;
BA_ "ContentDependant" SG_ 368 PrplBrkTqCtl_No_Cnt 1;
BA_ "GenSigStartValue" SG_ 368 PrplWhlTot_Tq_RqFilt 65534;
BA_ "GenSigStartValue" SG_ 536 VehStab_D_Cnfm 14;
BA_ "MetaData" SG_ 536 BrkWhlFricTq_No_Cs 1;
BA_ "MetaData" SG_ 536 BrkWhlFricTq_No_Cnt 1;
BA_ "GenSigStartValue" SG_ 536 BrkWhlFricRr_Tq_Actl 254;
BA_ "GenSigStartValue" SG_ 536 BrkWhlFricRl_Tq_Actl 254;
BA_ "GenSigStartValue" SG_ 536 BrkWhlFricFr_Tq_Actl 254;
BA_ "GenSigStartValue" SG_ 536 BrkWhlFricFl_Tq_Actl 254;
BA_ "ContentDependant" SG_ 66 immoControlData_T2 1;
BA_ "U_P702_MY2021_Rx" SG_ 66 immoControlData_T2 1;
BA_ "ContentDependant" SG_ 66 immoControlCmd_T2 1;
BA_ "U_P702_MY2021_Rx" SG_ 66 immoControlCmd_T2 1;
BA_ "ECGUsedRxSignal" SG_ 770 ChrgTrgtSocOvrrd_B_Stat 1;
BA_ "GenSigSendType" SG_ 770 ChrgTrgtSocOvrrd_B_Stat 3;
BA_ "U_U55X_MY2022_Rx" SG_ 770 ScMnSoc_Pc_Actl 1;
BA_ "U_CD542_MY2021_Rx" SG_ 770 ScMnSoc_Pc_Actl 1;
BA_ "ECGUsedRxSignal" SG_ 770 ScMnSoc_Pc_Actl 1;
BA_ "GenSigStartValue" SG_ 770 ScMnSoc_Pc_Actl 100;
BA_ "GenSigSendType" SG_ 770 ScMnSoc_Pc_Actl 3;
BA_ "GenSigStartValue" SG_ 770 CurntTrgtSoc_Pc_Rq 100;
BA_ "GenSigSendType" SG_ 770 CurntTrgtSoc_Pc_Rq 3;
BA_ "U_U55X_MY2022_Rx" SG_ 770 FstChrgBulk_T_Est 1;
BA_ "U_CD542_MY2021_Rx" SG_ 770 FstChrgBulk_T_Est 1;
BA_ "ECGUsedRxSignal" SG_ 770 FstChrgBulk_T_Est 1;
BA_ "GenSigSendType" SG_ 770 FstChrgBulk_T_Est 3;
BA_ "U_U55X_MY2022_Rx" SG_ 770 CurntTrgtSoc_Pc_Dsply 1;
BA_ "U_CD542_MY2021_Rx" SG_ 770 CurntTrgtSoc_Pc_Dsply 1;
BA_ "ECGUsedRxSignal" SG_ 770 CurntTrgtSoc_Pc_Dsply 1;
BA_ "GenSigStartValue" SG_ 770 CurntTrgtSoc_Pc_Dsply 100;
BA_ "GenSigSendType" SG_ 770 CurntTrgtSoc_Pc_Dsply 3;
BA_ "U_U55X_MY2022_Rx" SG_ 770 ScPayloadUpdate_B_Stat 1;
BA_ "U_CD542_MY2021_Rx" SG_ 770 ScPayloadUpdate_B_Stat 1;
BA_ "ECGUsedRxSignal" SG_ 770 ScPayloadUpdate_B_Stat 1;
BA_ "GenSigSendType" SG_ 770 ScPayloadUpdate_B_Stat 3;
BA_ "U_U55X_MY2022_Rx" SG_ 770 ScLocPwId_No_Stat 1;
BA_ "U_CD542_MY2021_Rx" SG_ 770 ScLocPwId_No_Stat 1;
BA_ "ECGUsedRxSignal" SG_ 770 ScLocPwId_No_Stat 1;
BA_ "GenSigSendType" SG_ 770 ScLocPwId_No_Stat 3;
BA_ "U_U55X_MY2022_Rx" SG_ 770 ScChrgrPwMax_Pw_Actl 1;
BA_ "U_CD542_MY2021_Rx" SG_ 770 ScChrgrPwMax_Pw_Actl 1;
BA_ "ECGUsedRxSignal" SG_ 770 ScChrgrPwMax_Pw_Actl 1;
BA_ "U_U55X_MY2022_Rx" SG_ 770 ScLocIdCurnt_No_Stat 1;
BA_ "U_CD542_MY2021_Rx" SG_ 770 ScLocIdCurnt_No_Stat 1;
BA_ "ECGUsedRxSignal" SG_ 770 ScLocIdCurnt_No_Stat 1;
BA_ "GenSigSendType" SG_ 770 ScLocIdCurnt_No_Stat 3;
BA_ "U_U55X_MY2022_Rx" SG_ 770 ScEnbl_B_Stat 1;
BA_ "U_CD542_MY2021_Rx" SG_ 770 ScEnbl_B_Stat 1;
BA_ "ECGUsedRxSignal" SG_ 770 ScEnbl_B_Stat 1;
BA_ "GenSigSendType" SG_ 770 ScEnbl_B_Stat 3;
BA_ "GenSigStartValueInteger" SG_ 897 VehElAvgTrip2_Eff_Dsply 126;
BA_ "GenSigStartValue" SG_ 897 VehElAvgTrip2_Eff_Dsply 126;
BA_ "GenSigStartValueInteger" SG_ 897 Trip2SumDrvE_Pc_Dsply 1022;
BA_ "GenSigStartValue" SG_ 897 Trip2SumDrvE_Pc_Dsply 1022;
BA_ "GenSigStartValueInteger" SG_ 897 Trip2ExtFctrE_Pc_Dsply 1022;
BA_ "GenSigStartValue" SG_ 897 Trip2ExtFctrE_Pc_Dsply 1022;
BA_ "GenSigStartValueInteger" SG_ 897 Trip2ClimE_Pc_Dsply 1022;
BA_ "GenSigStartValue" SG_ 897 Trip2ClimE_Pc_Dsply 1022;
BA_ "GenSigStartValueInteger" SG_ 897 Trip2BattULoE_Pc_Dsply 1022;
BA_ "GenSigStartValue" SG_ 897 Trip2BattULoE_Pc_Dsply 1022;
BA_ "GenSigStartValueInteger" SG_ 896 VehElAvgTrip1_Eff_Dsply 126;
BA_ "GenSigStartValue" SG_ 896 VehElAvgTrip1_Eff_Dsply 126;
BA_ "GenSigStartValueInteger" SG_ 896 Trip1SumDrvE_Pc_Dsply 1022;
BA_ "GenSigStartValue" SG_ 896 Trip1SumDrvE_Pc_Dsply 1022;
BA_ "GenSigStartValueInteger" SG_ 896 Trip1ExtFctrE_Pc_Dsply 1022;
BA_ "GenSigStartValue" SG_ 896 Trip1ExtFctrE_Pc_Dsply 1022;
BA_ "GenSigStartValueInteger" SG_ 896 Trip1ClimE_Pc_Dsply 1022;
BA_ "GenSigStartValue" SG_ 896 Trip1ClimE_Pc_Dsply 1022;
BA_ "GenSigStartValueInteger" SG_ 896 Trip1BattULoE_Pc_Dsply 1022;
BA_ "GenSigStartValue" SG_ 896 Trip1BattULoE_Pc_Dsply 1022;
BA_ "GenSigStartValueInteger" SG_ 925 VehElEffTrip_No_Dsply 126;
BA_ "GenSigStartValue" SG_ 925 VehElEffTrip_No_Dsply 126;
BA_ "GenSigStartValueInteger" SG_ 925 TripSumDrvE_Pc_Dsply 1022;
BA_ "GenSigStartValue" SG_ 925 TripSumDrvE_Pc_Dsply 1022;
BA_ "ECGUsedRxSignal" SG_ 925 TripSumDrvE_Pc_Dsply 1;
BA_ "U_CD542_MY2021_Rx" SG_ 925 TripSumDrvE_Pc_Dsply 1;
BA_ "U_U55X_MY2022_Rx" SG_ 925 TripSumDrvE_Pc_Dsply 1;
BA_ "GenSigStartValueInteger" SG_ 925 TripExtFctrE_Pc_Dsply 1022;
BA_ "GenSigStartValue" SG_ 925 TripExtFctrE_Pc_Dsply 1022;
BA_ "ECGUsedRxSignal" SG_ 925 TripExtFctrE_Pc_Dsply 1;
BA_ "U_CD542_MY2021_Rx" SG_ 925 TripExtFctrE_Pc_Dsply 1;
BA_ "U_U55X_MY2022_Rx" SG_ 925 TripExtFctrE_Pc_Dsply 1;
BA_ "GenSigStartValueInteger" SG_ 925 TripClimE_Pc_Dsply 1022;
BA_ "GenSigStartValue" SG_ 925 TripClimE_Pc_Dsply 1022;
BA_ "ECGUsedRxSignal" SG_ 925 TripClimE_Pc_Dsply 1;
BA_ "U_CD542_MY2021_Rx" SG_ 925 TripClimE_Pc_Dsply 1;
BA_ "U_U55X_MY2022_Rx" SG_ 925 TripClimE_Pc_Dsply 1;
BA_ "GenSigStartValueInteger" SG_ 925 TripBattULoE_Pc_Dsply 1022;
BA_ "GenSigStartValue" SG_ 925 TripBattULoE_Pc_Dsply 1022;
BA_ "ECGUsedRxSignal" SG_ 925 TripBattULoE_Pc_Dsply 1;
BA_ "U_CD542_MY2021_Rx" SG_ 925 TripBattULoE_Pc_Dsply 1;
BA_ "U_U55X_MY2022_Rx" SG_ 925 TripBattULoE_Pc_Dsply 1;
BA_ "GenSigSendType" SG_ 785 VehPerfDemo_D_Stat 3;
BA_ "GenSigSendType" SG_ 785 VehVLimMsgTxt_B_Rq 3;
BA_ "GenSigSendType" SG_ 785 BattElecPerf_D2_Actl 3;
BA_ "GenSigSendType" SG_ 785 RgenAnimation_B_Dsply 3;
BA_ "GenSigSendType" SG_ 785 BattTracLimPerf_D_Dsply 3;
BA_ "GenSigSendType" SG_ 785 EcoIdl_D_Stat 3;
BA_ "GenSigStartValue" SG_ 785 DteVehOffst_L_Dsply 8190;
BA_ "GenSigSendType" SG_ 785 DteVehOffstMsgTxt_D_Rq 3;
BA_ "GenSigSendType" SG_ 785 PwPckTqRdyChime_B_Rq 3;
BA_ "GenSigSendType" SG_ 785 BattTracLoThres_D_Stat 3;
BA_ "ECGUsedRxSignal" SG_ 785 BattTracLoThres_D_Stat 1;
BA_ "U_CD542_MY2021_Rx" SG_ 785 BattTracLoThres_D_Stat 1;
BA_ "U_U55X_MY2022_Rx" SG_ 785 BattTracLoThres_D_Stat 1;
BA_ "GenSigSendType" SG_ 785 BattTracLoMsgTxt_D_Rq 3;
BA_ "GenSigSendType" SG_ 785 DestSocRqd_Pc_Dsply 3;
BA_ "ECGUsedRxSignal" SG_ 785 DestSocRqd_Pc_Dsply 1;
BA_ "U_CD542_MY2021_Rx" SG_ 785 DestSocRqd_Pc_Dsply 1;
BA_ "U_U55X_MY2022_Rx" SG_ 785 DestSocRqd_Pc_Dsply 1;
BA_ "GenSigSendType" SG_ 785 DestChrgEndMin_No_Actl 3;
BA_ "ECGUsedRxSignal" SG_ 785 DestChrgEndMin_No_Actl 1;
BA_ "U_CD542_MY2021_Rx" SG_ 785 DestChrgEndMin_No_Actl 1;
BA_ "U_U55X_MY2022_Rx" SG_ 785 DestChrgEndMin_No_Actl 1;
BA_ "GenSigSendType" SG_ 785 DestChrgEndHr_No_Actl 3;
BA_ "ECGUsedRxSignal" SG_ 785 DestChrgEndHr_No_Actl 1;
BA_ "U_CD542_MY2021_Rx" SG_ 785 DestChrgEndHr_No_Actl 1;
BA_ "U_U55X_MY2022_Rx" SG_ 785 DestChrgEndHr_No_Actl 1;
BA_ "GenSigSendType" SG_ 785 DestChrgEndDay_No_Actl 3;
BA_ "GenSigStartValue" SG_ 785 DestChrgEndDay_No_Actl 1;
BA_ "ECGUsedRxSignal" SG_ 785 DestChrgEndDay_No_Actl 1;
BA_ "U_CD542_MY2021_Rx" SG_ 785 DestChrgEndDay_No_Actl 1;
BA_ "U_U55X_MY2022_Rx" SG_ 785 DestChrgEndDay_No_Actl 1;
BA_ "GenSigSendType" SG_ 785 BattTracLoSoc_D_Dsply 3;
BA_ "ECGUsedRxSignal" SG_ 785 BattTracLoSoc_D_Dsply 1;
BA_ "U_CD542_MY2021_Rx" SG_ 785 BattTracLoSoc_D_Dsply 1;
BA_ "U_U55X_MY2022_Rx" SG_ 785 BattTracLoSoc_D_Dsply 1;
BA_ "U_T6_MCA_MY2020_Rx" SG_ 932 VehOnSrc2_D_Stat 1;
BA_ "ECGUsedRxSignal" SG_ 932 VehOnSrc2_D_Stat 1;
BA_ "U_CD542_MY2021_Rx" SG_ 932 VehOnSrc2_D_Stat 1;
BA_ "U_U55X_MY2022_Rx" SG_ 932 VehOnSrc2_D_Stat 1;
BA_ "U_CD764_MY2022_Rx" SG_ 932 VehOnSrc2_D_Stat 1;
BA_ "U_T6_MCA_MY2020_Tx" SG_ 932 VehOnSrc2_D_Stat 1;
BA_ "U_CD542_MY2021_Tx" SG_ 932 VehOnSrc2_D_Stat 1;
BA_ "U_U55X_MY2022_Tx" SG_ 932 VehOnSrc2_D_Stat 1;
BA_ "U_CD764_MY2022_Tx" SG_ 932 VehOnSrc2_D_Stat 1;
BA_ "GenSigStartValue" SG_ 627 VehToInfrstrctr_D_Stat 6;
BA_ "U_CD764_MY2022_Rx" SG_ 627 VehToInfrstrctr_D_Stat 1;
BA_ "U_CD764_MY2022_Rx" SG_ 627 RoadStopLineL_B_Avail 1;
BA_ "GenSigStartValue" SG_ 627 RoadStopLine_L_Est 65534;
BA_ "U_CD764_MY2022_Rx" SG_ 627 RoadStopLine_L_Est 1;
BA_ "U_CD764_MY2022_Rx" SG_ 627 RoadSignInfo1_D_Dsply 1;
BA_ "U_CD764_MY2022_Rx" SG_ 627 TrfcLghtWarnActv_B_Stat 1;
BA_ "U_CD764_MY2022_Rx" SG_ 627 TrfcLghtVActv_B_Stat 1;
BA_ "U_CD764_MY2022_Rx" SG_ 627 TrfcLghtDir_D_Stat 1;
BA_ "GenSigStartValue" SG_ 627 TrfcLghtDecel_A_Dsply 126;
BA_ "U_CD764_MY2022_Rx" SG_ 627 TrfcLghtDecel_A_Dsply 1;
BA_ "GenSigStartValue" SG_ 627 TrfcLght_V_Mx 254;
BA_ "U_CD764_MY2022_Rx" SG_ 627 TrfcLght_V_Mx 1;
BA_ "GenSigStartValue" SG_ 627 TrfcLght_V_Mn 254;
BA_ "U_CD764_MY2022_Rx" SG_ 627 TrfcLght_V_Mn 1;
BA_ "U_CD764_MY2022_Rx" SG_ 627 TrfcLght_D_Stat 1;
BA_ "GenSigStartValue" SG_ 630 TrfcLghtRight_T_Actl 254;
BA_ "U_CD764_MY2022_Rx" SG_ 630 TrfcLghtRight_T_Actl 1;
BA_ "U_CD764_MY2022_Rx" SG_ 630 TrfcLghtLeftType_D_Stat 1;
BA_ "U_CD764_MY2022_Rx" SG_ 630 TrfcLghtLeftOn_D_Stat 1;
BA_ "U_CD764_MY2022_Rx" SG_ 630 TrfcLghtLeftColr_D_Stat 1;
BA_ "GenSigStartValue" SG_ 630 TrfcLghtLeft_T_Actl 254;
BA_ "U_CD764_MY2022_Rx" SG_ 630 TrfcLghtLeft_T_Actl 1;
BA_ "U_CD764_MY2022_Rx" SG_ 630 TrfcLghtStrghtType_D_St 1;
BA_ "U_CD764_MY2022_Rx" SG_ 630 TrfcLghtStrghtOn_D_Stat 1;
BA_ "U_CD764_MY2022_Rx" SG_ 630 TrfcLghtStrghtColr_D_St 1;
BA_ "U_CD764_MY2022_Rx" SG_ 630 TrfcLghtStrght_T_Actl 1;
BA_ "U_CD764_MY2022_Rx" SG_ 630 TrfcLghtUturnType_D_St 1;
BA_ "U_CD764_MY2022_Rx" SG_ 630 TrfcLghtUturnOn_D_Stat 1;
BA_ "U_CD764_MY2022_Rx" SG_ 630 TrfcLghtUturnColr_D_St 1;
BA_ "U_CD764_MY2022_Rx" SG_ 630 TrfcLghtUturn_T_Actl 1;
BA_ "U_CD764_MY2022_Rx" SG_ 630 TrfcLghtRightType_D_St 1;
BA_ "U_CD764_MY2022_Rx" SG_ 630 TrfcLghtRightOn_D_Stat 1;
BA_ "U_CD764_MY2022_Rx" SG_ 630 TrfcLghtRightColr_D_St 1;
BA_ "GenSigSendType" SG_ 650 GridSrvcSbscrb01_D_Stat 3;
BA_ "ECGUsedTxSignal" SG_ 650 GridSrvcSbscrb01_D_Stat 1;
BA_ "GenSigSendType" SG_ 650 GridSrvc01_D_Rq 3;
BA_ "GenSigStartValue" SG_ 650 GridSrvc01_D_Rq 2;
BA_ "ECGUsedTxSignal" SG_ 650 GridSrvc01_D_Rq 1;
BA_ "GenSigSendType" SG_ 650 BptTglCnt_No_Rq 3;
BA_ "GenSigStartValue" SG_ 650 BptTglCnt_No_Rq 14;
BA_ "ECGUsedTxSignal" SG_ 650 BptTglCnt_No_Rq 1;
BA_ "GenSigSendType" SG_ 650 BptTgl_D_Rq 3;
BA_ "GenSigStartValue" SG_ 650 BptTgl_D_Rq 2;
BA_ "ECGUsedTxSignal" SG_ 650 BptTgl_D_Rq 1;
BA_ "GenSigSendType" SG_ 650 BptStrtStop_D_RqCld 3;
BA_ "ECGUsedTxSignal" SG_ 650 BptStrtStop_D_RqCld 1;
BA_ "GenSigSendType" SG_ 650 BptMnSoc_L_RqCld 3;
BA_ "GenSigStartValue" SG_ 650 BptMnSoc_L_RqCld 8190;
BA_ "ECGUsedTxSignal" SG_ 650 BptMnSoc_L_RqCld 1;
BA_ "GenSigSendType" SG_ 650 BptMde_D_RqCld 3;
BA_ "ECGUsedTxSignal" SG_ 650 BptMde_D_RqCld 1;
BA_ "GenSigSendType" SG_ 650 BptIsol_D_Stat 3;
BA_ "GenSigStartValueInteger" SG_ 650 BptIsol_D_Stat 6;
BA_ "GenSigStartValue" SG_ 650 BptIsol_D_Stat 6;
BA_ "ECGUsedTxSignal" SG_ 650 BptIsol_D_Stat 1;
BA_ "GenSigSendType" SG_ 650 BptDly_T_RqCld 3;
BA_ "GenSigStartValue" SG_ 650 BptDly_T_RqCld 62;
BA_ "ECGUsedTxSignal" SG_ 650 BptDly_T_RqCld 1;
BA_ "GenSigSendType" SG_ 650 BptComm_D_Stat 3;
BA_ "ECGUsedTxSignal" SG_ 650 BptComm_D_Stat 1;
BA_ "GenSigSendType" SG_ 650 Bpt_D_StatEvse 3;
BA_ "ECGUsedTxSignal" SG_ 650 Bpt_D_StatEvse 1;
BA_ "GenSigStartValue" SG_ 655 EvseChrgOutHi_U_ActlBpt 1022;
BA_ "ECGUsedTxSignal" SG_ 655 EvseChrgOutHi_U_ActlBpt 1;
BA_ "GenSigStartValue" SG_ 655 EvseChrgOutHi_I_ActlBpt 32766;
BA_ "ECGUsedTxSignal" SG_ 655 EvseChrgOutHi_I_ActlBpt 1;
BA_ "GenSigStartValue" SG_ 655 EvseDchrg_Pw_Mx 32766;
BA_ "ECGUsedTxSignal" SG_ 655 EvseDchrg_Pw_Mx 1;
BA_ "GenSigStartValue" SG_ 655 EvseDchrg_I_Mx 32766;
BA_ "ECGUsedTxSignal" SG_ 655 EvseDchrg_I_Mx 1;
BA_ "GenSigStartValue" SG_ 595 DrvIdMde_D_Rq 1;
BA_ "GenSigSendType" SG_ 2611034328 PARSEDPhysGWM_ECGtoLDCMB 3;
BA_ "ECGUsedTxSignal" SG_ 2611034328 PARSEDPhysGWM_ECGtoLDCMB 1;
BA_ "GenSigSendType" SG_ 2611035352 PARSEDPhysGWM_ECGtoLDCMA 3;
BA_ "ECGUsedTxSignal" SG_ 2611035352 PARSEDPhysGWM_ECGtoLDCMA 1;
BA_ "GenSigSendType" SG_ 2611175502 PARSEDPhysLDCMBtoGWM_ECG 3;
BA_ "ECGUsedRxSignal" SG_ 2611175502 PARSEDPhysLDCMBtoGWM_ECG 1;
BA_ "GenSigSendType" SG_ 2611175503 PARSEDPhysLDCMAtoGWM_ECG 3;
BA_ "ECGUsedRxSignal" SG_ 2611175503 PARSEDPhysLDCMAtoGWM_ECG 1;
BA_ "ECGUsedRxSignal" SG_ 2612224078 PARSEDPushLDCMBtoGWM_ECG 1;
BA_ "GenSigSendType" SG_ 2612224079 PARSEDPushLDCMAtoGWM_ECG 3;
BA_ "ECGUsedRxSignal" SG_ 2612224079 PARSEDPushLDCMAtoGWM_ECG 1;
BA_ "GenSigSendType" SG_ 2612082904 PARSEDPushFcGWM_ECGtoLDCMB 3;
BA_ "ECGUsedTxSignal" SG_ 2612082904 PARSEDPushFcGWM_ECGtoLDCMB 1;
BA_ "GenSigSendType" SG_ 2612083928 PARSEDPushFcGWM_ECGtoLDCMA 3;
BA_ "ECGUsedTxSignal" SG_ 2612083928 PARSEDPushFcGWM_ECGtoLDCMA 1;
BA_ "GenSigSendType" SG_ 2610126926 OTAPhysLDCMBtoGWM_ECG 3;
BA_ "ECGUsedRxSignal" SG_ 2610126926 OTAPhysLDCMBtoGWM_ECG 1;
BA_ "GenSigSendType" SG_ 2610126927 OTAPhysLDCMAtoGWM_ECG 3;
BA_ "ECGUsedRxSignal" SG_ 2610126927 OTAPhysLDCMAtoGWM_ECG 1;
BA_ "GenSigSendType" SG_ 2609985752 OTAPhysGWM_ECGtoLDCMB 3;
BA_ "ECGUsedTxSignal" SG_ 2609985752 OTAPhysGWM_ECGtoLDCMB 1;
BA_ "GenSigSendType" SG_ 2609986776 OTAPhysGWM_ECGtoLDCMA 3;
BA_ "ECGUsedTxSignal" SG_ 2609986776 OTAPhysGWM_ECGtoLDCMA 1;
BA_ "GenSigStartValue" SG_ 986 Trlr_M_Rq 2046;
BA_ "GenSigSendType" SG_ 1822 TesterPhysicalResGWM_F1 3;
BA_ "U_T6_MCA_MY2020_Tx" SG_ 1822 TesterPhysicalResGWM_F1 1;
BA_ "ECGUsedTxSignal" SG_ 1822 TesterPhysicalResGWM_F1 1;
BA_ "U_CD542_MY2021_Tx" SG_ 1822 TesterPhysicalResGWM_F1 1;
BA_ "U_U55X_MY2022_Tx" SG_ 1822 TesterPhysicalResGWM_F1 1;
BA_ "U_CD764_MY2022_Tx" SG_ 1822 TesterPhysicalResGWM_F1 1;
BA_ "GenSigStartValueInteger" SG_ 1438 GWM_GWOnBoardTester 255;
BA_ "ContentDependant" SG_ 1438 GWM_GWOnBoardTester 1;
BA_ "GenSigStartValue" SG_ 1438 GWM_GWOnBoardTester 255;
BA_ "U_P702_MY2021_Rx" SG_ 1438 GWM_GWOnBoardTester 1;
BA_ "U_T6_MCA_MY2020_Rx" SG_ 1438 GWM_GWOnBoardTester 1;
BA_ "U_CD542_MY2021_Rx" SG_ 1438 GWM_GWOnBoardTester 1;
BA_ "U_U55X_MY2022_Rx" SG_ 1438 GWM_GWOnBoardTester 1;
BA_ "U_CD764_MY2022_Rx" SG_ 1438 GWM_GWOnBoardTester 1;
BA_ "U_T6_MCA_MY2020_Tx" SG_ 1438 GWM_GWOnBoardTester 1;
BA_ "ECGUsedTxSignal" SG_ 1438 GWM_GWOnBoardTester 1;
BA_ "U_CD542_MY2021_Tx" SG_ 1438 GWM_GWOnBoardTester 1;
BA_ "U_U55X_MY2022_Tx" SG_ 1438 GWM_GWOnBoardTester 1;
BA_ "U_CD764_MY2022_Tx" SG_ 1438 GWM_GWOnBoardTester 1;
BA_ "GenSigStartValueInteger" SG_ 1438 GWM_GWNMProxy 255;
BA_ "ContentDependant" SG_ 1438 GWM_GWNMProxy 1;
BA_ "GenSigStartValue" SG_ 1438 GWM_GWNMProxy 255;
BA_ "U_P702_MY2021_Rx" SG_ 1438 GWM_GWNMProxy 1;
BA_ "U_T6_MCA_MY2020_Rx" SG_ 1438 GWM_GWNMProxy 1;
BA_ "U_CD542_MY2021_Rx" SG_ 1438 GWM_GWNMProxy 1;
BA_ "U_U55X_MY2022_Rx" SG_ 1438 GWM_GWNMProxy 1;
BA_ "U_CD764_MY2022_Rx" SG_ 1438 GWM_GWNMProxy 1;
BA_ "U_T6_MCA_MY2020_Tx" SG_ 1438 GWM_GWNMProxy 1;
BA_ "ECGUsedTxSignal" SG_ 1438 GWM_GWNMProxy 1;
BA_ "U_CD542_MY2021_Tx" SG_ 1438 GWM_GWNMProxy 1;
BA_ "U_U55X_MY2022_Tx" SG_ 1438 GWM_GWNMProxy 1;
BA_ "U_CD764_MY2022_Tx" SG_ 1438 GWM_GWNMProxy 1;
BA_ "GenSigStartValueInteger" SG_ 1438 GWM_AutoSarNMReserved4 255;
BA_ "ContentDependant" SG_ 1438 GWM_AutoSarNMReserved4 1;
BA_ "GenSigStartValue" SG_ 1438 GWM_AutoSarNMReserved4 255;
BA_ "U_P702_MY2021_Rx" SG_ 1438 GWM_AutoSarNMReserved4 1;
BA_ "U_T6_MCA_MY2020_Rx" SG_ 1438 GWM_AutoSarNMReserved4 1;
BA_ "U_CD542_MY2021_Rx" SG_ 1438 GWM_AutoSarNMReserved4 1;
BA_ "U_U55X_MY2022_Rx" SG_ 1438 GWM_AutoSarNMReserved4 1;
BA_ "U_CD764_MY2022_Rx" SG_ 1438 GWM_AutoSarNMReserved4 1;
BA_ "U_T6_MCA_MY2020_Tx" SG_ 1438 GWM_AutoSarNMReserved4 1;
BA_ "ECGUsedTxSignal" SG_ 1438 GWM_AutoSarNMReserved4 1;
BA_ "U_CD542_MY2021_Tx" SG_ 1438 GWM_AutoSarNMReserved4 1;
BA_ "U_U55X_MY2022_Tx" SG_ 1438 GWM_AutoSarNMReserved4 1;
BA_ "U_CD764_MY2022_Tx" SG_ 1438 GWM_AutoSarNMReserved4 1;
BA_ "GenSigStartValueInteger" SG_ 1438 GWM_AutoSarNMReserved3 255;
BA_ "ContentDependant" SG_ 1438 GWM_AutoSarNMReserved3 1;
BA_ "GenSigStartValue" SG_ 1438 GWM_AutoSarNMReserved3 255;
BA_ "U_P702_MY2021_Rx" SG_ 1438 GWM_AutoSarNMReserved3 1;
BA_ "U_T6_MCA_MY2020_Rx" SG_ 1438 GWM_AutoSarNMReserved3 1;
BA_ "U_CD542_MY2021_Rx" SG_ 1438 GWM_AutoSarNMReserved3 1;
BA_ "U_U55X_MY2022_Rx" SG_ 1438 GWM_AutoSarNMReserved3 1;
BA_ "U_CD764_MY2022_Rx" SG_ 1438 GWM_AutoSarNMReserved3 1;
BA_ "U_T6_MCA_MY2020_Tx" SG_ 1438 GWM_AutoSarNMReserved3 1;
BA_ "ECGUsedTxSignal" SG_ 1438 GWM_AutoSarNMReserved3 1;
BA_ "U_CD542_MY2021_Tx" SG_ 1438 GWM_AutoSarNMReserved3 1;
BA_ "U_U55X_MY2022_Tx" SG_ 1438 GWM_AutoSarNMReserved3 1;
BA_ "U_CD764_MY2022_Tx" SG_ 1438 GWM_AutoSarNMReserved3 1;
BA_ "GenSigStartValueInteger" SG_ 1438 GWM_AutoSarNMReserved2 255;
BA_ "ContentDependant" SG_ 1438 GWM_AutoSarNMReserved2 1;
BA_ "GenSigStartValue" SG_ 1438 GWM_AutoSarNMReserved2 255;
BA_ "U_P702_MY2021_Rx" SG_ 1438 GWM_AutoSarNMReserved2 1;
BA_ "U_T6_MCA_MY2020_Rx" SG_ 1438 GWM_AutoSarNMReserved2 1;
BA_ "U_CD542_MY2021_Rx" SG_ 1438 GWM_AutoSarNMReserved2 1;
BA_ "U_U55X_MY2022_Rx" SG_ 1438 GWM_AutoSarNMReserved2 1;
BA_ "U_CD764_MY2022_Rx" SG_ 1438 GWM_AutoSarNMReserved2 1;
BA_ "U_T6_MCA_MY2020_Tx" SG_ 1438 GWM_AutoSarNMReserved2 1;
BA_ "ECGUsedTxSignal" SG_ 1438 GWM_AutoSarNMReserved2 1;
BA_ "U_CD542_MY2021_Tx" SG_ 1438 GWM_AutoSarNMReserved2 1;
BA_ "U_U55X_MY2022_Tx" SG_ 1438 GWM_AutoSarNMReserved2 1;
BA_ "U_CD764_MY2022_Tx" SG_ 1438 GWM_AutoSarNMReserved2 1;
BA_ "GenSigStartValueInteger" SG_ 1438 GWM_AutoSarNMReserved1 255;
BA_ "ContentDependant" SG_ 1438 GWM_AutoSarNMReserved1 1;
BA_ "GenSigStartValue" SG_ 1438 GWM_AutoSarNMReserved1 255;
BA_ "U_P702_MY2021_Rx" SG_ 1438 GWM_AutoSarNMReserved1 1;
BA_ "U_T6_MCA_MY2020_Rx" SG_ 1438 GWM_AutoSarNMReserved1 1;
BA_ "U_CD542_MY2021_Rx" SG_ 1438 GWM_AutoSarNMReserved1 1;
BA_ "U_U55X_MY2022_Rx" SG_ 1438 GWM_AutoSarNMReserved1 1;
BA_ "U_CD764_MY2022_Rx" SG_ 1438 GWM_AutoSarNMReserved1 1;
BA_ "U_T6_MCA_MY2020_Tx" SG_ 1438 GWM_AutoSarNMReserved1 1;
BA_ "ECGUsedTxSignal" SG_ 1438 GWM_AutoSarNMReserved1 1;
BA_ "U_CD542_MY2021_Tx" SG_ 1438 GWM_AutoSarNMReserved1 1;
BA_ "U_U55X_MY2022_Tx" SG_ 1438 GWM_AutoSarNMReserved1 1;
BA_ "U_CD764_MY2022_Tx" SG_ 1438 GWM_AutoSarNMReserved1 1;
BA_ "GenSigStartValueInteger" SG_ 1438 GWM_AutoSarNMNodeId 158;
BA_ "ContentDependant" SG_ 1438 GWM_AutoSarNMNodeId 1;
BA_ "GenSigStartValue" SG_ 1438 GWM_AutoSarNMNodeId 158;
BA_ "U_P702_MY2021_Rx" SG_ 1438 GWM_AutoSarNMNodeId 1;
BA_ "U_T6_MCA_MY2020_Rx" SG_ 1438 GWM_AutoSarNMNodeId 1;
BA_ "U_CD542_MY2021_Rx" SG_ 1438 GWM_AutoSarNMNodeId 1;
BA_ "U_U55X_MY2022_Rx" SG_ 1438 GWM_AutoSarNMNodeId 1;
BA_ "U_CD764_MY2022_Rx" SG_ 1438 GWM_AutoSarNMNodeId 1;
BA_ "U_T6_MCA_MY2020_Tx" SG_ 1438 GWM_AutoSarNMNodeId 1;
BA_ "ECGUsedTxSignal" SG_ 1438 GWM_AutoSarNMNodeId 1;
BA_ "U_CD542_MY2021_Tx" SG_ 1438 GWM_AutoSarNMNodeId 1;
BA_ "U_U55X_MY2022_Tx" SG_ 1438 GWM_AutoSarNMNodeId 1;
BA_ "U_CD764_MY2022_Tx" SG_ 1438 GWM_AutoSarNMNodeId 1;
BA_ "ContentDependant" SG_ 1438 GWM_AutoSarNMControl 1;
BA_ "U_P702_MY2021_Rx" SG_ 1438 GWM_AutoSarNMControl 1;
BA_ "U_T6_MCA_MY2020_Rx" SG_ 1438 GWM_AutoSarNMControl 1;
BA_ "U_CD542_MY2021_Rx" SG_ 1438 GWM_AutoSarNMControl 1;
BA_ "U_U55X_MY2022_Rx" SG_ 1438 GWM_AutoSarNMControl 1;
BA_ "U_CD764_MY2022_Rx" SG_ 1438 GWM_AutoSarNMControl 1;
BA_ "U_T6_MCA_MY2020_Tx" SG_ 1438 GWM_AutoSarNMControl 1;
BA_ "ECGUsedTxSignal" SG_ 1438 GWM_AutoSarNMControl 1;
BA_ "U_CD542_MY2021_Tx" SG_ 1438 GWM_AutoSarNMControl 1;
BA_ "U_U55X_MY2022_Tx" SG_ 1438 GWM_AutoSarNMControl 1;
BA_ "U_CD764_MY2022_Tx" SG_ 1438 GWM_AutoSarNMControl 1;
BA_ "GenSigStartValueInteger" SG_ 1191 BattTracTe14_Te_Actl 254;
BA_ "GenSigStartValue" SG_ 1191 BattTracTe14_Te_Actl 254;
BA_ "GenSigStartValueInteger" SG_ 1191 BattTracTe19_Te_Actl 254;
BA_ "GenSigStartValue" SG_ 1191 BattTracTe19_Te_Actl 254;
BA_ "GenSigStartValueInteger" SG_ 1191 BattTracTe18_Te_Actl 254;
BA_ "GenSigStartValue" SG_ 1191 BattTracTe18_Te_Actl 254;
BA_ "GenSigStartValueInteger" SG_ 1191 BattTracTe17_Te_Actl 254;
BA_ "GenSigStartValue" SG_ 1191 BattTracTe17_Te_Actl 254;
BA_ "GenSigStartValueInteger" SG_ 1191 BattTracTe16_Te_Actl 254;
BA_ "GenSigStartValue" SG_ 1191 BattTracTe16_Te_Actl 254;
BA_ "GenSigStartValueInteger" SG_ 1191 BattTracTe15_Te_Actl 254;
BA_ "GenSigStartValue" SG_ 1191 BattTracTe15_Te_Actl 254;
BA_ "GenSigStartValueInteger" SG_ 1190 BattTracUMxArry_No_Actl 31;
BA_ "GenSigStartValue" SG_ 1190 BattTracUMxArry_No_Actl 31;
BA_ "GenSigStartValueInteger" SG_ 1190 BattTracCellUMx_No_Actl 254;
BA_ "GenSigStartValue" SG_ 1190 BattTracCellUMx_No_Actl 254;
BA_ "GenSigStartValueInteger" SG_ 1190 BattTracCellUMn_No_Actl 254;
BA_ "GenSigStartValue" SG_ 1190 BattTracCellUMn_No_Actl 254;
BA_ "GenSigStartValueInteger" SG_ 1190 BattTracCellCnt_No_Actl 254;
BA_ "GenSigStartValue" SG_ 1190 BattTracCellCnt_No_Actl 254;
BA_ "GenSigStartValueInteger" SG_ 1190 BattTracTeMx_No_Actl 254;
BA_ "GenSigStartValue" SG_ 1190 BattTracTeMx_No_Actl 254;
BA_ "GenSigStartValueInteger" SG_ 1190 BattTracTeMn_No_Actl 254;
BA_ "GenSigStartValue" SG_ 1190 BattTracTeMn_No_Actl 254;
BA_ "GenSigStartValueInteger" SG_ 1190 BattTracTeCnt_No_Actl 254;
BA_ "GenSigStartValue" SG_ 1190 BattTracTeCnt_No_Actl 254;
BA_ "GenSigStartValueInteger" SG_ 1192 BattTracCell95_U_Actl 4094;
BA_ "GenSigStartValue" SG_ 1192 BattTracCell95_U_Actl 4094;
BA_ "GenSigStartValueInteger" SG_ 1192 BattTracCell94_U_Actl 4094;
BA_ "GenSigStartValue" SG_ 1192 BattTracCell94_U_Actl 4094;
BA_ "GenSigStartValueInteger" SG_ 1192 BattTracCell93_U_Actl 4094;
BA_ "GenSigStartValue" SG_ 1192 BattTracCell93_U_Actl 4094;
BA_ "GenSigStartValueInteger" SG_ 1192 BattTracCell92_U_Actl 4094;
BA_ "GenSigStartValue" SG_ 1192 BattTracCell92_U_Actl 4094;
BA_ "GenSigStartValueInteger" SG_ 1192 BattTracCell91_U_Actl 4094;
BA_ "GenSigStartValue" SG_ 1192 BattTracCell91_U_Actl 4094;
BA_ "GenSigSendType" SG_ 1245 RearDiffLckLamp_D_Cstm 3;
BA_ "ECGUsedTxSignal" SG_ 1245 RearDiffLckLamp_D_Cstm 1;
BA_ "U_CD764_MY2022_Tx" SG_ 1245 RearDiffLckLamp_D_Cstm 1;
BA_ "GenSigSendType" SG_ 1245 FrontDiffLckLamp_D_Cstm 3;
BA_ "ECGUsedTxSignal" SG_ 1245 FrontDiffLckLamp_D_Cstm 1;
BA_ "U_CD764_MY2022_Tx" SG_ 1245 FrontDiffLckLamp_D_Cstm 1;
BA_ "GenSigSendType" SG_ 1245 AwdMdeCstm_D_RqDrv 3;
BA_ "GenSigStartValueInteger" SG_ 1245 AwdMdeCstm_D_RqDrv 5;
BA_ "ECGUsedTxSignal" SG_ 1245 AwdMdeCstm_D_RqDrv 1;
BA_ "U_CD764_MY2022_Tx" SG_ 1245 AwdMdeCstm_D_RqDrv 1;
BA_ "GenSigSendType" SG_ 1245 SelDrvMdeAwd2_D_Cstm 3;
BA_ "GenSigStartValueInteger" SG_ 1245 SelDrvMdeAwd2_D_Cstm 31;
BA_ "GenSigStartValue" SG_ 1245 SelDrvMdeAwd2_D_Cstm 31;
BA_ "ECGUsedTxSignal" SG_ 1245 SelDrvMdeAwd2_D_Cstm 1;
BA_ "U_CD764_MY2022_Tx" SG_ 1245 SelDrvMdeAwd2_D_Cstm 1;
BA_ "GenSigSendType" SG_ 1242 SelDrvMdeCstmPt_D_Rq 3;
BA_ "ECGUsedTxSignal" SG_ 1242 SelDrvMdeCstmPt_D_Rq 1;
BA_ "U_CD764_MY2022_Tx" SG_ 1242 SelDrvMdeCstmPt_D_Rq 1;
BA_ "GenSigSendType" SG_ 1242 EngExhMdeQuietCstm_D_Rq 3;
BA_ "ECGUsedTxSignal" SG_ 1242 EngExhMdeQuietCstm_D_Rq 1;
BA_ "U_CD764_MY2022_Tx" SG_ 1242 EngExhMdeQuietCstm_D_Rq 1;
BA_ "GenSigSendType" SG_ 1242 StopStrtCstm_D_Rq 3;
BA_ "ECGUsedTxSignal" SG_ 1242 StopStrtCstm_D_Rq 1;
BA_ "U_CD764_MY2022_Tx" SG_ 1242 StopStrtCstm_D_Rq 1;
BA_ "U_P702_MY2021_Rx" SG_ 1116 TrlrAidSetup_D2_Rq 1;
BA_ "U_T6_MCA_MY2020_Rx" SG_ 1116 TrlrAidSetup_D2_Rq 1;
BA_ "U_CD542_MY2021_Rx" SG_ 1116 TrlrAidSetup_D2_Rq 1;
BA_ "U_U55X_MY2022_Rx" SG_ 1116 TrlrAidSetup_D2_Rq 1;
BA_ "U_CD764_MY2022_Rx" SG_ 1116 TrlrAidSetup_D2_Rq 1;
BA_ "U_P702_MY2021_Rx" SG_ 1116 TrlrAidEnbl_D2_Rq 1;
BA_ "U_T6_MCA_MY2020_Rx" SG_ 1116 TrlrAidEnbl_D2_Rq 1;
BA_ "U_CD542_MY2021_Rx" SG_ 1116 TrlrAidEnbl_D2_Rq 1;
BA_ "U_U55X_MY2022_Rx" SG_ 1116 TrlrAidEnbl_D2_Rq 1;
BA_ "U_CD764_MY2022_Rx" SG_ 1116 TrlrAidEnbl_D2_Rq 1;
BA_ "U_T6_MCA_MY2020_Rx" SG_ 1116 TrlrTrgtToBmpr_L_Actl 1;
BA_ "U_CD542_MY2021_Rx" SG_ 1116 TrlrTrgtToBmpr_L_Actl 1;
BA_ "U_U55X_MY2022_Rx" SG_ 1116 TrlrTrgtToBmpr_L_Actl 1;
BA_ "U_CD764_MY2022_Rx" SG_ 1116 TrlrTrgtToBmpr_L_Actl 1;
BA_ "U_T6_MCA_MY2020_Rx" SG_ 1116 TrlrTrgtPtrnId_No_Mem 1;
BA_ "U_CD542_MY2021_Rx" SG_ 1116 TrlrTrgtPtrnId_No_Mem 1;
BA_ "U_U55X_MY2022_Rx" SG_ 1116 TrlrTrgtPtrnId_No_Mem 1;
BA_ "U_CD764_MY2022_Rx" SG_ 1116 TrlrTrgtPtrnId_No_Mem 1;
BA_ "U_T6_MCA_MY2020_Rx" SG_ 1116 TrlrRvrseCancl_B_Rq 1;
BA_ "U_CD542_MY2021_Rx" SG_ 1116 TrlrRvrseCancl_B_Rq 1;
BA_ "U_U55X_MY2022_Rx" SG_ 1116 TrlrRvrseCancl_B_Rq 1;
BA_ "U_CD764_MY2022_Rx" SG_ 1116 TrlrRvrseCancl_B_Rq 1;
BA_ "U_T6_MCA_MY2020_Rx" SG_ 1116 TrlrIdType_D_Stat 1;
BA_ "U_CD542_MY2021_Rx" SG_ 1116 TrlrIdType_D_Stat 1;
BA_ "U_U55X_MY2022_Rx" SG_ 1116 TrlrIdType_D_Stat 1;
BA_ "U_CD764_MY2022_Rx" SG_ 1116 TrlrIdType_D_Stat 1;
BA_ "U_T6_MCA_MY2020_Rx" SG_ 1116 TrlrId_No_Actl 1;
BA_ "U_CD542_MY2021_Rx" SG_ 1116 TrlrId_No_Actl 1;
BA_ "U_U55X_MY2022_Rx" SG_ 1116 TrlrId_No_Actl 1;
BA_ "U_CD764_MY2022_Rx" SG_ 1116 TrlrId_No_Actl 1;
BA_ "U_T6_MCA_MY2020_Rx" SG_ 1116 TrlrBallToBmpr_L_Actl 1;
BA_ "U_CD542_MY2021_Rx" SG_ 1116 TrlrBallToBmpr_L_Actl 1;
BA_ "U_U55X_MY2022_Rx" SG_ 1116 TrlrBallToBmpr_L_Actl 1;
BA_ "U_CD764_MY2022_Rx" SG_ 1116 TrlrBallToBmpr_L_Actl 1;
BA_ "U_T6_MCA_MY2020_Rx" SG_ 1116 TrlrAxleToBmpr_L_Actl 1;
BA_ "U_CD542_MY2021_Rx" SG_ 1116 TrlrAxleToBmpr_L_Actl 1;
BA_ "U_U55X_MY2022_Rx" SG_ 1116 TrlrAxleToBmpr_L_Actl 1;
BA_ "U_CD764_MY2022_Rx" SG_ 1116 TrlrAxleToBmpr_L_Actl 1;
BA_ "U_T6_MCA_MY2020_Rx" SG_ 1116 TrlrAnOffstDir_D_Mem 1;
BA_ "U_CD542_MY2021_Rx" SG_ 1116 TrlrAnOffstDir_D_Mem 1;
BA_ "U_U55X_MY2022_Rx" SG_ 1116 TrlrAnOffstDir_D_Mem 1;
BA_ "U_CD764_MY2022_Rx" SG_ 1116 TrlrAnOffstDir_D_Mem 1;
BA_ "U_T6_MCA_MY2020_Rx" SG_ 1116 TrlrAnOffst_An_Mem 1;
BA_ "U_CD542_MY2021_Rx" SG_ 1116 TrlrAnOffst_An_Mem 1;
BA_ "U_U55X_MY2022_Rx" SG_ 1116 TrlrAnOffst_An_Mem 1;
BA_ "U_CD764_MY2022_Rx" SG_ 1116 TrlrAnOffst_An_Mem 1;
BA_ "U_T6_MCA_MY2020_Rx" SG_ 1116 TrlrTrgtOffst_L_Actl 1;
BA_ "U_CD542_MY2021_Rx" SG_ 1116 TrlrTrgtOffst_L_Actl 1;
BA_ "U_U55X_MY2022_Rx" SG_ 1116 TrlrTrgtOffst_L_Actl 1;
BA_ "U_CD764_MY2022_Rx" SG_ 1116 TrlrTrgtOffst_L_Actl 1;
BA_ "GenSigSendType" SG_ 1844 TesterPhysicalReqHCM 3;
BA_ "U_CX727_MY2021_Rx" SG_ 1844 TesterPhysicalReqHCM 1;
BA_ "U_P702_MY2021_Rx" SG_ 1844 TesterPhysicalReqHCM 1;
BA_ "U_U55X_MY2022_Rx" SG_ 1844 TesterPhysicalReqHCM 1;
BA_ "U_CD764_MY2022_Rx" SG_ 1844 TesterPhysicalReqHCM 1;
BA_ "WakeupSignal" SG_ 954 ExtLghtFront_D_RqBody 1;
BA_ "GenSigStartValue" SG_ 954 ExtLghtFront_D_RqBody 1;
BA_ "WakeupSignal" SG_ 954 VehWlcmFrwlMde_D_Stat 1;
BA_ "U_T6_MCA_MY2020_Rx" SG_ 954 VehWlcmFrwlMde_D_Stat 1;
BA_ "U_U55X_MY2022_Rx" SG_ 954 VehWlcmFrwlMde_D_Stat 1;
BA_ "U_CD764_MY2022_Rx" SG_ 954 VehWlcmFrwlMde_D_Stat 1;
BA_ "U_CX727_MY2021_Rx" SG_ 954 GenericSwtch3_No_Actl 1;
BA_ "U_P702_MY2021_Rx" SG_ 954 GenericSwtch3_No_Actl 1;
BA_ "U_U55X_MY2022_Rx" SG_ 954 GenericSwtch3_No_Actl 1;
BA_ "U_CD764_MY2022_Rx" SG_ 954 GenericSwtch3_No_Actl 1;
BA_ "ContentDependant" SG_ 954 GenericSwtch2_No_Actl 1;
BA_ "U_CX727_MY2021_Rx" SG_ 954 GenericSwtch2_No_Actl 1;
BA_ "U_P702_MY2021_Rx" SG_ 954 GenericSwtch2_No_Actl 1;
BA_ "U_U55X_MY2022_Rx" SG_ 954 GenericSwtch2_No_Actl 1;
BA_ "U_CD764_MY2022_Rx" SG_ 954 GenericSwtch2_No_Actl 1;
BA_ "U_CX727_MY2021_Rx" SG_ 954 GenericSwtch1_No_Actl 1;
BA_ "U_P702_MY2021_Rx" SG_ 954 GenericSwtch1_No_Actl 1;
BA_ "U_U55X_MY2022_Rx" SG_ 954 GenericSwtch1_No_Actl 1;
BA_ "U_CD764_MY2022_Rx" SG_ 954 GenericSwtch1_No_Actl 1;
BA_ "U_CD764_MY2022_Rx" SG_ 954 PosLghtFl_D_Stat 1;
BA_ "U_CD764_MY2022_Rx" SG_ 954 PosLghtFr_D_Stat 1;
BA_ "WakeupSignal" SG_ 954 PudSptLghtRight_D_Rq 1;
BA_ "WakeupSignal" SG_ 954 PudSptLghtLeft_D_Rq 1;
BA_ "WakeupSignal" SG_ 954 ExtLghtRight_D_Stat 1;
BA_ "WakeupSignal" SG_ 954 ExtLghtRear_D_Stat 1;
BA_ "WakeupSignal" SG_ 954 ExtLghtLeft_D_Stat 1;
BA_ "WakeupSignal" SG_ 954 ExtLghtFront_D_Stat 1;
BA_ "WakeupSignal" SG_ 954 LghtAmbDrvMde_B_Stat 1;
BA_ "WakeupSignal" SG_ 954 PwRnngBoardPoll_D_Stat 1;
BA_ "WakeupSignal" SG_ 954 TrlrHitchLamp_D_Stat 1;
BA_ "WakeupSignal" SG_ 954 TrukBedLght_B_Stat 1;
BA_ "WakeupSignal" SG_ 954 VehWlcmFrwl_D_Stat 1;
BA_ "U_T6_MCA_MY2020_Rx" SG_ 954 VehWlcmFrwl_D_Stat 1;
BA_ "U_U55X_MY2022_Rx" SG_ 954 VehWlcmFrwl_D_Stat 1;
BA_ "U_CD764_MY2022_Rx" SG_ 954 VehWlcmFrwl_D_Stat 1;
BA_ "WakeupSignal" SG_ 954 ExtLghtAlrt_B_Rq 1;
BA_ "WakeupSignal" SG_ 954 ExtLght_D_Falt 1;
BA_ "GenSigSendType" SG_ 1852 TesterPhysicalResHCM 3;
BA_ "U_CX727_MY2021_Tx" SG_ 1852 TesterPhysicalResHCM 1;
BA_ "U_P702_MY2021_Tx" SG_ 1852 TesterPhysicalResHCM 1;
BA_ "U_U55X_MY2022_Tx" SG_ 1852 TesterPhysicalResHCM 1;
BA_ "U_CD764_MY2022_Tx" SG_ 1852 TesterPhysicalResHCM 1;
BA_ "GenSigSendType" SG_ 989 FeatNoHcm_No_Actl 3;
BA_ "U_CX727_MY2021_Tx" SG_ 989 FeatNoHcm_No_Actl 1;
BA_ "U_P702_MY2021_Tx" SG_ 989 FeatNoHcm_No_Actl 1;
BA_ "U_U55X_MY2022_Tx" SG_ 989 FeatNoHcm_No_Actl 1;
BA_ "U_CD764_MY2022_Tx" SG_ 989 FeatNoHcm_No_Actl 1;
BA_ "GenSigSendType" SG_ 989 FeatConfigHcmActl 3;
BA_ "U_CX727_MY2021_Tx" SG_ 989 FeatConfigHcmActl 1;
BA_ "U_P702_MY2021_Tx" SG_ 989 FeatConfigHcmActl 1;
BA_ "U_U55X_MY2022_Tx" SG_ 989 FeatConfigHcmActl 1;
BA_ "U_CD764_MY2022_Tx" SG_ 989 FeatConfigHcmActl 1;
BA_ "U_T6_MCA_MY2020_Rx" SG_ 874 AirCondCluOpen_D_Falt 1;
BA_ "U_CD764_MY2022_Rx" SG_ 874 AirCondCluOpen_D_Falt 1;
BA_ "U_T6_MCA_MY2020_Rx" SG_ 874 AirCondCluLife_D_Falt 1;
BA_ "U_CD764_MY2022_Rx" SG_ 874 AirCondCluLife_D_Falt 1;
BA_ "U_T6_MCA_MY2020_Rx" SG_ 874 AirCondCluGnd_D_Falt 1;
BA_ "U_CD764_MY2022_Rx" SG_ 874 AirCondCluGnd_D_Falt 1;
BA_ "U_T6_MCA_MY2020_Rx" SG_ 874 AirCondClu_D_Stat 1;
BA_ "U_CD764_MY2022_Rx" SG_ 874 AirCondClu_D_Stat 1;
BA_ "U_T6_MCA_MY2020_Rx" SG_ 874 AirCondCluBatt_D_Falt 1;
BA_ "U_CD764_MY2022_Rx" SG_ 874 AirCondCluBatt_D_Falt 1;
BA_ "U_CX727_MY2021_Rx" SG_ 874 BattTracShrtGrnd_D_Falt 1;
BA_ "U_P702_MY2021_Rx" SG_ 874 BattTracShrtGrnd_D_Falt 1;
BA_ "U_CD542_MY2021_Rx" SG_ 874 BattTracShrtGrnd_D_Falt 1;
BA_ "U_CX727_MY2021_Rx" SG_ 874 BattTracShrtBatt_D_Falt 1;
BA_ "U_P702_MY2021_Rx" SG_ 874 BattTracShrtBatt_D_Falt 1;
BA_ "U_CD542_MY2021_Rx" SG_ 874 BattTracShrtBatt_D_Falt 1;
BA_ "U_CX727_MY2021_Rx" SG_ 874 BattTracOpnCirct_D_Falt 1;
BA_ "U_P702_MY2021_Rx" SG_ 874 BattTracOpnCirct_D_Falt 1;
BA_ "U_CD542_MY2021_Rx" SG_ 874 BattTracOpnCirct_D_Falt 1;
BA_ "U_CX727_MY2021_Rx" SG_ 874 BattTracLifeLim_D_Falt 1;
BA_ "U_CD542_MY2021_Rx" SG_ 874 BattTracLifeLim_D_Falt 1;
BA_ "U_CX727_MY2021_Rx" SG_ 874 BattChlrShrtGrnd_D_Falt 1;
BA_ "U_P702_MY2021_Rx" SG_ 874 BattChlrShrtGrnd_D_Falt 1;
BA_ "U_CD542_MY2021_Rx" SG_ 874 BattChlrShrtGrnd_D_Falt 1;
BA_ "U_CX727_MY2021_Rx" SG_ 874 BattChlrShrtBatt_D_Falt 1;
BA_ "U_P702_MY2021_Rx" SG_ 874 BattChlrShrtBatt_D_Falt 1;
BA_ "U_CD542_MY2021_Rx" SG_ 874 BattChlrShrtBatt_D_Falt 1;
BA_ "U_CX727_MY2021_Rx" SG_ 874 BattChlrOpnCirct_D_Falt 1;
BA_ "U_P702_MY2021_Rx" SG_ 874 BattChlrOpnCirct_D_Falt 1;
BA_ "U_CD542_MY2021_Rx" SG_ 874 BattChlrOpnCirct_D_Falt 1;
BA_ "U_CD542_MY2021_Rx" SG_ 874 BattChlrLifeLim_D_Falt 1;
BA_ "U_CX727_MY2021_Rx" SG_ 874 BattTracLow_D_Falt 1;
BA_ "U_CD764_MY2022_Rx" SG_ 551 TjaLaneBiasEnbl_D_RqMnu 1;
BA_ "U_T6_MCA_MY2020_Rx" SG_ 551 Rba_D_Rq 1;
BA_ "U_CD542_MY2021_Rx" SG_ 551 Rba_D_Rq 1;
BA_ "U_U55X_MY2022_Rx" SG_ 551 Rba_D_Rq 1;
BA_ "U_CD764_MY2022_Rx" SG_ 551 Rba_D_Rq 1;
BA_ "WakeupSignal" SG_ 551 Em_D_Stat 1;
BA_ "GenSigStartValue" SG_ 551 ChrgToPcEdit_Pc_RqMnu 126;
BA_ "WakeupSignal" SG_ 551 Cntr_Plg_Mode_Cmd 1;
BA_ "GenSigStartValueInteger" SG_ 551 Btt_L_Actl2 126;
BA_ "GenSigStartValue" SG_ 551 Btt_L_Actl2 126;
BA_ "U_T6_MCA_MY2020_Rx" SG_ 551 Btt_L_Actl2 1;
BA_ "U_U55X_MY2022_Rx" SG_ 551 Btt_L_Actl2 1;
BA_ "U_CX727_MY2021_Rx" SG_ 132 GlblClkYr_No_Actl 1;
BA_ "U_P702_MY2021_Rx" SG_ 132 GlblClkYr_No_Actl 1;
BA_ "U_T6_MCA_MY2020_Rx" SG_ 132 GlblClkYr_No_Actl 1;
BA_ "U_CD542_MY2021_Rx" SG_ 132 GlblClkYr_No_Actl 1;
BA_ "U_U55X_MY2022_Rx" SG_ 132 GlblClkYr_No_Actl 1;
BA_ "U_CD764_MY2022_Rx" SG_ 132 GlblClkYr_No_Actl 1;
BA_ "U_CX727_MY2021_Rx" SG_ 132 GlblClkScnd_No_Actl 1;
BA_ "U_P702_MY2021_Rx" SG_ 132 GlblClkScnd_No_Actl 1;
BA_ "U_T6_MCA_MY2020_Rx" SG_ 132 GlblClkScnd_No_Actl 1;
BA_ "U_CD542_MY2021_Rx" SG_ 132 GlblClkScnd_No_Actl 1;
BA_ "U_U55X_MY2022_Rx" SG_ 132 GlblClkScnd_No_Actl 1;
BA_ "U_CD764_MY2022_Rx" SG_ 132 GlblClkScnd_No_Actl 1;
BA_ "U_CX727_MY2021_Rx" SG_ 132 GlblClkMnte_No_Actl 1;
BA_ "U_P702_MY2021_Rx" SG_ 132 GlblClkMnte_No_Actl 1;
BA_ "U_T6_MCA_MY2020_Rx" SG_ 132 GlblClkMnte_No_Actl 1;
BA_ "U_CD542_MY2021_Rx" SG_ 132 GlblClkMnte_No_Actl 1;
BA_ "U_U55X_MY2022_Rx" SG_ 132 GlblClkMnte_No_Actl 1;
BA_ "U_CD764_MY2022_Rx" SG_ 132 GlblClkMnte_No_Actl 1;
BA_ "U_CX727_MY2021_Rx" SG_ 132 GlblClkHr_No_Actl 1;
BA_ "U_P702_MY2021_Rx" SG_ 132 GlblClkHr_No_Actl 1;
BA_ "U_T6_MCA_MY2020_Rx" SG_ 132 GlblClkHr_No_Actl 1;
BA_ "U_CD542_MY2021_Rx" SG_ 132 GlblClkHr_No_Actl 1;
BA_ "U_U55X_MY2022_Rx" SG_ 132 GlblClkHr_No_Actl 1;
BA_ "U_CD764_MY2022_Rx" SG_ 132 GlblClkHr_No_Actl 1;
BA_ "U_CX727_MY2021_Rx" SG_ 132 GlblClkDay_No_Actl 1;
BA_ "U_P702_MY2021_Rx" SG_ 132 GlblClkDay_No_Actl 1;
BA_ "U_T6_MCA_MY2020_Rx" SG_ 132 GlblClkDay_No_Actl 1;
BA_ "U_CD542_MY2021_Rx" SG_ 132 GlblClkDay_No_Actl 1;
BA_ "U_U55X_MY2022_Rx" SG_ 132 GlblClkDay_No_Actl 1;
BA_ "U_CD764_MY2022_Rx" SG_ 132 GlblClkDay_No_Actl 1;
BA_ "GenSigSendType" SG_ 1006 PersIndexIpmb_D_Actl 3;
BA_ "GenSigStartValueInteger" SG_ 1006 PersIndexIpmb_D_Actl 4;
BA_ "GenSigStartValue" SG_ 1006 PersIndexIpmb_D_Actl 4;
BA_ "U_T6_MCA_MY2020_Tx" SG_ 1006 PersIndexIpmb_D_Actl 1;
BA_ "U_CD542_MY2021_Tx" SG_ 1006 PersIndexIpmb_D_Actl 1;
BA_ "U_U55X_MY2022_Tx" SG_ 1006 PersIndexIpmb_D_Actl 1;
BA_ "U_CD764_MY2022_Tx" SG_ 1006 PersIndexIpmb_D_Actl 1;
BA_ "GenSigSendType" SG_ 1006 FeatNoIpmbActl 3;
BA_ "U_T6_MCA_MY2020_Tx" SG_ 1006 FeatNoIpmbActl 1;
BA_ "U_CD542_MY2021_Tx" SG_ 1006 FeatNoIpmbActl 1;
BA_ "U_U55X_MY2022_Tx" SG_ 1006 FeatNoIpmbActl 1;
BA_ "U_CD764_MY2022_Tx" SG_ 1006 FeatNoIpmbActl 1;
BA_ "GenSigSendType" SG_ 1006 FeatConfigIpmbActl 3;
BA_ "U_T6_MCA_MY2020_Tx" SG_ 1006 FeatConfigIpmbActl 1;
BA_ "U_CD542_MY2021_Tx" SG_ 1006 FeatConfigIpmbActl 1;
BA_ "U_U55X_MY2022_Tx" SG_ 1006 FeatConfigIpmbActl 1;
BA_ "U_CD764_MY2022_Tx" SG_ 1006 FeatConfigIpmbActl 1;
BA_ "U_T6_MCA_MY2020_Rx" SG_ 1123 GpsUtcYr_No_Actl 1;
BA_ "U_CD542_MY2021_Rx" SG_ 1123 GpsUtcYr_No_Actl 1;
BA_ "U_CD764_MY2022_Rx" SG_ 1123 GpsUtcYr_No_Actl 1;
BA_ "GenSigStartValueInteger" SG_ 1123 GpsUtcMnth_No_Actl 1;
BA_ "GenSigStartValue" SG_ 1123 GpsUtcMnth_No_Actl 1;
BA_ "U_T6_MCA_MY2020_Rx" SG_ 1123 GpsUtcMnth_No_Actl 1;
BA_ "U_CD542_MY2021_Rx" SG_ 1123 GpsUtcMnth_No_Actl 1;
BA_ "U_CD764_MY2022_Rx" SG_ 1123 GpsUtcMnth_No_Actl 1;
BA_ "GenSigStartValueInteger" SG_ 1123 GpsUtcDay_No_Actl 1;
BA_ "GenSigStartValue" SG_ 1123 GpsUtcDay_No_Actl 1;
BA_ "U_T6_MCA_MY2020_Rx" SG_ 1123 GpsUtcDay_No_Actl 1;
BA_ "U_CD542_MY2021_Rx" SG_ 1123 GpsUtcDay_No_Actl 1;
BA_ "U_CD764_MY2022_Rx" SG_ 1123 GpsUtcDay_No_Actl 1;
BA_ "U_CX727_MY2021_Rx" SG_ 1123 GPS_UTC_seconds 1;
BA_ "U_P702_MY2021_Rx" SG_ 1123 GPS_UTC_seconds 1;
BA_ "U_T6_MCA_MY2020_Rx" SG_ 1123 GPS_UTC_seconds 1;
BA_ "U_CD542_MY2021_Rx" SG_ 1123 GPS_UTC_seconds 1;
BA_ "U_CD764_MY2022_Rx" SG_ 1123 GPS_UTC_seconds 1;
BA_ "U_T6_MCA_MY2020_Rx" SG_ 1123 GPS_UTC_minutes 1;
BA_ "U_CD542_MY2021_Rx" SG_ 1123 GPS_UTC_minutes 1;
BA_ "U_CD764_MY2022_Rx" SG_ 1123 GPS_UTC_minutes 1;
BA_ "U_T6_MCA_MY2020_Rx" SG_ 1123 GPS_UTC_hours 1;
BA_ "U_CD542_MY2021_Rx" SG_ 1123 GPS_UTC_hours 1;
BA_ "U_CD764_MY2022_Rx" SG_ 1123 GPS_UTC_hours 1;
BA_ "U_T6_MCA_MY2020_Rx" SG_ 1123 GPS_Compass_direction 1;
BA_ "U_CD542_MY2021_Rx" SG_ 1123 GPS_Compass_direction 1;
BA_ "U_CD764_MY2022_Rx" SG_ 1123 GPS_Compass_direction 1;
BA_ "U_CX727_MY2021_Rx" SG_ 1123 GPS_Actual_vs_Infer_pos 1;
BA_ "U_P702_MY2021_Rx" SG_ 1123 GPS_Actual_vs_Infer_pos 1;
BA_ "U_T6_MCA_MY2020_Rx" SG_ 1123 GPS_Actual_vs_Infer_pos 1;
BA_ "U_CD542_MY2021_Rx" SG_ 1123 GPS_Actual_vs_Infer_pos 1;
BA_ "U_CD764_MY2022_Rx" SG_ 1123 GPS_Actual_vs_Infer_pos 1;
BA_ "U_CX727_MY2021_Rx" SG_ 1123 Gps_B_Falt 1;
BA_ "U_P702_MY2021_Rx" SG_ 1123 Gps_B_Falt 1;
BA_ "U_T6_MCA_MY2020_Rx" SG_ 1123 Gps_B_Falt 1;
BA_ "U_CD542_MY2021_Rx" SG_ 1123 Gps_B_Falt 1;
BA_ "U_CD764_MY2022_Rx" SG_ 1123 Gps_B_Falt 1;
BA_ "U_T6_MCA_MY2020_Rx" SG_ 1123 GPS_Pdop 1;
BA_ "U_CX727_MY2021_Rx" SG_ 1122 GPS_Longitude_Minutes 1;
BA_ "U_P702_MY2021_Rx" SG_ 1122 GPS_Longitude_Minutes 1;
BA_ "U_T6_MCA_MY2020_Rx" SG_ 1122 GPS_Longitude_Minutes 1;
BA_ "U_CD542_MY2021_Rx" SG_ 1122 GPS_Longitude_Minutes 1;
BA_ "U_CD764_MY2022_Rx" SG_ 1122 GPS_Longitude_Minutes 1;
BA_ "U_CX727_MY2021_Rx" SG_ 1122 GPS_Longitude_Min_dec 1;
BA_ "U_P702_MY2021_Rx" SG_ 1122 GPS_Longitude_Min_dec 1;
BA_ "U_T6_MCA_MY2020_Rx" SG_ 1122 GPS_Longitude_Min_dec 1;
BA_ "U_CD542_MY2021_Rx" SG_ 1122 GPS_Longitude_Min_dec 1;
BA_ "U_CD764_MY2022_Rx" SG_ 1122 GPS_Longitude_Min_dec 1;
BA_ "GenSigStartValueInteger" SG_ 1122 GPS_Longitude_Degrees 179;
BA_ "U_CX727_MY2021_Rx" SG_ 1122 GPS_Longitude_Degrees 1;
BA_ "U_P702_MY2021_Rx" SG_ 1122 GPS_Longitude_Degrees 1;
BA_ "U_T6_MCA_MY2020_Rx" SG_ 1122 GPS_Longitude_Degrees 1;
BA_ "U_CD542_MY2021_Rx" SG_ 1122 GPS_Longitude_Degrees 1;
BA_ "U_CD764_MY2022_Rx" SG_ 1122 GPS_Longitude_Degrees 1;
BA_ "U_CX727_MY2021_Rx" SG_ 1122 GPS_Latitude_Minutes 1;
BA_ "U_P702_MY2021_Rx" SG_ 1122 GPS_Latitude_Minutes 1;
BA_ "U_T6_MCA_MY2020_Rx" SG_ 1122 GPS_Latitude_Minutes 1;
BA_ "U_CD542_MY2021_Rx" SG_ 1122 GPS_Latitude_Minutes 1;
BA_ "U_CD764_MY2022_Rx" SG_ 1122 GPS_Latitude_Minutes 1;
BA_ "U_CX727_MY2021_Rx" SG_ 1122 GPS_Latitude_Min_dec 1;
BA_ "U_P702_MY2021_Rx" SG_ 1122 GPS_Latitude_Min_dec 1;
BA_ "U_T6_MCA_MY2020_Rx" SG_ 1122 GPS_Latitude_Min_dec 1;
BA_ "U_CD542_MY2021_Rx" SG_ 1122 GPS_Latitude_Min_dec 1;
BA_ "U_CD764_MY2022_Rx" SG_ 1122 GPS_Latitude_Min_dec 1;
BA_ "U_CX727_MY2021_Rx" SG_ 1122 GPS_Latitude_Degrees 1;
BA_ "U_P702_MY2021_Rx" SG_ 1122 GPS_Latitude_Degrees 1;
BA_ "U_T6_MCA_MY2020_Rx" SG_ 1122 GPS_Latitude_Degrees 1;
BA_ "U_CD542_MY2021_Rx" SG_ 1122 GPS_Latitude_Degrees 1;
BA_ "U_CD764_MY2022_Rx" SG_ 1122 GPS_Latitude_Degrees 1;
BA_ "U_CX727_MY2021_Rx" SG_ 1122 GpsHsphLongEast_D_Actl 1;
BA_ "U_P702_MY2021_Rx" SG_ 1122 GpsHsphLongEast_D_Actl 1;
BA_ "U_T6_MCA_MY2020_Rx" SG_ 1122 GpsHsphLongEast_D_Actl 1;
BA_ "U_CD542_MY2021_Rx" SG_ 1122 GpsHsphLongEast_D_Actl 1;
BA_ "U_CD764_MY2022_Rx" SG_ 1122 GpsHsphLongEast_D_Actl 1;
BA_ "U_CX727_MY2021_Rx" SG_ 1122 GpsHsphLattSth_D_Actl 1;
BA_ "U_P702_MY2021_Rx" SG_ 1122 GpsHsphLattSth_D_Actl 1;
BA_ "U_T6_MCA_MY2020_Rx" SG_ 1122 GpsHsphLattSth_D_Actl 1;
BA_ "U_CD542_MY2021_Rx" SG_ 1122 GpsHsphLattSth_D_Actl 1;
BA_ "U_CD764_MY2022_Rx" SG_ 1122 GpsHsphLattSth_D_Actl 1;
BA_ "U_CX727_MY2021_Rx" SG_ 1003 VehKeyActv_D_Stat 1;
BA_ "U_CD542_MY2021_Rx" SG_ 1003 VehKeyActv_D_Stat 1;
BA_ "GenSigStartValueInteger" SG_ 1003 PersNoPos_D_Actl 4;
BA_ "GenSigStartValue" SG_ 1003 PersNoPos_D_Actl 4;
BA_ "U_CX727_MY2021_Rx" SG_ 1003 PersSetupRestr_D_Actl 1;
BA_ "U_CD542_MY2021_Rx" SG_ 1003 PersSetupRestr_D_Actl 1;
BA_ "U_CX727_MY2021_Rx" SG_ 1003 PersSetupAccessCtrl 1;
BA_ "U_CD542_MY2021_Rx" SG_ 1003 PersSetupAccessCtrl 1;
BA_ "U_CX727_MY2021_Rx" SG_ 1003 PersSetup_No_Actl 1;
BA_ "U_CD542_MY2021_Rx" SG_ 1003 PersSetup_No_Actl 1;
BA_ "GenSigStartValueInteger" SG_ 1003 PersConflict_D_Actl 1;
BA_ "GenSigStartValue" SG_ 1003 PersConflict_D_Actl 1;
BA_ "MetaData" SG_ 1003 RecallEvent_No_Cnt 1;
BA_ "U_T6_MCA_MY2020_Rx" SG_ 1003 RecallEvent_No_Cnt 1;
BA_ "U_CD542_MY2021_Rx" SG_ 1003 RecallEvent_No_Cnt 1;
BA_ "U_U55X_MY2022_Rx" SG_ 1003 RecallEvent_No_Cnt 1;
BA_ "U_CD764_MY2022_Rx" SG_ 1003 RecallEvent_No_Cnt 1;
BA_ "GenSigStartValueInteger" SG_ 1003 PersNo_D_Actl 4;
BA_ "GenSigStartValue" SG_ 1003 PersNo_D_Actl 4;
BA_ "U_CX727_MY2021_Rx" SG_ 1003 PersNo_D_Actl 1;
BA_ "U_T6_MCA_MY2020_Rx" SG_ 1003 PersNo_D_Actl 1;
BA_ "U_CD542_MY2021_Rx" SG_ 1003 PersNo_D_Actl 1;
BA_ "U_U55X_MY2022_Rx" SG_ 1003 PersNo_D_Actl 1;
BA_ "U_CD764_MY2022_Rx" SG_ 1003 PersNo_D_Actl 1;
BA_ "WakeupSignal" SG_ 994 Pers4OptIn_B_Stats 1;
BA_ "WakeupSignal" SG_ 994 Pers3OptIn_B_Stats 1;
BA_ "WakeupSignal" SG_ 994 Pers2OptIn_B_Stats 1;
BA_ "WakeupSignal" SG_ 994 Pers1OptIn_B_Stats 1;
BA_ "GenSigStartValueInteger" SG_ 994 CtrStkPersIndex_D_Actl 4;
BA_ "GenSigStartValue" SG_ 994 CtrStkPersIndex_D_Actl 4;
BA_ "U_CX727_MY2021_Rx" SG_ 994 CtrStkPersIndex_D_Actl 1;
BA_ "U_T6_MCA_MY2020_Rx" SG_ 994 CtrStkPersIndex_D_Actl 1;
BA_ "U_CD542_MY2021_Rx" SG_ 994 CtrStkPersIndex_D_Actl 1;
BA_ "U_U55X_MY2022_Rx" SG_ 994 CtrStkPersIndex_D_Actl 1;
BA_ "U_CD764_MY2022_Rx" SG_ 994 CtrStkPersIndex_D_Actl 1;
BA_ "U_CX727_MY2021_Rx" SG_ 994 CtrStkFeatNoActl 1;
BA_ "U_T6_MCA_MY2020_Rx" SG_ 994 CtrStkFeatNoActl 1;
BA_ "U_CD542_MY2021_Rx" SG_ 994 CtrStkFeatNoActl 1;
BA_ "U_U55X_MY2022_Rx" SG_ 994 CtrStkFeatNoActl 1;
BA_ "U_CD764_MY2022_Rx" SG_ 994 CtrStkFeatNoActl 1;
BA_ "U_CX727_MY2021_Rx" SG_ 994 CtrStkFeatConfigActl 1;
BA_ "U_T6_MCA_MY2020_Rx" SG_ 994 CtrStkFeatConfigActl 1;
BA_ "U_CD542_MY2021_Rx" SG_ 994 CtrStkFeatConfigActl 1;
BA_ "U_U55X_MY2022_Rx" SG_ 994 CtrStkFeatConfigActl 1;
BA_ "U_CD764_MY2022_Rx" SG_ 994 CtrStkFeatConfigActl 1;
BA_ "U_CX727_MY2021_Rx" SG_ 994 CtrStkDsplyOp_D_Rq 1;
BA_ "U_T6_MCA_MY2020_Rx" SG_ 994 CtrStkDsplyOp_D_Rq 1;
BA_ "U_CD542_MY2021_Rx" SG_ 994 CtrStkDsplyOp_D_Rq 1;
BA_ "U_U55X_MY2022_Rx" SG_ 994 CtrStkDsplyOp_D_Rq 1;
BA_ "U_CD764_MY2022_Rx" SG_ 994 CtrStkDsplyOp_D_Rq 1;
BA_ "GenSigStartValueInteger" SG_ 992 MsgCntrPersIndex_D_Rq 4;
BA_ "GenSigStartValue" SG_ 992 MsgCntrPersIndex_D_Rq 4;
BA_ "U_CX727_MY2021_Rx" SG_ 992 MsgCntrPersIndex_D_Rq 1;
BA_ "U_P702_MY2021_Rx" SG_ 992 MsgCntrPersIndex_D_Rq 1;
BA_ "U_T6_MCA_MY2020_Rx" SG_ 992 MsgCntrPersIndex_D_Rq 1;
BA_ "U_CD542_MY2021_Rx" SG_ 992 MsgCntrPersIndex_D_Rq 1;
BA_ "U_U55X_MY2022_Rx" SG_ 992 MsgCntrPersIndex_D_Rq 1;
BA_ "U_CD764_MY2022_Rx" SG_ 992 MsgCntrPersIndex_D_Rq 1;
BA_ "U_CX727_MY2021_Rx" SG_ 992 MsgCntrFeatConfigRq 1;
BA_ "U_P702_MY2021_Rx" SG_ 992 MsgCntrFeatConfigRq 1;
BA_ "U_T6_MCA_MY2020_Rx" SG_ 992 MsgCntrFeatConfigRq 1;
BA_ "U_CD542_MY2021_Rx" SG_ 992 MsgCntrFeatConfigRq 1;
BA_ "U_U55X_MY2022_Rx" SG_ 992 MsgCntrFeatConfigRq 1;
BA_ "U_CD764_MY2022_Rx" SG_ 992 MsgCntrFeatConfigRq 1;
BA_ "U_CX727_MY2021_Rx" SG_ 992 MsgCntrFeatNoRq 1;
BA_ "U_P702_MY2021_Rx" SG_ 992 MsgCntrFeatNoRq 1;
BA_ "U_T6_MCA_MY2020_Rx" SG_ 992 MsgCntrFeatNoRq 1;
BA_ "U_CD542_MY2021_Rx" SG_ 992 MsgCntrFeatNoRq 1;
BA_ "U_U55X_MY2022_Rx" SG_ 992 MsgCntrFeatNoRq 1;
BA_ "U_CD764_MY2022_Rx" SG_ 992 MsgCntrFeatNoRq 1;
BA_ "U_CX727_MY2021_Rx" SG_ 992 MsgCntrDsplyOp_D_Rq 1;
BA_ "U_P702_MY2021_Rx" SG_ 992 MsgCntrDsplyOp_D_Rq 1;
BA_ "U_T6_MCA_MY2020_Rx" SG_ 992 MsgCntrDsplyOp_D_Rq 1;
BA_ "U_CD542_MY2021_Rx" SG_ 992 MsgCntrDsplyOp_D_Rq 1;
BA_ "U_U55X_MY2022_Rx" SG_ 992 MsgCntrDsplyOp_D_Rq 1;
BA_ "U_CD764_MY2022_Rx" SG_ 992 MsgCntrDsplyOp_D_Rq 1;
BA_ "GenSigSendType" SG_ 820 AhbStatGfhbFdbk_D_Actl 3;
BA_ "U_T6_MCA_MY2020_Rx" SG_ 820 AhbStatGfhbFdbk_D_Actl 1;
BA_ "U_CD542_MY2021_Rx" SG_ 820 AhbStatGfhbFdbk_D_Actl 1;
BA_ "U_U55X_MY2022_Rx" SG_ 820 AhbStatGfhbFdbk_D_Actl 1;
BA_ "U_CD764_MY2022_Rx" SG_ 820 AhbStatGfhbFdbk_D_Actl 1;
BA_ "U_CX727_MY2021_Tx" SG_ 820 AhbStatGfhbFdbk_D_Actl 1;
BA_ "U_P702_MY2021_Tx" SG_ 820 AhbStatGfhbFdbk_D_Actl 1;
BA_ "U_U55X_MY2022_Tx" SG_ 820 AhbStatGfhbFdbk_D_Actl 1;
BA_ "U_CD764_MY2022_Tx" SG_ 820 AhbStatGfhbFdbk_D_Actl 1;
BA_ "GenSigSendType" SG_ 820 HeadLghtDrvSide_B_Stat 3;
BA_ "U_T6_MCA_MY2020_Rx" SG_ 820 HeadLghtDrvSide_B_Stat 1;
BA_ "U_CD542_MY2021_Rx" SG_ 820 HeadLghtDrvSide_B_Stat 1;
BA_ "U_U55X_MY2022_Rx" SG_ 820 HeadLghtDrvSide_B_Stat 1;
BA_ "U_CD764_MY2022_Rx" SG_ 820 HeadLghtDrvSide_B_Stat 1;
BA_ "U_CX727_MY2021_Tx" SG_ 820 HeadLghtDrvSide_B_Stat 1;
BA_ "U_P702_MY2021_Tx" SG_ 820 HeadLghtDrvSide_B_Stat 1;
BA_ "U_U55X_MY2022_Tx" SG_ 820 HeadLghtDrvSide_B_Stat 1;
BA_ "U_CD764_MY2022_Tx" SG_ 820 HeadLghtDrvSide_B_Stat 1;
BA_ "GenSigSendType" SG_ 820 Adaptive_Hdlmp_Fault 3;
BA_ "U_CX727_MY2021_Tx" SG_ 820 Adaptive_Hdlmp_Fault 1;
BA_ "U_P702_MY2021_Tx" SG_ 820 Adaptive_Hdlmp_Fault 1;
BA_ "U_U55X_MY2022_Tx" SG_ 820 Adaptive_Hdlmp_Fault 1;
BA_ "U_CD764_MY2022_Tx" SG_ 820 Adaptive_Hdlmp_Fault 1;
BA_ "GenSigSendType" SG_ 820 TurnLampFrOut_B_Stat 3;
BA_ "U_CD764_MY2022_Tx" SG_ 820 TurnLampFrOut_B_Stat 1;
BA_ "GenSigSendType" SG_ 820 TurnLampFlOut_B_Stat 3;
BA_ "U_CD764_MY2022_Tx" SG_ 820 TurnLampFlOut_B_Stat 1;
BA_ "WakeupSignal" SG_ 817 DrTgateOpen_B_Rq 1;
BA_ "WakeupSignal" SG_ 817 DrTgateExtSwMde_B_Stat 1;
BA_ "WakeupSignal" SG_ 817 Remote_Device_Feedback 1;
BA_ "WakeupSignal" SG_ 817 Veh_Lock_Requestor 1;
BA_ "U_T6_MCA_MY2020_Rx" SG_ 817 Veh_Lock_Requestor 1;
BA_ "WakeupSignal" SG_ 817 R_Pwr_Sliding_Dr_Rqst 1;
BA_ "WakeupSignal" SG_ 817 Power_Liftgate_Rqst 1;
BA_ "WakeupSignal" SG_ 817 Veh_Lock_EvNum 1;
BA_ "U_T6_MCA_MY2020_Rx" SG_ 817 Veh_Lock_EvNum 1;
BA_ "WakeupSignal" SG_ 817 Power_Decklid_Rqst 1;
BA_ "WakeupSignal" SG_ 817 L_Pwr_Sliding_Dr_Rqst 1;
BA_ "WakeupSignal" SG_ 817 Keyfob_Pad_Msg_Count 1;
BA_ "WakeupSignal" SG_ 817 Veh_Lock_Status 1;
BA_ "GenSigStartValueInteger" SG_ 817 Veh_Lock_Status 1;
BA_ "GenSigStartValue" SG_ 817 Veh_Lock_Status 1;
BA_ "U_T6_MCA_MY2020_Rx" SG_ 817 Veh_Lock_Status 1;
BA_ "U_CD542_MY2021_Rx" SG_ 817 Veh_Lock_Status 1;
BA_ "U_U55X_MY2022_Rx" SG_ 817 Veh_Lock_Status 1;
BA_ "U_CD764_MY2022_Rx" SG_ 817 Veh_Lock_Status 1;
BA_ "WakeupSignal" SG_ 817 ChildLck_D_Dsply 1;
BA_ "GenSigStartValueInteger" SG_ 817 ChildLck_D_Dsply 1;
BA_ "GenSigStartValue" SG_ 817 ChildLck_D_Dsply 1;
BA_ "WakeupSignal" SG_ 817 Lockmsgtxt_D_Rq 1;
BA_ "WakeupSignal" SG_ 817 LockInhibit 1;
BA_ "U_CX727_MY2021_Rx" SG_ 129 SelDrvMdeSwtch_D_Stat4 1;
BA_ "U_P702_MY2021_Rx" SG_ 129 SelDrvMdeSwtch_D_Stat4 1;
BA_ "U_T6_MCA_MY2020_Rx" SG_ 129 SelDrvMdeSwtch_D_Stat4 1;
BA_ "U_U55X_MY2022_Rx" SG_ 129 SelDrvMdeSwtch_D_Stat4 1;
BA_ "WakeupSignal" SG_ 129 SteWhlSwtchView_B_Stat 1;
BA_ "WakeupSignal" SG_ 129 SteWhlSwtchSet_B_Stat 1;
BA_ "WakeupSignal" SG_ 129 SteWhlSwtchPhon_B_Stat 1;
BA_ "WakeupSignal" SG_ 129 SteWhlSwtchNav_B_Stat 1;
BA_ "WakeupSignal" SG_ 129 SteWhlSwtchMed_B_Stat 1;
BA_ "WakeupSignal" SG_ 129 SteWhlSwtchIod_B_Stat 1;
BA_ "WakeupSignal" SG_ 129 SteWhlSwtchHud_B_Stat 1;
BA_ "WakeupSignal" SG_ 129 SteWhlSwtchBack_B_Stat 1;
BA_ "WakeupSignal" SG_ 129 SteWhlSwtchMenu_B_Stat 1;
BA_ "WakeupSignal" SG_ 129 SteWhlSwtchUp_B_Stat 1;
BA_ "WakeupSignal" SG_ 129 SteWhlSwtchRght_B_Stat 1;
BA_ "WakeupSignal" SG_ 129 SteWhlSwtchOk_B_Stat 1;
BA_ "WakeupSignal" SG_ 129 SteWhlSwtchLeft_B_Stat 1;
BA_ "WakeupSignal" SG_ 129 SteWhlSwtchDown_B_Stat 1;
BA_ "ContentDependant" SG_ 129 SelDrvMdeSwtch3_D_Stat4 1;
BA_ "GenSigStartValueInteger" SG_ 854 Dsp_RotAddrBtnEv_St 7;
BA_ "GenSigStartValue" SG_ 854 Dsp_RotAddrBtnEv_St 7;
BA_ "U_T6_MCA_MY2020_Rx" SG_ 854 SelDrvMdeSwtch_D_Stat2 1;
BA_ "U_U55X_MY2022_Rx" SG_ 854 SelDrvMdeSwtch_D_Stat2 1;
BA_ "GenSigStartValueInteger" SG_ 854 Front_Blower_Indicate 15;
BA_ "GenSigStartValue" SG_ 854 Front_Blower_Indicate 15;
BA_ "GenSigStartValue" SG_ 854 LHS_Auto_Seat_Btn_Stt 2;
BA_ "GenSigStartValue" SG_ 854 RHS_Auto_Seat_Btn_Stt 2;
BA_ "U_T6_MCA_MY2020_Rx" SG_ 549 Veh_V2_Dsply 1;
BA_ "U_CD542_MY2021_Rx" SG_ 549 Veh_V2_Dsply 1;
BA_ "U_U55X_MY2022_Rx" SG_ 549 Veh_V2_Dsply 1;
BA_ "U_CD764_MY2022_Rx" SG_ 549 Veh_V2_Dsply 1;
BA_ "U_U55X_MY2022_Rx" SG_ 549 HdcOn_B_Rq 1;
BA_ "WakeupSignal" SG_ 549 Power_Up_Chime_Modules 1;
BA_ "U_T6_MCA_MY2020_Rx" SG_ 549 WwaActv_B_Stat 1;
BA_ "U_CD542_MY2021_Rx" SG_ 549 WwaActv_B_Stat 1;
BA_ "U_U55X_MY2022_Rx" SG_ 549 WwaActv_B_Stat 1;
BA_ "U_CD764_MY2022_Rx" SG_ 549 WwaActv_B_Stat 1;
BA_ "U_T6_MCA_MY2020_Rx" SG_ 549 StrtInGearOk_D_Stat 1;
BA_ "GenSigSendType" SG_ 935 CtaAlrtRight2_D_Stat 3;
BA_ "U_T6_MCA_MY2020_Tx" SG_ 935 CtaAlrtRight2_D_Stat 1;
BA_ "U_CD542_MY2021_Tx" SG_ 935 CtaAlrtRight2_D_Stat 1;
BA_ "U_U55X_MY2022_Tx" SG_ 935 CtaAlrtRight2_D_Stat 1;
BA_ "U_CD764_MY2022_Tx" SG_ 935 CtaAlrtRight2_D_Stat 1;
BA_ "GenSigSendType" SG_ 935 BttRight_D_Stat 3;
BA_ "U_T6_MCA_MY2020_Tx" SG_ 935 BttRight_D_Stat 1;
BA_ "U_CD542_MY2021_Tx" SG_ 935 BttRight_D_Stat 1;
BA_ "U_U55X_MY2022_Tx" SG_ 935 BttRight_D_Stat 1;
BA_ "U_CD764_MY2022_Tx" SG_ 935 BttRight_D_Stat 1;
BA_ "GenSigSendType" SG_ 935 BttRight_D_RqDrv 3;
BA_ "U_T6_MCA_MY2020_Tx" SG_ 935 BttRight_D_RqDrv 1;
BA_ "U_CD542_MY2021_Tx" SG_ 935 BttRight_D_RqDrv 1;
BA_ "U_U55X_MY2022_Tx" SG_ 935 BttRight_D_RqDrv 1;
BA_ "U_CD764_MY2022_Tx" SG_ 935 BttRight_D_RqDrv 1;
BA_ "GenSigSendType" SG_ 935 CtaBrkRightMsgTxt_B_Rq 3;
BA_ "U_T6_MCA_MY2020_Tx" SG_ 935 CtaBrkRightMsgTxt_B_Rq 1;
BA_ "U_CD542_MY2021_Tx" SG_ 935 CtaBrkRightMsgTxt_B_Rq 1;
BA_ "U_U55X_MY2022_Tx" SG_ 935 CtaBrkRightMsgTxt_B_Rq 1;
BA_ "U_CD764_MY2022_Tx" SG_ 935 CtaBrkRightMsgTxt_B_Rq 1;
BA_ "GenSigSendType" SG_ 935 CtaRightBrkEnbl_B_Rq 3;
BA_ "U_CX727_MY2021_Rx" SG_ 935 CtaRightBrkEnbl_B_Rq 1;
BA_ "U_P702_MY2021_Rx" SG_ 935 CtaRightBrkEnbl_B_Rq 1;
BA_ "U_T6_MCA_MY2020_Rx" SG_ 935 CtaRightBrkEnbl_B_Rq 1;
BA_ "U_CD542_MY2021_Rx" SG_ 935 CtaRightBrkEnbl_B_Rq 1;
BA_ "U_U55X_MY2022_Rx" SG_ 935 CtaRightBrkEnbl_B_Rq 1;
BA_ "U_CD764_MY2022_Rx" SG_ 935 CtaRightBrkEnbl_B_Rq 1;
BA_ "U_T6_MCA_MY2020_Tx" SG_ 935 CtaRightBrkEnbl_B_Rq 1;
BA_ "U_CD542_MY2021_Tx" SG_ 935 CtaRightBrkEnbl_B_Rq 1;
BA_ "U_U55X_MY2022_Tx" SG_ 935 CtaRightBrkEnbl_B_Rq 1;
BA_ "U_CD764_MY2022_Tx" SG_ 935 CtaRightBrkEnbl_B_Rq 1;
BA_ "GenSigSendType" SG_ 935 CtaRightBrkDecel_B_Rq 3;
BA_ "U_CX727_MY2021_Rx" SG_ 935 CtaRightBrkDecel_B_Rq 1;
BA_ "U_P702_MY2021_Rx" SG_ 935 CtaRightBrkDecel_B_Rq 1;
BA_ "U_T6_MCA_MY2020_Rx" SG_ 935 CtaRightBrkDecel_B_Rq 1;
BA_ "U_CD542_MY2021_Rx" SG_ 935 CtaRightBrkDecel_B_Rq 1;
BA_ "U_U55X_MY2022_Rx" SG_ 935 CtaRightBrkDecel_B_Rq 1;
BA_ "U_CD764_MY2022_Rx" SG_ 935 CtaRightBrkDecel_B_Rq 1;
BA_ "U_T6_MCA_MY2020_Tx" SG_ 935 CtaRightBrkDecel_B_Rq 1;
BA_ "U_CD542_MY2021_Tx" SG_ 935 CtaRightBrkDecel_B_Rq 1;
BA_ "U_U55X_MY2022_Tx" SG_ 935 CtaRightBrkDecel_B_Rq 1;
BA_ "U_CD764_MY2022_Tx" SG_ 935 CtaRightBrkDecel_B_Rq 1;
BA_ "GenSigStartValueInteger" SG_ 935 Side_Detect_R_Illum 100;
BA_ "GenSigStartValue" SG_ 935 Side_Detect_R_Illum 100;
BA_ "U_T6_MCA_MY2020_Tx" SG_ 935 Side_Detect_R_Illum 1;
BA_ "U_CD542_MY2021_Tx" SG_ 935 Side_Detect_R_Illum 1;
BA_ "U_U55X_MY2022_Tx" SG_ 935 Side_Detect_R_Illum 1;
BA_ "U_CD764_MY2022_Tx" SG_ 935 Side_Detect_R_Illum 1;
BA_ "GenSigSendType" SG_ 935 CtaSnsRight_D_Stat 3;
BA_ "U_T6_MCA_MY2020_Tx" SG_ 935 CtaSnsRight_D_Stat 1;
BA_ "U_CD542_MY2021_Tx" SG_ 935 CtaSnsRight_D_Stat 1;
BA_ "U_U55X_MY2022_Tx" SG_ 935 CtaSnsRight_D_Stat 1;
BA_ "U_CD764_MY2022_Tx" SG_ 935 CtaSnsRight_D_Stat 1;
BA_ "GenSigSendType" SG_ 935 CtaAlrtRight_D_Stat 3;
BA_ "U_T6_MCA_MY2020_Tx" SG_ 935 CtaAlrtRight_D_Stat 1;
BA_ "U_CD542_MY2021_Tx" SG_ 935 CtaAlrtRight_D_Stat 1;
BA_ "U_U55X_MY2022_Tx" SG_ 935 CtaAlrtRight_D_Stat 1;
BA_ "U_CD764_MY2022_Tx" SG_ 935 CtaAlrtRight_D_Stat 1;
BA_ "GenSigSendType" SG_ 935 CtaRight_D_Stat 3;
BA_ "U_T6_MCA_MY2020_Tx" SG_ 935 CtaRight_D_Stat 1;
BA_ "U_CD542_MY2021_Tx" SG_ 935 CtaRight_D_Stat 1;
BA_ "U_U55X_MY2022_Tx" SG_ 935 CtaRight_D_Stat 1;
BA_ "U_CD764_MY2022_Tx" SG_ 935 CtaRight_D_Stat 1;
BA_ "GenSigSendType" SG_ 935 SodRight_D_Stat 3;
BA_ "GenSigStartValueInteger" SG_ 935 SodRight_D_Stat 2;
BA_ "GenSigStartValue" SG_ 935 SodRight_D_Stat 2;
BA_ "U_T6_MCA_MY2020_Tx" SG_ 935 SodRight_D_Stat 1;
BA_ "U_CD542_MY2021_Tx" SG_ 935 SodRight_D_Stat 1;
BA_ "U_U55X_MY2022_Tx" SG_ 935 SodRight_D_Stat 1;
BA_ "U_CD764_MY2022_Tx" SG_ 935 SodRight_D_Stat 1;
BA_ "GenSigSendType" SG_ 935 SodSnsRight_D_Stat 3;
BA_ "U_T6_MCA_MY2020_Tx" SG_ 935 SodSnsRight_D_Stat 1;
BA_ "U_CD542_MY2021_Tx" SG_ 935 SodSnsRight_D_Stat 1;
BA_ "U_U55X_MY2022_Tx" SG_ 935 SodSnsRight_D_Stat 1;
BA_ "U_CD764_MY2022_Tx" SG_ 935 SodSnsRight_D_Stat 1;
BA_ "GenSigSendType" SG_ 935 SodAlrtRight_D_Stat 3;
BA_ "U_T6_MCA_MY2020_Tx" SG_ 935 SodAlrtRight_D_Stat 1;
BA_ "U_CD542_MY2021_Tx" SG_ 935 SodAlrtRight_D_Stat 1;
BA_ "U_U55X_MY2022_Tx" SG_ 935 SodAlrtRight_D_Stat 1;
BA_ "U_CD764_MY2022_Tx" SG_ 935 SodAlrtRight_D_Stat 1;
BA_ "GenSigSendType" SG_ 935 SodDetctRight_D_Stat 3;
BA_ "U_T6_MCA_MY2020_Tx" SG_ 935 SodDetctRight_D_Stat 1;
BA_ "U_CD542_MY2021_Tx" SG_ 935 SodDetctRight_D_Stat 1;
BA_ "U_U55X_MY2022_Tx" SG_ 935 SodDetctRight_D_Stat 1;
BA_ "U_CD764_MY2022_Tx" SG_ 935 SodDetctRight_D_Stat 1;
BA_ "GenSigStartValueInteger" SG_ 935 SodWarnRight_Prd_Rq 14;
BA_ "GenSigStartValue" SG_ 935 SodWarnRight_Prd_Rq 14;
BA_ "U_T6_MCA_MY2020_Tx" SG_ 935 SodWarnRight_Prd_Rq 1;
BA_ "U_CD542_MY2021_Tx" SG_ 935 SodWarnRight_Prd_Rq 1;
BA_ "U_U55X_MY2022_Tx" SG_ 935 SodWarnRight_Prd_Rq 1;
BA_ "U_CD764_MY2022_Tx" SG_ 935 SodWarnRight_Prd_Rq 1;
VAL_ 1176 BattTracCell45_U_Actl 4095 "Fault" 4094 "NoDataExists" ;
VAL_ 1176 BattTracCell44_U_Actl 4095 "Fault" 4094 "NoDataExists" ;
VAL_ 1176 BattTracCell43_U_Actl 4095 "Fault" 4094 "NoDataExists" ;
VAL_ 1176 BattTracCell42_U_Actl 4095 "Fault" 4094 "NoDataExists" ;
VAL_ 1176 BattTracCell41_U_Actl 4095 "Fault" 4094 "NoDataExists" ;
VAL_ 1175 BattTracCell40_U_Actl 4095 "Fault" 4094 "NoDataExists" ;
VAL_ 1175 BattTracCell39_U_Actl 4095 "Fault" 4094 "NoDataExists" ;
VAL_ 1175 BattTracCell38_U_Actl 4095 "Fault" 4094 "NoDataExists" ;
VAL_ 1175 BattTracCell37_U_Actl 4095 "Fault" 4094 "NoDataExists" ;
VAL_ 1175 BattTracCell36_U_Actl 4095 "Fault" 4094 "NoDataExists" ;
VAL_ 1174 BattTracCell35_U_Actl 4095 "Fault" 4094 "NoDataExists" ;
VAL_ 1174 BattTracCell34_U_Actl 4095 "Fault" 4094 "NoDataExists" ;
VAL_ 1174 BattTracCell33_U_Actl 4095 "Fault" 4094 "NoDataExists" ;
VAL_ 1174 BattTracCell32_U_Actl 4095 "Fault" 4094 "NoDataExists" ;
VAL_ 1174 BattTracCell31_U_Actl 4095 "Fault" 4094 "NoDataExists" ;
VAL_ 1173 BattTracCell30_U_Actl 4095 "Fault" 4094 "NoDataExists" ;
VAL_ 1173 BattTracCell29_U_Actl 4095 "Fault" 4094 "NoDataExists" ;
VAL_ 1173 BattTracCell28_U_Actl 4095 "Fault" 4094 "NoDataExists" ;
VAL_ 1173 BattTracCell27_U_Actl 4095 "Fault" 4094 "NoDataExists" ;
VAL_ 1173 BattTracCell26_U_Actl 4095 "Fault" 4094 "NoDataExists" ;
VAL_ 1172 BattTracCell25_U_Actl 4095 "Fault" 4094 "NoDataExists" ;
VAL_ 1172 BattTracCell24_U_Actl 4095 "Fault" 4094 "NoDataExists" ;
VAL_ 1172 BattTracCell23_U_Actl 4095 "Fault" 4094 "NoDataExists" ;
VAL_ 1172 BattTracCell22_U_Actl 4095 "Fault" 4094 "NoDataExists" ;
VAL_ 1172 BattTracCell21_U_Actl 4095 "Fault" 4094 "NoDataExists" ;
VAL_ 1171 BattTracCell20_U_Actl 4095 "Fault" 4094 "NoDataExists" ;
VAL_ 1171 BattTracCell19_U_Actl 4095 "Fault" 4094 "NoDataExists" ;
VAL_ 1171 BattTracCell18_U_Actl 4095 "Fault" 4094 "NoDataExists" ;
VAL_ 1171 BattTracCell17_U_Actl 4095 "Fault" 4094 "NoDataExists" ;
VAL_ 1171 BattTracCell16_U_Actl 4095 "Fault" 4094 "NoDataExists" ;
VAL_ 1170 BattTracCell15_U_Actl 4095 "Fault" 4094 "NoDataExists" ;
VAL_ 1170 BattTracCell14_U_Actl 4095 "Fault" 4094 "NoDataExists" ;
VAL_ 1170 BattTracCell13_U_Actl 4095 "Fault" 4094 "NoDataExists" ;
VAL_ 1170 BattTracCell12_U_Actl 4095 "Fault" 4094 "NoDataExists" ;
VAL_ 1170 BattTracCell11_U_Actl 4095 "Fault" 4094 "NoDataExists" ;
VAL_ 1169 BattTracCell10_U_Actl 4095 "Fault" 4094 "NoDataExists" ;
VAL_ 1169 BattTracCell09_U_Actl 4095 "Fault" 4094 "NoDataExists" ;
VAL_ 1169 BattTracCell08_U_Actl 4095 "Fault" 4094 "NoDataExists" ;
VAL_ 1169 BattTracCell07_U_Actl 4095 "Fault" 4094 "NoDataExists" ;
VAL_ 1169 BattTracCell06_U_Actl 4095 "Fault" 4094 "NoDataExists" ;
VAL_ 1188 BattTracTe13_Te_Actl 255 "Faulty" 254 "NoDataExists" ;
VAL_ 1188 BattTracTe12_Te_Actl 255 "Faulty" 254 "NoDataExists" ;
VAL_ 1188 BattTracTe11_Te_Actl 255 "Faulty" 254 "NoDataExists" ;
VAL_ 1188 BattTracTe10_Te_Actl 255 "Faulty" 254 "NoDataExists" ;
VAL_ 1188 BattTracTe09_Te_Actl 255 "Faulty" 254 "NoDataExists" ;
VAL_ 1188 BattTracTe08_Te_Actl 255 "Faulty" 254 "NoDataExists" ;
VAL_ 1188 BattTracTe07_Te_Actl 255 "Faulty" 254 "NoDataExists" ;
VAL_ 1187 BattTracTe06_Te_Actl 255 "Faulty" 254 "NoDataExists" ;
VAL_ 1187 BattTracTe05_Te_Actl 255 "Faulty" 254 "NoDataExists" ;
VAL_ 1187 BattTracTe04_Te_Actl 255 "Faulty" 254 "NoDataExists" ;
VAL_ 1187 BattTracTe03_Te_Actl 255 "Faulty" 254 "NoDataExists" ;
VAL_ 1187 BattTracTe02_Te_Actl 255 "Faulty" 254 "NoDataExists" ;
VAL_ 1187 BattTracTe01_Te_Actl 255 "Faulty" 254 "NoDataExists" ;
VAL_ 1187 BattTracCell96_U_Actl 4095 "Fault" 4094 "NoDataExists" ;
VAL_ 1168 BattTracCell05_U_Actl 4095 "Fault" 4094 "NoDataExists" ;
VAL_ 1168 BattTracCell04_U_Actl 4095 "Fault" 4094 "NoDataExists" ;
VAL_ 1168 BattTracCell03_U_Actl 4095 "Fault" 4094 "NoDataExists" ;
VAL_ 1168 BattTracCell02_U_Actl 4095 "Fault" 4094 "NoDataExists" ;
VAL_ 1168 BattTracCell01_U_Actl 4095 "Fault" 4094 "NoDataExists" ;
VAL_ 1185 BattTracCell90_U_Actl 4095 "Fault" 4094 "NoDataExists" ;
VAL_ 1185 BattTracCell89_U_Actl 4095 "Fault" 4094 "NoDataExists" ;
VAL_ 1185 BattTracCell88_U_Actl 4095 "Fault" 4094 "NoDataExists" ;
VAL_ 1185 BattTracCell87_U_Actl 4095 "Fault" 4094 "NoDataExists" ;
VAL_ 1185 BattTracCell86_U_Actl 4095 "Fault" 4094 "NoDataExists" ;
VAL_ 1184 BattTracCell85_U_Actl 4095 "Fault" 4094 "NoDataExists" ;
VAL_ 1184 BattTracCell84_U_Actl 4095 "Fault" 4094 "NoDataExists" ;
VAL_ 1184 BattTracCell83_U_Actl 4095 "Fault" 4094 "NoDataExists" ;
VAL_ 1184 BattTracCell82_U_Actl 4095 "Fault" 4094 "NoDataExists" ;
VAL_ 1184 BattTracCell81_U_Actl 4095 "Fault" 4094 "NoDataExists" ;
VAL_ 1183 BattTracCell80_U_Actl 4095 "Fault" 4094 "NoDataExists" ;
VAL_ 1183 BattTracCell79_U_Actl 4095 "Fault" 4094 "NoDataExists" ;
VAL_ 1183 BattTracCell78_U_Actl 4095 "Fault" 4094 "NoDataExists" ;
VAL_ 1183 BattTracCell77_U_Actl 4095 "Fault" 4094 "NoDataExists" ;
VAL_ 1183 BattTracCell76_U_Actl 4095 "Fault" 4094 "NoDataExists" ;
VAL_ 1182 BattTracCell75_U_Actl 4095 "Fault" 4094 "NoDataExists" ;
VAL_ 1182 BattTracCell74_U_Actl 4095 "Fault" 4094 "NoDataExists" ;
VAL_ 1182 BattTracCell73_U_Actl 4095 "Fault" 4094 "NoDataExists" ;
VAL_ 1182 BattTracCell72_U_Actl 4095 "Fault" 4094 "NoDataExists" ;
VAL_ 1182 BattTracCell71_U_Actl 4095 "Fault" 4094 "NoDataExists" ;
VAL_ 1181 BattTracCell70_U_Actl 4095 "Fault" 4094 "NoDataExists" ;
VAL_ 1181 BattTracCell69_U_Actl 4095 "Fault" 4094 "NoDataExists" ;
VAL_ 1181 BattTracCell68_U_Actl 4095 "Fault" 4094 "NoDataExists" ;
VAL_ 1181 BattTracCell67_U_Actl 4095 "Fault" 4094 "NoDataExists" ;
VAL_ 1181 BattTracCell66_U_Actl 4095 "Fault" 4094 "NoDataExists" ;
VAL_ 1180 BattTracCell65_U_Actl 4095 "Fault" 4094 "NoDataExists" ;
VAL_ 1180 BattTracCell64_U_Actl 4095 "Fault" 4094 "NoDataExists" ;
VAL_ 1180 BattTracCell63_U_Actl 4095 "Fault" 4094 "NoDataExists" ;
VAL_ 1180 BattTracCell62_U_Actl 4095 "Fault" 4094 "NoDataExists" ;
VAL_ 1180 BattTracCell61_U_Actl 4095 "Fault" 4094 "NoDataExists" ;
VAL_ 1179 BattTracCell60_U_Actl 4095 "Fault" 4094 "NoDataExists" ;
VAL_ 1179 BattTracCell59_U_Actl 4095 "Fault" 4094 "NoDataExists" ;
VAL_ 1179 BattTracCell58_U_Actl 4095 "Fault" 4094 "NoDataExists" ;
VAL_ 1179 BattTracCell57_U_Actl 4095 "Fault" 4094 "NoDataExists" ;
VAL_ 1179 BattTracCell56_U_Actl 4095 "Fault" 4094 "NoDataExists" ;
VAL_ 1178 BattTracCell55_U_Actl 4095 "Fault" 4094 "NoDataExists" ;
VAL_ 1178 BattTracCell54_U_Actl 4095 "Fault" 4094 "NoDataExists" ;
VAL_ 1178 BattTracCell53_U_Actl 4095 "Fault" 4094 "NoDataExists" ;
VAL_ 1178 BattTracCell52_U_Actl 4095 "Fault" 4094 "NoDataExists" ;
VAL_ 1178 BattTracCell51_U_Actl 4095 "Fault" 4094 "NoDataExists" ;
VAL_ 1177 BattTracCell50_U_Actl 4095 "Fault" 4094 "NoDataExists" ;
VAL_ 1177 BattTracCell49_U_Actl 4095 "Fault" 4094 "NoDataExists" ;
VAL_ 1177 BattTracCell48_U_Actl 4095 "Fault" 4094 "NoDataExists" ;
VAL_ 1177 BattTracCell47_U_Actl 4095 "Fault" 4094 "NoDataExists" ;
VAL_ 1177 BattTracCell46_U_Actl 4095 "Fault" 4094 "NoDataExists" ;
VAL_ 1186 RearDiffLckMsg_D_Rq 7 "Locker_Disabled" 6 "Locker_Enabled" 5 "Locker_Accel_Pedal" 4 "Speed4" 3 "Speed3" 2 "Spee2" 1 "Speed1" 0 "Normal__No_Message " ;
VAL_ 1186 RearDiffLck_Tq_Actl 4095 "Fault" 4094 "Unknown" ;
VAL_ 1186 RearDiffFalt_D_Stat 3 "Diff_Failed_Closed" 2 "Diff_Failed_Open" 1 "Fault_Non_Specific" 0 "No_Fault" ;
VAL_ 1186 LsdSrvcRqd_B_Rq 1 "On" 0 "Off" ;
VAL_ 1186 FrontDiffLckLamp_D_Rq 3 "Triggered" 2 "Flash" 1 "On" 0 "Off" ;
VAL_ 823 DteAcceptNew_B_Rq 1 "Yes" 0 "No" ;
VAL_ 777 ScLocSaved_B_Dsply 1 "Yes" 0 "No" ;
VAL_ 777 ScLocLongPostv_B_Stat 1 "Yes" 0 "No" ;
VAL_ 777 ScLocLattPostv_B_Stat 1 "Yes" 0 "No" ;
VAL_ 771 ScDayOfWeekId_D_Stat 7 "Sunday" 6 "Saturday" 5 "Friday" 4 "Thursday" 3 "Wednesday" 2 "Tuesday" 1 "Monday" 0 "NotUsed" ;
VAL_ 771 ScChrgDurSet_B_Stat 1 "On" 0 "Off" ;
VAL_ 513 ChrgStat_D3_Dsply 31 "NotUsed_13" 30 "NotUsed_12" 29 "NotUsed_11" 28 "NotUsed_10" 27 "NotUsed_9" 26 "NotUsed_8" 25 "NotUsed_7" 24 "NotUsed_6" 23 "NotUsed_5" 22 "NotUsed_4" 21 "NotUsed_3" 20 "NotUsed_2" 19 "NotUsed_1" 18 "Discharging" 17 "GridChargeStopCommanded" 16 "GridChargeStartCommanded" 15 "ChargeStopCommanded" 14 "ChargeStartCommanded" 13 "ChargeTargetReached" 12 "DriveConditioning" 11 "CabinPreconditioning" 10 "ChargingSystemMaintain" 9 "ChargingInductive" 8 "ChargingDCFastCharge" 7 "ChargingAC" 6 "ChargeScheduled" 5 "EvsePaused" 4 "EvseNotDetected" 3 "EvseNotCompatible" 2 "FaultOutsideCar" 1 "FaultInsideCar" 0 "NotReady" ;
VAL_ 368 PrplWhlTot_Tq_RqFilt 65535 "Faulty" 65534 "NoDataExists" ;
VAL_ 536 BrkCtlSys_D_Stat 15 "ESCDis_TCSDis" 14 "ESCDis_TCSRed" 13 "ESCDis_TCSFull" 12 "ESCDis_TCSNde" 11 "ESCRed_TCSDis" 10 "ESCRed_TCSRed" 9 "ESCRed_TCSFull" 8 "ESCRed_TCSNde" 7 "ESCFull_TCSDis" 6 "ESCFull_TCSRed" 5 "ESCFull_TCSFull" 4 "ESCFull_TCSNde" 3 "ESCNde_TCSDis" 2 "ESCNde_TCSRed" 1 "ESCNde_TCSFull" 0 "ESCNde_TCSNde" ;
VAL_ 536 BrkWhlFricRr_Tq_Actl 255 "Faulty" 254 "NoDataExists" ;
VAL_ 536 BrkWhlFricRl_Tq_Actl 255 "Faulty" 254 "NoDataExists" ;
VAL_ 536 BrkWhlFricFr_Tq_Actl 255 "Faulty" 254 "NoDataExists" ;
VAL_ 536 BrkWhlFricFl_Tq_Actl 255 "Faulty" 254 "NoDataExists" ;
VAL_ 66 immoControlCmd_T2 0 "IDLE" 1 "MOTIVE_START_RQST" 2 "NONMOTIVE_START_RQST" 3 "RQST_TARGET2_IDBLOCK1" 4 "RQST_TARGET2_IDBLOCK2" 5 "LIMITEDMOTIVE_START_RQST" 6 "ECHO_TARGET2_IDBLOCK2" 7 "SHUTDOWN" ;
VAL_ 770 ChrgTrgtSocOvrrd_B_Stat 1 "On" 0 "Off" ;
VAL_ 770 ScPayloadUpdate_B_Stat 3 "NotUsed" 2 "Complete" 1 "InProcess" 0 "Null" ;
VAL_ 770 ScChrgrPwMax_Pw_Actl 4095 "Faulty" ;
VAL_ 770 ScEnbl_B_Stat 1 "On" 0 "Off" ;
VAL_ 897 VehElAvgTrip2_Eff_Dsply 127 "Faulty" 126 "NoDataExists" ;
VAL_ 897 Trip2SumDrvE_Pc_Dsply 1023 "Faulty" 1022 "NoDataExists" ;
VAL_ 897 Trip2ExtFctrE_Pc_Dsply 1023 "Faulty" 1022 "NoDataExists" ;
VAL_ 897 Trip2ClimE_Pc_Dsply 1023 "Faulty" 1022 "NoDataExists" ;
VAL_ 897 Trip2BattULoE_Pc_Dsply 1023 "Faulty" 1022 "NoDataExists" ;
VAL_ 896 VehElAvgTrip1_Eff_Dsply 127 "Faulty" 126 "NoDataExists" ;
VAL_ 896 Trip1SumDrvE_Pc_Dsply 1023 "Faulty" 1022 "NoDataExists" ;
VAL_ 896 Trip1ExtFctrE_Pc_Dsply 1023 "Faulty" 1022 "NoDataExists" ;
VAL_ 896 Trip1ClimE_Pc_Dsply 1023 "Faulty" 1022 "NoDataExists" ;
VAL_ 896 Trip1BattULoE_Pc_Dsply 1023 "Faulty" 1022 "NoDataExists" ;
VAL_ 925 VehElEffTrip_No_Dsply 127 "Faulty" 126 "NoDataExists" ;
VAL_ 925 TripSumDrvE_Pc_Dsply 1023 "Faulty" 1022 "NoDataExists" ;
VAL_ 925 TripExtFctrE_Pc_Dsply 1023 "Faulty" 1022 "NoDataExists" ;
VAL_ 925 TripClimE_Pc_Dsply 1023 "Faulty" 1022 "NoDataExists" ;
VAL_ 925 TripBattULoE_Pc_Dsply 1023 "Faulty" 1022 "NoDataExists" ;
VAL_ 785 VehPerfDemo_D_Stat 3 "NotUsed" 2 "NotReady" 1 "Active" 0 "Inactive" ;
VAL_ 785 VehVLimMsgTxt_B_Rq 1 "Yes" 0 "No" ;
VAL_ 785 BattElecPerf_D2_Actl 7 "NotUsed" 6 "SeverelyLimitedPerformance" 5 "LimitedPerformance" 4 "SeverelyLimPerf_MotorTe" 3 "LimitedPerf_MotorTe" 2 "SeverelyLimPerf_BatteryTe" 1 "LimitedPerf_BatteryTe" 0 "NoMessage" ;
VAL_ 785 RgenAnimation_B_Dsply 1 "Active" 0 "Inactive" ;
VAL_ 785 BattTracLimPerf_D_Dsply 3 "NotUsed" 2 "SeverelyLimitedPerformance" 1 "LimitedPerformance" 0 "NoDisplay" ;
VAL_ 785 EcoIdl_D_Stat 3 "NotUsed" 2 "Enabled" 1 "Disabled" 0 "Null" ;
VAL_ 785 DteVehOffst_L_Dsply 8191 "Faulty" 8190 "NoDataExists" ;
VAL_ 785 DteVehOffstMsgTxt_D_Rq 15 "NotUsed_7" 14 "NotUsed_6" 13 "NotUsed_5" 12 "NotUsed_4" 11 "NotUsed_3" 10 "NotUsed_2" 9 "NotUsed_1" 8 "PowerToTheBox" 7 "Payload" 6 "TrailerTowing_Off" 5 "TrailerTowing_On" 4 "TrafficAlongRoute" 3 "ExternalTemperature" 2 "HillyTerrain" 1 "DestinationRoute" 0 "NoMessage" ;
VAL_ 785 PwPckTqRdyChime_B_Rq 3 "NotUsed" 2 "Shutdown" 1 "Startup" 0 "Null" ;
VAL_ 785 BattTracLoThres_D_Stat 7 "NotUsed" 6 "Thres80km_50mi" 5 "Thres50km_31mi" 4 "Thres30km_18mi" 3 "Thres50mi_80km" 2 "Thres30mi_48km" 1 "Thres20mi_32km" 0 "Null" ;
VAL_ 785 BattTracLoMsgTxt_D_Rq 7 "NotUsed_2" 6 "NotUsed_1" 5 "ZeroDteBatteryDepleted" 4 "ClimateLowDteSecondAlert" 3 "ClimateLowDteFirstAlert" 2 "LowDteSecondAlert" 1 "LowDteFirstAlert" 0 "Null" ;
VAL_ 785 BattTracLoSoc_D_Dsply 3 "NotUsed" 2 "ZeroDteDepletedBattery" 1 "LoDte" 0 "Null" ;
VAL_ 932 VehOnSrc2_D_Stat 15 "NotUsed_11" 14 "NotUsed_10" 13 "NotUsed_9" 12 "NotUsed_8" 11 "NotUsed_7" 10 "NotUsed_6" 9 "EsclRssd" 8 "AutonomousVehicle" 7 "SecureIdle" 6 "FleetVehicleInhibit" 5 "StolenVehicleInhibit" 4 "OverTheAir" 3 "RemoteParkAssist" 2 "RemoteStart" 1 "Manual" 0 "Off" ;
VAL_ 816 HybMdeSel_D_Rq 7 "NotUsed_2" 6 "NotUsed_1" 5 "EV_Override_Mode" 4 "EV_Charge_Mode" 3 "EV_Later_Mode" 2 "EV_Now_Mode" 1 "EV_Auto_Mode" 0 "Null" ;
VAL_ 627 VehToInfrstrctr_D_Stat 3 "SubComponentUnknownError" 2 "LostConnection" 1 "InServiceWithoutV2IData" 0 "InServiceFunctionOK" 7 "Faulty" 6 "NoDataExists" 5 "NotUsed_2" 4 "NotUsed_1" ;
VAL_ 627 RoadStopLineL_B_Avail 1 "On" 0 "Off" ;
VAL_ 627 RoadStopLine_L_Est 65535 "Faulty" 65534 "NoDataExists" ;
VAL_ 627 RoadSignInfo1_D_Dsply 255 "Faulty" 254 "NoDataExists" 253 "NotUsed_219" 35 "NotUsed_1" 34 "DangerRoadAhead" 33 "WaterPipeBreak" 32 "WaterOnRoad" 31 "VehiclesInQue" 30 "VehicleBreak" 29 "TunnelInWaterAhead" 28 "TrafficControlAhead" 27 "TrafficAccidentAhead" 26 "Speedlimit_120" 25 "Speedlimit_110" 24 "Speedlimit_100" 23 "Speedlimit_90" 22 "Speedlimit_80" 21 "Speedlimit_70" 20 "Speedlimit_60" 19 "Speedlimit_50" 18 "Speedlimit_40" 17 "Speedlimit_30" 16 "Speedlimit_20" 15 "Speedlimit_10" 14 "SlipperyRoad" 13 "SandstormAhead" 12 "FrozenRoad" 11 "FireAlarmOnRoad" 10 "RoadCrack" 9 "RainOrSnowRoad" 8 "Pedestrian" 7 "GoodsDrop" 6 "GasPipeLeakWarning" 5 "FogAhead" 4 "DriveWrongWay" 3 "CrossWindAhead" 2 "RoadWorksAhead" 1 "SlowTrafficAhead" 0 "Inactive" ;
VAL_ 627 TrfcLghtWarnActv_B_Stat 1 "On" 0 "Off" ;
VAL_ 627 TrfcLghtVActv_B_Stat 1 "On" 0 "Off" ;
VAL_ 627 TrfcLghtDir_D_Stat 7 "Faulty" 6 "NoDataExists" 5 "NotUsed" 4 "UtrunActivated" 3 "RightActivated" 2 "LeftActivated" 1 "StraightActivated" 0 "Inactive" ;
VAL_ 627 TrfcLghtDecel_A_Dsply 127 "Faulty" 126 "NoDataExists" ;
VAL_ 627 TrfcLght_V_Mx 255 "Faulty" 254 "NoDataExists" ;
VAL_ 627 TrfcLght_V_Mn 255 "Faulty" 254 "NoDataExists" ;
VAL_ 627 TrfcLght_D_Stat 7 "Faulty" 6 "NoDataExists" 5 "NotUsed" 4 "Four" 3 "Three" 2 "Two" 1 "One" 0 "OffOrNoMatchedLight" ;
VAL_ 630 TrfcLghtRight_T_Actl 255 "Faulty" 254 "NoDataExists" ;
VAL_ 630 TrfcLghtLeftType_D_Stat 3 "Faulty" 2 "DirectionalArrow" 1 "RoundBall" 0 "Inactive" ;
VAL_ 630 TrfcLghtLeftOn_D_Stat 7 "Faulty" 6 "NoDataExists" 5 "NotUsed" 4 "FocusedBlink" 3 "FocusedOn" 2 "Blink" 1 "On" 0 "Inactive" ;
VAL_ 630 TrfcLghtLeftColr_D_Stat 7 "Faulty" 6 "NoDataExists" 5 "NotUsed_2" 4 "NotUsed_1" 3 "Green" 2 "Orange" 1 "Red" 0 "Inactive" ;
VAL_ 630 TrfcLghtLeft_T_Actl 255 "Faulty" 254 "NoDataExists" ;
VAL_ 630 TrfcLghtStrghtType_D_St 3 "Faulty" 2 "DirectionalArrow" 1 "RoundBall" 0 "Inactive" ;
VAL_ 630 TrfcLghtStrghtOn_D_Stat 7 "Faulty" 6 "NoDataExists" 5 "NotUsed" 4 "FocusedBlink" 3 "FocusedOn" 2 "Blink" 1 "On" 0 "Inactive" ;
VAL_ 630 TrfcLghtStrghtColr_D_St 7 "Faulty" 6 "NoDataExists" 5 "NotUsed_2" 4 "NotUsed_1" 3 "Green" 2 "Orange" 1 "Red" 0 "Inactive" ;
VAL_ 630 TrfcLghtStrght_T_Actl 255 "Faulty" 254 "NoDataExists" ;
VAL_ 630 TrfcLghtUturnType_D_St 3 "Faulty" 2 "DirectionalArrow" 1 "RoundBall" 0 "Inactive" ;
VAL_ 630 TrfcLghtUturnOn_D_Stat 7 "Faulty" 6 "NoDataExists" 5 "NotUsed" 4 "FocusedBlink" 3 "FocusedOn" 2 "Blink" 1 "On" 0 "Inactive" ;
VAL_ 630 TrfcLghtUturnColr_D_St 7 "Faulty" 6 "NoDataExists" 5 "NotUsed_2" 4 "NotUsed_1" 3 "Green" 2 "Orange" 1 "Red" 0 "Inactive" ;
VAL_ 630 TrfcLghtUturn_T_Actl 255 "Faulty" 254 "NoDataExists" ;
VAL_ 630 TrfcLghtRightType_D_St 3 "Faulty" 2 "DirectionalArrow" 1 "RoundBall" 0 "Inactive" ;
VAL_ 630 TrfcLghtRightOn_D_Stat 7 "Faulty" 6 "NoDataExists" 5 "NotUsed" 4 "FocusedBlink" 3 "FocusedOn" 2 "Blink" 1 "On" 0 "Inactive" ;
VAL_ 630 TrfcLghtRightColr_D_St 7 "Faulty" 6 "NoDataExists" 5 "NotUsed_2" 4 "NotUsed_1" 3 "Green" 2 "Orange" 1 "Red" 0 "Inactive" ;
VAL_ 650 GridSrvcSbscrb01_D_Stat 3 "NotUsed" 2 "Yes" 1 "No" 0 "Null" ;
VAL_ 650 GridSrvc01_D_Rq 3 "Faulty" 2 "No_Data_Exists" 1 "On" 0 "Off" ;
VAL_ 650 BptTglCnt_No_Rq 15 "Faulty" 14 "NoDataExists" ;
VAL_ 650 BptTgl_D_Rq 3 "Faulty" 2 "NoDataExists" 1 "Request" 0 "NoRequest" ;
VAL_ 650 BptStrtStop_D_RqCld 3 "NotUsed_1" 2 "Start" 1 "Stop" 0 "NoRequest" ;
VAL_ 650 BptMnSoc_L_RqCld 8191 "Faulty" 8190 "NoDataExists" ;
VAL_ 650 BptMde_D_RqCld 7 "NotUsed_4" 6 "NotUsed_3" 5 "NotUsed_2" 4 "NotUsed_1" 3 "Automatic" 2 "Manual" 1 "Off" 0 "Null" ;
VAL_ 650 BptIsol_D_Stat 7 "Faulty" 6 "NoDataExists" 5 "NotUsed_3" 4 "NotUsed_2" 3 "NotUsed_1" 2 "Valid" 1 "Warning" 0 "Invalid" ;
VAL_ 650 BptDly_T_RqCld 63 "Faulty" 62 "NoDataExists" ;
VAL_ 650 BptComm_D_Stat 7 "Faulty" 6 "NoDataExists" 5 "LostCommunicationWithTcu" 4 "LostCommunicationWithEvse" 3 "CommunicationEstablished" 2 "EstablishingCommunication" 1 "EvseNotDetected" 0 "Standby" ;
VAL_ 650 Bpt_D_StatEvse 15 "Faulty" 14 "NoDataExists" 13 "NotUsed_6" 12 "NotUsed_5" 11 "NotUsed_4" 10 "NotUsed_3" 9 "NotUsed_2" 8 "NotUsed_1" 7 "EvseFault" 6 "EvseEnergyTransferActive" 5 "EvsePreChargeReady" 4 "EvseBptReady" 3 "ConnectionTglNotConfirmed" 2 "ConnectionTglConfirmed" 1 "Initialization" 0 "NotReady" ;
VAL_ 655 EvseChrgOutHi_U_ActlBpt 1023 "Faulty" 1022 "NoDataExists" ;
VAL_ 655 EvseChrgOutHi_I_ActlBpt 32767 "Faulty" 32766 "NoDataExists" ;
VAL_ 655 EvseDchrg_Pw_Mx 32767 "Faulty" 32766 "NoDataExists" ;
VAL_ 655 EvseDchrg_I_Mx 32767 "Faulty" 32766 "NoDataExists" ;
VAL_ 599 Bpt_D_StatBattTrac 7 "Faulty" 6 "NotUsed_3" 5 "NotUsed_2" 4 "NotUsed_1" 3 "Active" 2 "Ready" 1 "Wait" 0 "NotReady" ;
VAL_ 595 DrvIdMde_D_Rq 7 "Faulty" 6 "NotUsed_2" 5 "NotUsed_1" 4 "DeleteMid" 3 "ClearAll" 2 "Enroll" 1 "Recognize" 0 "Disable" ;
VAL_ 986 Trlr_M_Rq 2047 "Faulty" 2046 "NoDataExists" ;
VAL_ 986 VehFalr_D_Rq 7 "NotUsed_3" 6 "NotUsed_2" 5 "NotUsed_1" 4 "NotComplete" 3 "Complete" 2 "RequestSecondMeasurement" 1 "RequestFirstMeasurement" 0 "NoRequest" ;
VAL_ 986 TailLghtLoadMde_D_Rq 7 "NotUsed_3" 6 "NotUsed_2" 5 "NotUsed_1" 4 "DeactivateAll" 3 "ActivateFalrMode" 2 "ActivateHitchLoadMode" 1 "ActivatePayloadMode" 0 "NoCommand" ;
VAL_ 986 VehPayloadTare_D_Rq 1 "Request" 0 "NoRequest" ;
VAL_ 986 VehPayloadScrn_D_Rq 7 "CheckLoadScreenActive" 6 "WeightCarryScreenActive" 5 "GooseneckScreenActive" 4 "FifthWheelScreenActive" 3 "WeightDistScreenActive" 2 "AddMassEstScreenActive" 1 "PayloadEstScreenActive" 0 "ScaleScreenNotActive" ;
VAL_ 986 LightAmbIntsty_No_Rq 0 "Off" ;
VAL_ 1191 BattTracTe14_Te_Actl 255 "Faulty" 254 "NoDataExists" ;
VAL_ 1191 BattTracTe19_Te_Actl 255 "Faulty" 254 "NoDataExists" ;
VAL_ 1191 BattTracTe18_Te_Actl 255 "Faulty" 254 "NoDataExists" ;
VAL_ 1191 BattTracTe17_Te_Actl 255 "Faulty" 254 "NoDataExists" ;
VAL_ 1191 BattTracTe16_Te_Actl 255 "Faulty" 254 "NoDataExists" ;
VAL_ 1191 BattTracTe15_Te_Actl 255 "Faulty" 254 "NoDataExists" ;
VAL_ 1190 BattTracUMxArry_No_Actl 31 "Faulty" ;
VAL_ 1190 BattTracCellUMx_No_Actl 255 "Faulty" 254 "NoDataExists" ;
VAL_ 1190 BattChrgUMx_B_Falt 1 "Yes" 0 "No" ;
VAL_ 1190 BattTracCellUMn_No_Actl 255 "Faulty" 254 "NoDataExists" ;
VAL_ 1190 BattTracCellCnt_No_Actl 255 "Faulty" 254 "NoDataExists" ;
VAL_ 1190 BattChrgIsltn_B_Falt 1 "Yes" 0 "No" ;
VAL_ 1190 BattTracCellDiff_B_Falt 1 "Yes" 0 "No" ;
VAL_ 1190 BattChrgSocMx_B_Falt 1 "Yes" 0 "No" ;
VAL_ 1190 BattChrgSocMn_B_Falt 1 "Yes" 0 "No" ;
VAL_ 1190 BattChrgSocErrtc_B_Falt 1 "Yes" 0 "No" ;
VAL_ 1190 BattTracUMx_B_Falt 1 "Yes" 0 "No" ;
VAL_ 1190 BattTracUMn_B_Falt 1 "Yes" 0 "No" ;
VAL_ 1190 BattTracTeMx_No_Actl 255 "Faulty" 254 "NoDataExists" ;
VAL_ 1190 BattTracTeMx_B_Falt 1 "Yes" 0 "No" ;
VAL_ 1190 BattTracTeMn_No_Actl 255 "Faulty" 254 "NoDataExists" ;
VAL_ 1190 BattTracTeDelta_B_Falt 1 "Yes" 0 "No" ;
VAL_ 1190 BattTracTeCnt_No_Actl 255 "Faulty" 254 "NoDataExists" ;
VAL_ 1190 BattTracSoftware_B_Falt 1 "Yes" 0 "No" ;
VAL_ 1192 BattTracCell95_U_Actl 4095 "Fault" 4094 "NoDataExists" ;
VAL_ 1192 BattTracCell94_U_Actl 4095 "Fault" 4094 "NoDataExists" ;
VAL_ 1192 BattTracCell93_U_Actl 4095 "Fault" 4094 "NoDataExists" ;
VAL_ 1192 BattTracCell92_U_Actl 4095 "Fault" 4094 "NoDataExists" ;
VAL_ 1192 BattTracCell91_U_Actl 4095 "Fault" 4094 "NoDataExists" ;
VAL_ 1245 RearDiffLckLamp_D_Cstm 3 "Not_Used" 2 "Flash" 1 "On" 0 "Off" ;
VAL_ 1245 FrontDiffLckLamp_D_Cstm 3 "Fast_Flash" 2 "Slow_Flash" 1 "On" 0 "Off" ;
VAL_ 1245 AwdMdeCstm_D_RqDrv 7 "Faulty" 6 "NotUsed_3" 5 "NotUsed_2" 4 "NotUsed_1" 3 "FourByFourLow" 2 "FourByFourHigh" 1 "FourByFourAuto" 0 "FourByTwo" ;
VAL_ 1245 SelDrvMdeAwd2_D_Cstm 31 "Faulty" 30 "NotUsed_17" 29 "NotUsed_16" 28 "NotUsed_15" 27 "NotUsed_14" 26 "NotUsed_13" 25 "NotUsed_12" 24 "NotUsed_11" 23 "NotUsed_10" 22 "NotUsed_9" 21 "NotUsed_8" 20 "CustomMode" 19 "OnePedalDrive" 18 "DragMode" 17 "EvLaterChargeMode" 16 "EvNowMode" 15 "TrackMode" 14 "RoughRoadMode" 13 "NotAvailable" 12 "HighSpeedDesertMode_Baja" 11 "SportAdaptiveMode" 10 "RockCrawlMode" 9 "MudRutsMode" 8 "SandMode" 7 "EconomyMode" 6 "GrassGravelSnow" 5 "TowHaulMode" 4 "SportMode" 3 "Normal_4L" 2 "Normal_4A" 1 "Normal_2H" 0 "NormalMode" ;
VAL_ 1242 SelDrvMdeCstmPt_D_Rq 31 "Faulty" 30 "NotUsed15" 29 "NotUsed14" 28 "NotUsed13" 27 "NotUsed12" 26 "NotUsed11" 25 "NotUsed10" 24 "NotUsed9" 23 "NotUsed8" 22 "NotUsed7" 21 "CustomMode" 20 "TrackMode" 19 "OnePedalDrive" 18 "EvLaterChargerMode" 17 "EvNowMode" 16 "DragMode" 15 "HighSpeedDesertMode_Baja" 14 "SportAdaptiveMode" 13 "NotAvailable_13" 12 "NotAvailable_12" 11 "NotAvailable_11" 10 "NotAvailable_10" 9 "RockCrawlMode" 8 "MudRutsMode" 7 "SandMode" 6 "EconomyMode" 5 "GrassGravelSnow" 4 "NotAvailable_04" 3 "TowHaulMode" 2 "NotAvailable_02" 1 "SportMode" 0 "NormalMode" ;
VAL_ 1242 EngExhMdeQuietCstm_D_Rq 7 "Faulty" 6 "NotUsed_2" 5 "NotUsed_1" 4 "Track" 3 "Sport" 2 "Normal" 1 "Stealth" 0 "Null" ;
VAL_ 1242 StopStrtCstm_D_Rq 3 "Faulty" 2 "On" 1 "Off" 0 "NotAvailable" ;
VAL_ 1116 TrlrAidSetup_D2_Rq 15 "NotUsed_9" 14 "NotUsed_8" 13 "NotUsed_7" 12 "NotUsed_6" 11 "NotUsed_5" 10 "NotUsed_4" 9 "NotUsed_3" 8 "NotUsed_2" 7 "NotUsed_1" 6 "CompleteSetup" 5 "ReturnToSetup" 4 "StickerNotCircled" 3 "ConfirmSetup" 2 "EndSetup" 1 "BeginSetup" 0 "Inactive" ;
VAL_ 1116 TrlrAidEnbl_D2_Rq 7 "NotUsed_4" 6 "NotUsed_3" 5 "NotUsed_2" 4 "NotUsed_1" 3 "Deactivate" 2 "ActivateTrg" 1 "ActivateTba" 0 "Inactive" ;
VAL_ 1116 TlightTest_D_Mnu 3 "TestEndAcknowledge" 2 "StartTest" 1 "StopTest" 0 "Null" ;
VAL_ 1116 TrlrRvrseCancl_B_Rq 1 "Cancel" 0 "Null" ;
VAL_ 1116 TrlrIdType_D_Stat 3 "Gooseneck" 2 "FifthWheel" 1 "Conventional" 0 "Null" ;
VAL_ 1116 TrlrAnOffstDir_D_Mem 3 "NotUSed" 2 "Right" 1 "Left_or_Center" 0 "Null" ;
VAL_ 954 ExtLghtFront_D_RqBody 3 "NotUsed" 2 "On" 1 "Off" 0 "Null" ;
VAL_ 954 VehWlcmFrwlMde_D_Stat 7 "IlluminatedExit" 6 "CourtesyLightingDelayExt" 5 "CourtesyLightingExtended" 4 "CourtesyLightingDelayAll" 3 "CourtesyLightingAll" 2 "IlluminatedEntry" 1 "Approach" 0 "Null" ;
VAL_ 954 CrtsyLghtRear_D_Stat 3 "NotUsed" 2 "Automatic" 1 "Manual" 0 "Null" ;
VAL_ 954 ChildLckMaint_D_Stat 3 "NotUsed" 2 "Overruled" 1 "On" 0 "Off" ;
VAL_ 954 PosLghtFl_D_Stat 3 "Faulty" 2 "Outage" 1 "On" 0 "Off" ;
VAL_ 954 PosLghtFr_D_Stat 3 "Faulty" 2 "Outage" 1 "On" 0 "Off" ;
VAL_ 954 PudSptLghtRight_D_Rq 3 "NotUsed" 2 "On" 1 "Off" 0 "Null" ;
VAL_ 954 PudSptLghtLeft_D_Rq 3 "NotUsed" 2 "On" 1 "Off" 0 "Null" ;
VAL_ 954 ExtLghtRight_D_Stat 3 "NotUsed" 2 "On" 1 "Off" 0 "Null" ;
VAL_ 954 ExtLghtRear_D_Stat 3 "NotUsed" 2 "On" 1 "Off" 0 "Null" ;
VAL_ 954 ExtLghtLeft_D_Stat 3 "NotUsed" 2 "On" 1 "Off" 0 "Null" ;
VAL_ 954 ExtLghtFront_D_Stat 3 "NotUsed" 2 "On" 1 "Off" 0 "Null" ;
VAL_ 954 CargoLght_D_Stat 3 "NotUsed" 2 "Automatic" 1 "Manual" 0 "Null" ;
VAL_ 954 TlghtTestLght_D_Stat 7 "Error" 6 "AllOff" 5 "TestingReverseLights" 4 "TestingBrakeLights" 3 "TestingLeftTurnSignal" 2 "TestingRightTurnSignal" 1 "ParkingLightsIlluminated" 0 "Null" ;
VAL_ 954 LghtAmbDrvMde_B_Stat 1 "Automatic" 0 "Manual" ;
VAL_ 954 KeylessIdl_B_Stat 1 "Pressed" 0 "Not_Pressed" ;
VAL_ 954 PwRnngBoardPoll_D_Stat 3 "NotUsed" 2 "PkPresent" 1 "PkNotPresent" 0 "NotPolling" ;
VAL_ 954 PoliceDmngLvl_D_Stat 7 "NotUsed" 6 "Off_Night" 5 "Off_Day" 4 "Low1Night" 3 "Low1Day" 2 "Inactive" 1 "Decommissioned" 0 "Null" ;
VAL_ 954 TrlrHitchLamp_D_Stat 1 "On" 0 "Off" ;
VAL_ 954 LicPlateLght_B_Stat 1 "On" 0 "Off" ;
VAL_ 954 TrukBedLght_B_Stat 1 "On" 0 "Off" ;
VAL_ 954 VehWlcmFrwl_D_Stat 3 "RunStart" 2 "Farewell" 1 "Welcome" 0 "Null" ;
VAL_ 954 TlghtTestPrecnd_D_Stat 7 "Error" 6 "NotStationary" 5 "InteractionPresent" 4 "PreconditionsPassed" 3 "BattSocLessThan75Percent" 2 "TailLightsOn" 1 "IgnitionNotOn" 0 "Null" ;
VAL_ 954 TlghtTest_D_Stat 3 "InProgress" 2 "Ended" 1 "Completed" 0 "Null" ;
VAL_ 954 ExtLghtAlrt_B_Rq 1 "Yes" 0 "No" ;
VAL_ 954 ExtLght_D_Falt 3 "Error" 2 "NoStationary" 1 "StartEngine" 0 "Null" ;
VAL_ 874 AirCondCluOpen_D_Falt 3 "NotUsed" 2 "Pass" 1 "Fail" 0 "Not_Diagnose_Yet" ;
VAL_ 874 AirCondCluLife_D_Falt 3 "NotUsed" 2 "Pass" 1 "Fail" 0 "Not_Diagnose_Yet" ;
VAL_ 874 AirCondCluGnd_D_Falt 3 "NotUsed" 2 "Pass" 1 "Fail" 0 "Not_Diagnose_Yet" ;
VAL_ 874 AirCondClu_D_Stat 7 "NotUsed" 6 "FetLifeLimitReached" 5 "FetOpenCircuit" 4 "FetOutputShortToPower" 3 "FetOutputShortToGround" 2 "FetNotControlled" 1 "OnPowerToLoad" 0 "OffNoPowerToLoad" ;
VAL_ 874 AirCondCluBatt_D_Falt 3 "NotUsed" 2 "Pass" 1 "Fail" 0 "Not_Diagnose_Yet" ;
VAL_ 874 BattTracShrtGrnd_D_Falt 3 "NotUsed" 2 "Pass" 1 "Fail" 0 "Not_Diagnose_Yet" ;
VAL_ 874 BattTracShrtBatt_D_Falt 3 "NotUsed" 2 "Pass" 1 "Fail" 0 "Not_Diagnose_Yet" ;
VAL_ 874 BattTracOpnCirct_D_Falt 3 "NotUsed" 2 "Pass" 1 "Fail" 0 "Not_Diagnose_Yet" ;
VAL_ 874 BattTracLifeLim_D_Falt 3 "NotUsed" 2 "Pass" 1 "Fail" 0 "Not_Diagnose_Yet" ;
VAL_ 874 BattChlrShrtGrnd_D_Falt 3 "NotUsed" 2 "Pass" 1 "Fail" 0 "Not_Diagnose_Yet" ;
VAL_ 874 BattChlrShrtBatt_D_Falt 3 "NotUsed" 2 "Pass" 1 "Fail" 0 "Not_Diagnose_Yet" ;
VAL_ 874 BattChlrOpnCirct_D_Falt 3 "NotUsed" 2 "Pass" 1 "Fail" 0 "Not_Diagnose_Yet" ;
VAL_ 874 BattChlrLifeLim_D_Falt 3 "NotUsed" 2 "Pass" 1 "Fail" 0 "Not_Diagnose_Yet" ;
VAL_ 874 BattTracLow_D_Falt 3 "NotUsed" 2 "Pass" 1 "Fail" 0 "Not_Diagnose_Yet" ;
VAL_ 551 VehPerfDemo_B_RqDrv 1 "On" 0 "Off" ;
VAL_ 551 PrkBrkPerfMnuOn_D_Stat 3 "Faulty" 2 "NotUsed" 1 "On" 0 "Off" ;
VAL_ 551 PrkBrkPerfButtn_D_Stat 3 "Faulty" 2 "NotUsed" 1 "Pressed" 0 "Not_Pressed" ;
VAL_ 551 TjaLaneBiasEnbl_D_RqMnu 3 "NotUsed" 2 "Enabled" 1 "Disabled" 0 "Null" ;
VAL_ 551 Rba_D_Rq 3 "NotUsed" 2 "On" 1 "Off" 0 "Null" ;
VAL_ 551 EmPrflNo_D_Rq 7 "NotUsed_3" 6 "NotUsed_2" 5 "NotUsed_1" 4 "Pers4" 3 "Pers3" 2 "Pers2" 1 "Pers1" 0 "Null" ;
VAL_ 551 EmPrflButtnAssoc_D_Rq 3 "NotUsed" 2 "ExitButtonAssociation" 1 "EnterButtonAssociation" 0 "Null" ;
VAL_ 551 EmPrflKeyAssoc_D_Rq 7 "NotUsed_3" 6 "DisassociatePhone" 5 "EnterPhoneAssociation" 4 "OverwriteKey" 3 "DisassociateKey" 2 "ExitKeyAssociation" 1 "EnterKeyAssociation" 0 "Null" ;
VAL_ 551 Em_D_Stat 3 "NotSupported" 2 "ProfilesOff" 1 "ProfilesOn" 0 "Null" ;
VAL_ 551 ChrgOvrdExitScrn_D_Rq 3 "NotUsed_1" 2 "Request_override" 1 "Do_not_request_override" 0 "Inactive" ;
VAL_ 551 PrcondEdit_D_RqMnu 7 "NotUsed_3" 6 "NotUsed_2" 5 "NotUsed_1" 4 "High" 3 "Medium" 2 "Low" 1 "Off" 0 "Null" ;
VAL_ 551 ChrgToPcEdit_Pc_RqMnu 127 "Faulty" 126 "NoDataExists" ;
VAL_ 551 EcoIdl_D_Rq 3 "NotUsed" 2 "Enabled" 1 "Disabled" 0 "Null" ;
VAL_ 551 PmCabnLvl_D_Stat 7 "NotUsed_1" 6 "Level_6_Worst" 5 "Level_5" 4 "Level_4" 3 "Level_3" 2 "Level_2" 1 "Level_1_Best" 0 "NotKnown" ;
VAL_ 551 PmCabn_D_Stat 3 "FilteringComplete" 2 "FilteringOn" 1 "FilteringOff" 0 "NotKnown" ;
VAL_ 551 PwRnngBoardSwtch_D_Rq 3 "NotUsed" 2 "DeployUnlocked" 1 "AlwaysActive" 0 "Inactive" ;
VAL_ 551 PwRnngBoardMde_D_Rq 0 "Inactive" 1 "Off" 2 "Out" 3 "Auto" ;
VAL_ 551 PwRnngBoardT_D_Rq 3 "NotUsed" 2 "Timer2" 1 "Timer1" 0 "Inactive" ;
VAL_ 551 OneTEditActv_B_RqMnu 1 "Yes" 0 "No" ;
VAL_ 551 Cntr_Plg_Mode_Cmd 1 "Enable" 0 "Disable" ;
VAL_ 551 BattTracLoThres_D_Rq 7 "NotUsed" 6 "Thres80km_50mi" 5 "Thres50km_31mi" 4 "Thres30km_18mi" 3 "Thres50mi_80km" 2 "Thres30mi_48km" 1 "Thres20mi_32km" 0 "Null" ;
VAL_ 551 ChrgCrdLckEnbl_B_Stat 1 "Enable" 0 "Disable" ;
VAL_ 551 Btt_L_Actl2 127 "Faulty" 126 "NoDataExists" ;
VAL_ 1006 PersIndexIpmb_D_Actl 7 "Unused_3" 6 "Unused_2" 5 "Unused_1" 4 "Vehicle" 3 "PERS_4" 2 "PERS_3" 1 "PERS_2" 0 "PERS_1" ;
VAL_ 1123 GpsUtcYr_No_Actl 31 "Fault" ;
VAL_ 1123 GpsUtcMnth_No_Actl 15 "Fault" ;
VAL_ 1123 GPS_UTC_seconds 63 "Fault" 62 "Unknown" ;
VAL_ 1123 GPS_UTC_minutes 63 "Fault" 62 "Unknown" ;
VAL_ 1123 GPS_UTC_hours 31 "Invalid" 30 "Unknown" ;
VAL_ 1123 GPS_Compass_direction 7 "NorthWest" 6 "West" 5 "SouthWest" 4 "South" 3 "SouthEast" 2 "East" 1 "NorthEast" 0 "North" ;
VAL_ 1123 GPS_Actual_vs_Infer_pos 1 "Inferred_Position" 0 "Actual_Postition" ;
VAL_ 1123 Gps_B_Falt 1 "Yes" 0 "No" ;
VAL_ 1123 GPS_Pdop 31 "Invalid" 30 "Unknown" ;
VAL_ 1122 GPS_Longitude_Minutes 63 "Fault" 62 "Unknown" ;
VAL_ 1122 GPS_Longitude_Min_dec 16383 "Invalid" 16382 "Unknown" ;
VAL_ 1122 GPS_Longitude_Degrees 511 "Fault" 510 "Unknown" ;
VAL_ 1122 GPS_Latitude_Minutes 63 "Fault" 62 "Unknown" ;
VAL_ 1122 GPS_Latitude_Min_dec 16383 "Invalid" 16382 "Unknown" ;
VAL_ 1122 GPS_Latitude_Degrees 255 "Invalid" 254 "Unknown" ;
VAL_ 1122 GpsHsphLongEast_D_Actl 0 "Invalid" 1 "Eastern" 2 "Western" 3 "Fault" ;
VAL_ 1122 GpsHsphLattSth_D_Actl 3 "Fault" 2 "Northern" 1 "Southern" 0 "Invalid" ;
VAL_ 1003 TailLghtLoadMde_D_Stat 7 "Faulty" 6 "NotUsed_2" 5 "NotUsed_1" 4 "TailLightModeOverride" 3 "FalrModeActive" 2 "HitchLoadModeActive" 1 "PayloadModeActive" 0 "NoTailLightActive" ;
VAL_ 1003 PersRecallSrc_D_Actl 7 "NotUsed_3" 6 "NotUsed_2" 5 "NotUsed_1" 4 "MemorySwitch" 3 "RemoteStart" 2 "KeyFob" 1 "CenterStack" 0 "Null" ;
VAL_ 1003 Pers4Key_D_Stat 3 "NotUsed_1" 2 "KeyUnAssociated" 1 "KeyAssociated" 0 "Null" ;
VAL_ 1003 Pers3Key_D_Stat 3 "NotUsed_1" 2 "KeyUnAssociated" 1 "KeyAssociated" 0 "Null" ;
VAL_ 1003 Pers2Key_D_Stat 3 "NotUsed_1" 2 "KeyUnAssociated" 1 "KeyAssociated" 0 "Null" ;
VAL_ 1003 Pers1Key_D_Stat 3 "NotUsed_1" 2 "KeyUnAssociated" 1 "KeyAssociated" 0 "Null" ;
VAL_ 1003 EmPrflNo_D_Stat 7 "NotUsed_3" 6 "NotUsed_2" 5 "NotUsed_1" 4 "Pers4" 3 "Pers3" 2 "Pers2" 1 "Pers1" 0 "Null" ;
VAL_ 1003 EmPrflKeyAssoc_D_Stat 7 "WrongDevice" 6 "KeyAssociateFailed" 5 "KeyAssociateSuccess" 4 "KeyAlreadyInUse" 3 "KeyDisassociated" 2 "KeyAssociationExited" 1 "KeyAssociationEntered" 0 "Null" ;
VAL_ 1003 VehKeyActv_D_Stat 15 "NotUsed7" 14 "NotUsed6" 13 "NotUsed5" 12 "NotUsed4" 11 "NotUsed3" 10 "NotUsed2" 9 "NotUsed1" 8 "Key8Active" 7 "Key7Active" 6 "Key6Active" 5 "Key5Active" 4 "Key4Active" 3 "Key3Active" 2 "Key2Active" 1 "Key1Active" 0 "NoKeyActive" ;
VAL_ 1003 PersNoPos_D_Actl 7 "Unused_3" 6 "Unused_2" 5 "Unused_1" 4 "Vehicle" 3 "PERS_4" 2 "PERS_3" 1 "PERS_2" 0 "PERS_1" ;
VAL_ 1003 PersSetupRestr_D_Actl 3 "Non_Moveable_Person" 2 "Moveable_Person" 1 "Vehicle" 0 "Factory" ;
VAL_ 1003 PersSetupAccessCtrl 1 "Limited" 0 "Full" ;
VAL_ 1003 PersConflict_D_Actl 1 "Conflict" 0 "No_Conflict" ;
VAL_ 1003 AssocConfirm_D_Actl 0 "None" 7 "Associate" 6 "Keycode_Rejected" 5 "Keycode_Accepted" 4 "In_Progress" 3 "Erase" 2 "Duplicate" 1 "Disassociate" ;
VAL_ 1003 PersNo_D_Actl 7 "Unused_3" 6 "Unused_2" 5 "NotDetermined" 4 "Vehicle" 3 "PERS_4" 2 "PERS_3" 1 "PERS_2" 0 "PERS_1" ;
VAL_ 580 BattTracVrtOck_B_Rq 1 "Yes" 0 "No" ;
VAL_ 994 PersCtaSplitView_D_Rq 3 "EnabledFull" 2 "Enabled_180SwitchOnly" 1 "Disabled" 0 "Null" ;
VAL_ 994 PersStore_D_Rq 7 "Unused_2" 6 "Unused_1" 5 "Vehicle" 4 "PERS_4" 3 "PERS_3" 2 "PERS_2" 1 "PERS_1" 0 "Null" ;
VAL_ 994 Pers4OptIn_B_Stats 1 "OPTED_IN" 0 "NOT_OPTED_IN" ;
VAL_ 994 Pers3OptIn_B_Stats 1 "OPTED_IN" 0 "NOT_OPTED_IN" ;
VAL_ 994 Pers2OptIn_B_Stats 1 "OPTED_IN" 0 "NOT_OPTED_IN" ;
VAL_ 994 Pers1OptIn_B_Stats 1 "OPTED_IN" 0 "NOT_OPTED_IN" ;
VAL_ 994 CtrStkPersIndex_D_Actl 7 "Unused_3" 6 "Unused_2" 5 "Unused_1" 4 "Vehicle" 3 "PERS_4" 2 "PERS_3" 1 "PERS_2" 0 "PERS_1" ;
VAL_ 994 CtrStkDsplyOp_D_Rq 7 "Unused_2" 6 "Unused_1" 5 "Copy" 4 "Restore" 3 "Upload" 2 "Set" 1 "Query" 0 "Null" ;
VAL_ 992 MsgCntrPersIndex_D_Rq 7 "Unused_3" 6 "Unused_2" 5 "Unused_1" 4 "Vehicle" 3 "PERS_4" 2 "PERS_3" 1 "PERS_2" 0 "PERS_1" ;
VAL_ 992 MsgCntrDsplyOp_D_Rq 7 "Unused_2" 6 "Unused_1" 5 "Copy" 4 "Restore" 3 "Upload" 2 "Set" 1 "Query" 0 "Null" ;
VAL_ 820 AhbStatGfhbFdbk_D_Actl 3 "GfhbHighBeamFullyOn" 2 "GfhbHighBeamPartlyOn" 1 "GfhbHighBeamOff" 0 "GfhbUnavailable" ;
VAL_ 820 HeadLghtDrvSide_B_Stat 1 "Left_Hand_Traffic" 0 "Right_Hand_Traffic" ;
VAL_ 820 Adaptive_Hdlmp_Fault 1 "Yes" 0 "No" ;
VAL_ 820 TurnLampFrOut_B_Stat 1 "Out" 0 "Null" ;
VAL_ 820 TurnLampFlOut_B_Stat 1 "Out" 0 "Null" ;
VAL_ 817 ChildLckMde_B_Stat 1 "Enable" 0 "Disable" ;
VAL_ 817 VehLckInd_D_Rq 3 "NotUsed" 2 "On_Day" 1 "On_Night" 0 "Off" ;
VAL_ 817 DrTgateOpen_B_Rq 1 "Open" 0 "Null" ;
VAL_ 817 DrTgateExtSwMde_B_Stat 1 "Enable" 0 "Disable" ;
VAL_ 817 Remote_Device_Feedback 7 "Unused3" 6 "Unused2" 5 "Unused1" 4 "Shutdown" 3 "Running" 2 "Starting" 1 "Acknowledge" 0 "Null" ;
VAL_ 817 Veh_Lock_Requestor 31 "Walk_Away_Locking" 30 "Remote_Park_Assist" 29 "DoorsOffToOn_Smart_Unlock" 28 "Rgtm_Shutlock_Switch" 27 "Boundary_Alert" 26 "Transit_Vehicle_Relock" 25 "Transit_Cargo_Relock" 24 "Transit_Ajar_Lock" 23 "Diagnostics" 22 "Console_Lock" 21 "Child_Lock" 20 "Double_Lock" 19 "Passive_Pasenger" 18 "Passive_Driver" 17 "Slam_Lock_Protect" 16 "SYNC" 15 "Passport" 14 "Passive_Smart_Unlock" 13 "Autorelock" 12 "RemoteStart" 0 "Null" 1 "Autolock" 11 "Smart_Unlock" 10 "Sliding_Door" 9 "Passive" 8 "Remote" 7 "Programming" 6 "Powerslide" 5 "Keypad" 4 "Key_Cylinder" 3 "Interior" 2 "Auto_Unlock" ;
VAL_ 817 R_Pwr_Sliding_Dr_Rqst 1 "Active" 0 "Null" ;
VAL_ 817 Power_Liftgate_Rqst 1 "Active" 0 "Null" ;
VAL_ 817 Power_Decklid_Rqst 1 "Active" 0 "Null" ;
VAL_ 817 L_Pwr_Sliding_Dr_Rqst 1 "Active" 0 "Null" ;
VAL_ 817 Veh_Lock_Sub_Id 15 "Unused7" 14 "Unused6" 13 "Unused5" 12 "Unused4" 11 "Unused3" 10 "Unused2" 9 "Unused1" 8 "Customer_8" 7 "Customer_7" 6 "Customer_6" 5 "Customer_5" 4 "Customer_4" 3 "Customer_3" 2 "Customer_2" 1 "Customer_1" 0 "Null" ;
VAL_ 817 Veh_Lock_Status 3 "UNLOCK_DRV" 2 "UNLOCK_ALL" 1 "LOCK_ALL" 0 "LOCK_DBL" ;
VAL_ 817 ChildLck_D_Dsply 3 "NOT_SUPPORTED" 2 "ERROR" 1 "CHILD_UNLOCK" 0 "CHILD_LOCK" ;
VAL_ 817 WindowLockout_B_Stat 1 "Locked" 0 "Unlock" ;
VAL_ 817 Lockmsgtxt_D_Rq 7 "MSG7" 6 "MSG6" 5 "MSG5" 4 "MSG4" 3 "MSG3" 2 "MSG2" 1 "MSG1" 0 "NO_WARNING" ;
VAL_ 817 FobComm_D_Stat 3 "NotUsed" 2 "RemEngStartOK" 1 "RemEngStartFail" 0 "Null" ;
VAL_ 817 LockInhibit 1 "Inhibit" 0 "No_Inhibit" ;
VAL_ 129 SelDrvMdeSwtch4_D_Stat4 3 "Faulty" 2 "Pressed" 1 "NotPressed" 0 "Null" ;
VAL_ 129 EngExhMdeQuiet_B_RqDrv2 1 "Pressed" 0 "Not_Pressed" ;
VAL_ 129 SelDrvMdeSwtch_D_Stat4 3 "Faulty" 2 "SwitchState2" 1 "SwitchState1" 0 "NotPressed" ;
VAL_ 129 SteWhlSwtchView_B_Stat 1 "Pressed" 0 "Not_Pressed" ;
VAL_ 129 SteWhlSwtchSet_B_Stat 1 "Pressed" 0 "Not_Pressed" ;
VAL_ 129 SteWhlSwtchPhon_B_Stat 1 "Pressed" 0 "Not_Pressed" ;
VAL_ 129 SteWhlSwtchNav_B_Stat 1 "Pressed" 0 "Not_Pressed" ;
VAL_ 129 SteWhlSwtchMed_B_Stat 1 "Pressed" 0 "Not_Pressed" ;
VAL_ 129 SteWhlSwtchIod_B_Stat 1 "Pressed" 0 "Not_Pressed" ;
VAL_ 129 SteWhlSwtchHud_B_Stat 1 "Pressed" 0 "Not_Pressed" ;
VAL_ 129 SteWhlSwtchBack_B_Stat 1 "Pressed" 0 "Not_Pressed" ;
VAL_ 129 SteWhlSwtchMenu_B_Stat 1 "Pressed" 0 "Not_Pressed" ;
VAL_ 129 SteEffortInc_B_RqDrv 1 "Pressed" 0 "Not_Pressed" ;
VAL_ 129 SelDrvMdeInc_B_RqDrv 1 "Pressed" 0 "Not_Pressed" ;
VAL_ 129 SelDrvMdeDec_B_RqDrv 1 "Pressed" 0 "Not_Pressed" ;
VAL_ 129 SuspDampInc_B_RqDrv 1 "Pressed" 0 "Not_Pressed" ;
VAL_ 129 SteWhlSwtchUp_B_Stat 1 "Pressed" 0 "Not_Pressed" ;
VAL_ 129 SteWhlSwtchRght_B_Stat 1 "Pressed" 0 "Not_Pressed" ;
VAL_ 129 SteWhlSwtchOk_B_Stat 1 "Pressed" 0 "Not_Pressed" ;
VAL_ 129 SteWhlSwtchLeft_B_Stat 1 "Pressed" 0 "Not_Pressed" ;
VAL_ 129 SteWhlSwtchDown_B_Stat 1 "Pressed" 0 "Not_Pressed" ;
VAL_ 129 SteWhlSwtchHome_B_Stat 1 "Pressed" 0 "Not_Pressed" ;
VAL_ 129 SteWhlSwtchInfo_B_Stat 1 "Pressed" 0 "Not_Pressed" ;
VAL_ 129 PoliceAux4Swtch_B_Stat 1 "Switch_Active" 0 "Switch_Not_Active" ;
VAL_ 129 PoliceAux3Swtch_B_Stat 1 "Switch_Active" 0 "Switch_Not_Active" ;
VAL_ 129 PoliceAux2Swtch_B_Stat 1 "Switch_Active" 0 "Switch_Not_Active" ;
VAL_ 129 PoliceAux1Swtch_B_Stat 1 "Switch_Active" 0 "Switch_Not_Active" ;
VAL_ 129 SelDrvMdeSwtch3_D_Stat4 3 "Faulty" 2 "Pressed" 1 "NotPressed" 0 "Null" ;
VAL_ 129 SelDrvMdeSwtch2_D_Stat4 3 "Faulty" 2 "Pressed" 1 "NotPressed" 0 "Null" ;
VAL_ 129 SelDrvMdeSwtch1_D_Stat4 3 "Faulty" 2 "Pressed" 1 "NotPressed" 0 "Null" ;
VAL_ 854 Dsp_RotAddrBtnEv_St 15 "NotUsed_1" 14 "Pos_7Steps" 13 "Pos_6Steps" 12 "Pos_5Steps" 11 "Pos_4Steps" 10 "Pos_3Steps" 9 "Pos_2Steps" 8 "Pos_1Step" 7 "NotPressed" 6 "Neg_1Steps" 5 "Neg_2Steps" 4 "Neg_3Steps" 3 "Neg_4Steps" 2 "Neg_5Steps" 1 "Neg_6Steps" 0 "Neg_7Steps" ;
VAL_ 854 SelDrvMdeButtn_B_Stat 1 "Pressed" 0 "Not_Pressed" ;
VAL_ 854 SteEffortButtn_B_Stat 1 "Pressed" 0 "Not_Pressed" ;
VAL_ 854 SelDrvMdeSwtch_D_Stat2 3 "Faulty" 2 "SwitchState2" 1 "SwitchState1" 0 "NotPressed" ;
VAL_ 854 CC_Fr_Stat_User_Adj 7 "Unused4" 6 "RHS_AUTO_St_Selection" 5 "LHS_AUTO_St_Selection" 4 "DrvrFcsdMde_Selection" 3 "Fr_Blwr_Spd_Selection" 2 "FRHS_SetPt_Selection" 1 "FLHS_SetPt_Selection" 0 "None" ;
VAL_ 854 EngExhMdeQuiet_B_RqDrv 1 "Pressed" 0 "Not_Pressed" ;
VAL_ 854 LnchCtlSys_B_RqDrv 1 "Pressed" 0 "Not_Pressed" ;
VAL_ 854 Front_Blower_Indicate 15 "Display_Blank" 14 "14_Indicators_On" 13 "13_Indicators_On" 12 "12_Indicators_On" 11 "11_Indicators_On" 10 "10_Indicators_On" 9 "9_Indicators_On" 8 "8_Indicators_On" 7 "7_Indicators_On" 6 "6_Indicators_On" 5 "5_Indicators_On" 4 "4_Indicators_On" 3 "3_Indicators_On" 2 "2_Indicators_On" 1 "1_Indicator_On" 0 "Indicators_Off" ;
VAL_ 854 CC_Diagnostics_Active 1 "Yes" 0 "No" ;
VAL_ 854 RHS_Temp_Display_Digit3 2 "_5" 1 "_0" 0 "OFF" ;
VAL_ 854 LHS_Temp_Display_Digit3 2 "_5" 1 "_0" 0 "OFF" ;
VAL_ 854 EATC_RHS_Units 2 "Fahrenheit" 1 "Celsius" 0 "Off" ;
VAL_ 854 EATC_LHS_Units 2 "Fahrenheit" 1 "Celsius" 0 "Off" ;
VAL_ 854 LHS_Auto_Seat_Btn_Stt 3 "Unused" 2 "Disabled" 1 "Active" 0 "Enabled_Inactive" ;
VAL_ 854 RHS_Auto_Seat_Btn_Stt 3 "Unused" 2 "Disabled" 1 "Active" 0 "Enabled_Inactive" ;
VAL_ 549 TjaLcEnbl_D_DrvRq 0 "Inactive" 1 "Off" 2 "On" 3 "NotUsed" ;
VAL_ 549 CCOI_PolicyClient_St2 15 "NotUsed_4" 14 "NotUsed_3" 13 "NotUsed_2" 12 "NotUsed_1" 11 "DataStorageError" 10 "StateMachineInconsistent" 9 "UnrecoverableSyncError" 8 "OnBoardSyncFailed" 7 "OnBoardImplemented" 6 "OnBoardSynchronized" 5 "OnBoardSynchronizing" 4 "OnBoardSyncNeeded" 3 "OffBoardUpdatePending" 2 "OnBoardUpdatePending" 1 "Waiting" 0 "Null" ;
VAL_ 549 FactoryReset_Rq2 1 "ResetFactoryDefaults" 0 "Inactive" ;
VAL_ 549 BattTracLoThres_D_Rq2 7 "NotUsed" 6 "Thres80km_50mi" 5 "Thres50km_31mi" 4 "Thres30km_18mi" 3 "Thres50mi_80km" 2 "Thres30mi_48km" 1 "Thres20mi_32km" 0 "Null" ;
VAL_ 549 NavIod_D_Rq 7 "NotUsed_5" 6 "NotUsed_4" 5 "NotUsed_3" 4 "NotUsed_2" 3 "NotUsed_1" 2 "ModeChange" 1 "VideoOutput" 0 "NoRequest" ;
VAL_ 549 IPC_MyKeyVolLimit_St 0 "Invalid" 1 "Off" 2 "On" ;
VAL_ 549 HdcOn_B_Rq 1 "On" 0 "Off" ;
VAL_ 549 IPC_Attn_Info_Audio 7 "Unknown" 6 "Attenuation_6" 5 "Attenuation_5" 4 "Attenuation_4" 3 "Attenuation_3" 2 "Attenuation_2" 1 "Attenuation_1" 0 "No_Attenuation_of_Audio" ;
VAL_ 549 BeltminderAudioMute 2 "On" 1 "Off" 0 "Invalid" ;
VAL_ 549 Power_Up_Chime_Modules 1 "Active" 0 "Inactive" ;
VAL_ 549 Chime_Source 2 "Cluster" 1 "Infotainment_Sys" 0 "Invalid" ;
VAL_ 549 IPC_New_Attn_Event 1 "Active" 0 "Inactive" ;
VAL_ 549 WwaActv_B_Stat 1 "Active" 0 "Inactive" ;
VAL_ 549 MetricActv_B_Dsply 1 "Active" 0 "Inactive" ;
VAL_ 549 HudVertSzMnuOn_B_Rq 1 "On" 0 "Off" ;
VAL_ 549 HudVertMnuOn_B_Rq 1 "Yes" 0 "No" ;
VAL_ 549 HudRotatMnuOn_B_Rq 1 "Yes" 0 "No" ;
VAL_ 549 HudCntntMnuOn_B_Rq 1 "On" 0 "Off" ;
VAL_ 549 HudBrightMnuOn_B_Rq 1 "Yes" 0 "No" ;
VAL_ 549 StrtInGearOk_D_Stat 3 "NotUsed" 2 "Accepted" 1 "NotAccepted" 0 "Null" ;
VAL_ 935 CtaAlrtRight2_D_Stat 7 "NotUsed3" 6 "NotUsed2" 5 "NotUsed1" 4 "AlertZone4" 3 "AlertZone3" 2 "AlertZone2" 1 "AlertZone1" 0 "Off" ;
VAL_ 935 BttRight_D_Stat 7 "NotUsed" 6 "Disabled" 5 "Off" 4 "OffTemp" 3 "NotConnected" 2 "Pending" 1 "Connected" 0 "NotDetermined" ;
VAL_ 935 BttRight_D_RqDrv 3 "NotUsed" 2 "Request" 1 "NoRequest" 0 "Null" ;
VAL_ 935 CtaBrkRightMsgTxt_B_Rq 1 "Enable" 0 "Disable" ;
VAL_ 935 CtaRightBrkEnbl_B_Rq 1 "Enable" 0 "Disable" ;
VAL_ 935 CtaRightBrkDecel_B_Rq 1 "Enable" 0 "Disable" ;
VAL_ 935 CtaSnsRight_D_Stat 3 "Invalid" 2 "System_Failure" 1 "Blocked" 0 "Clear" ;
VAL_ 935 CtaAlrtRight_D_Stat 1 "On" 0 "Off" ;
VAL_ 935 CtaRight_D_Stat 7 "NotUsed_3" 6 "NotUsed_2" 5 "NotUsed_1" 4 "Invalid" 3 "Disabled" 2 "On" 1 "Trailer_Tow_Off" 0 "Off" ;
VAL_ 935 SodRight_D_Stat 7 "NotUsed_3" 6 "NotUsed_2" 5 "NotUsed_1" 4 "Invalid" 3 "Disabled" 2 "On" 1 "Trailer_Tow_Off" 0 "Off" ;
VAL_ 935 SodSnsRight_D_Stat 3 "Second_Warning_Audio" 2 "System_Failure" 1 "Blocked" 0 "Clear" ;
VAL_ 935 SodAlrtRight_D_Stat 3 "Bulb_Proveout" 2 "Flash" 1 "On" 0 "Off" ;
VAL_ 935 SodDetctRight_D_Stat 4 "Sensor_Blocked" 3 "Sensor_Fault" 2 "Flash_On" 1 "Alert_On" 0 "AlertOff_FlashOff_SensrClr" ;
SIG_GROUP_ 932 Profile1A_SigGroup_HS1_3A4 1 : VehOnSrc2_D_Stat;
